VERSION ""

NS_ :

BS_:

BU_: PowertrainControlModule AtmosphericSensor SafetyRestraintSystem2 Aftertreatment_2_GasOutlet Aftertreatment_2_GasIntake DieselParticulateFilterControl Turbocharger SafetyRestraintSystem1 CabDisplay2 Aftertreatment_1_GasOutlet Aftertreatment_1_GasIntake OnBoardDataLogger OffBoardDiagnosticTool2 OffBoardDiagnosticTool1 FileServer ParkingBrakeController SeatController2 FanDriveController SteeringColumnUnit CommunicationUnitRadio CommunicationUnitSatellite CommunicationUnitCellular PropulsionBatteryCharger ChassisController2 ChassisController1 EngineValveControl AuxiliaryHeater2 AuxiliaryHeater1 ClutchUnit RampControl InformationSystem1 SuspensionSystemController2 OilSensor VehicleDynamicStability ExhaustEmissionController TransmissionDisplay2 TransmissionDisplay1 ClimateControl2 WaterPumpController RearAxleSteeringController LightingOperatorControl SeatController1 IgnitionController2 IgnitionController1 TirePressureController CabController2 CabController1 PneumaticSystemController SuspensionSystemController1 HydraulicPumpController EnduranceBrakingSystem RetarderExhaustEngine2 OnBoardDiagnosticUnit HeadwayController RetarderExhaustEngine1 CabDisplay1 ManagementComputer VirtualTerminal OffVehicleGateway PowerTakeOffFront HitchControl AuxiliaryValveControl BodyController TractorTrailerBridge1 StarterSystem ElectricalSystem VehicleSecurity VehicleNavigation AerodynamicControl ElectricalChargingSystem ClimateControl1 TripRecorder InstrumentCluster SuspensionDriveAxle2 SuspensionDriveAxle1 SuspensionSteerAxle SteeringController FuelSystem CruiseControl RetarderDriveline RetarderEngine BrakesDriveAxle2 BrakesDriveAxle1 BrakesSystemController BrakesSteerAxle AxleDrive2 AxleDrive1 AxleSteering PowerTakeOff ShiftConsoleSecondary ShiftConsolePrimary Transmission2 Transmission1 Engine2 Engine1
VAL_TABLE_ FMI 22 "Data Drifted Low" 21 "Data Drifted High" 20 "Received Network Data In Error" 0 "Above normal (most severe)" 1 "Below normal (most severe)" 2 "Data erratic" 3 "Voltage above normal" 4 "Voltage below normal" 5 "Current below normal" 6 "Current above normal" 7 "Mechanical system not responding" 8 "Abnormal frequency" 9 "Abnormal update rate" 10 "Abnormal rate of change" 11 "Root cause not known" 12 "Bad intelligent device" 13 "Out of calibration" 14 "Special intstructions" 15 "Above normal (least severe)" 16 "Above normal (moderately severe)" 17 "Below normal (least severe)" 18 "Below normal (moderately severe)" 19 "Received network data in error" 31 "Condition Exists" ;
VAL_TABLE_ Ports 21 "Global (All ports)" 0 "Local" ;

BO_ 3221225472 VECTOR__INDEPENDENT_SIG_MSG: 0 Vector__XXX
 SG_ NumberOfMembersInWorkingSet : 0|8@1+ (1,0) [0|0] "" Vector__XXX
 SG_ SourceAddress : 0|8@1+ (1,0) [0|0] "" Vector__XXX
 SG_ NncntnuslyMonitoredSystemsStatus : 0|16@1+ (1,0) [0|0] "" Vector__XXX
 SG_ NncntnslyMonitoredSystemsSupport : 0|16@1+ (1,0) [0|0] "" Vector__XXX
 SG_ CntnslyMntrdSystmsSupport_Status : 0|8@1+ (1,0) [0|0] "" Vector__XXX
 SG_ AETCTorqueValue : 0|16@1+ (1,0) [0|64255] "Nm" Vector__XXX
 SG_ TrailerWeight : 0|16@1+ (2,0) [0|128510] "kg" Vector__XXX
 SG_ ReferenceTirePressSetting : 0|8@1+ (8,0) [0|2000] "kPa" Vector__XXX
 SG_ ReferenceTirePress : 0|8@1+ (8,0) [0|2000] "kPa" Vector__XXX
 SG_ TirePressThresholdDetection : 0|3@1+ (1,0) [0|7] "" Vector__XXX
 SG_ TireAirLeakageRate : 0|16@1+ (0.1,0) [0|6425.5] "Pa/s" Vector__XXX
 SG_ CTIWheelEndElectricalFault : 0|2@1+ (1,0) [0|3] "" Vector__XXX
 SG_ CTITireStatus : 0|2@1+ (1,0) [0|3] "" Vector__XXX
 SG_ CTIWheelSensorStatus : 0|2@1+ (1,0) [0|3] "" Vector__XXX
 SG_ TireTemp : 0|16@1+ (0.03125,-273) [-273|1734.96875] "deg C" Vector__XXX
 SG_ TirePress : 0|8@1+ (4,0) [0|1000] "kPa" Vector__XXX
 SG_ EngTurningGearEngaged : 0|2@1+ (1,0) [0|3] "" Vector__XXX
 SG_ AETCSpeedValue : 0|16@1+ (0.125,0) [0|8031.875] "rpm" Vector__XXX

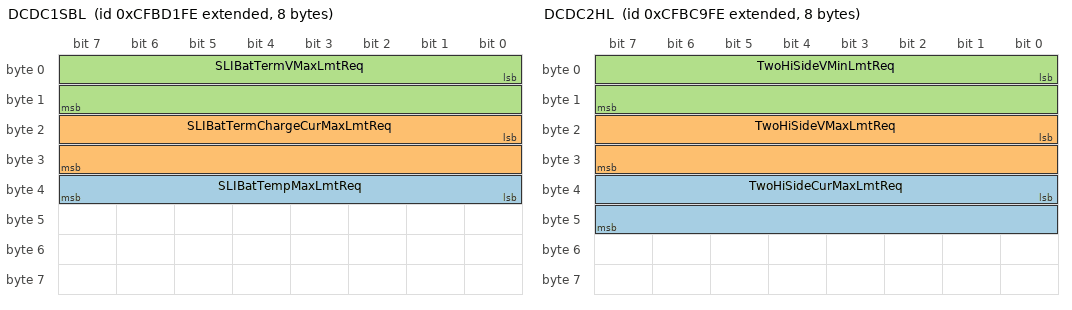
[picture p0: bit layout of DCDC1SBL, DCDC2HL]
BO_ 2365313534 DCDC1SBL: 8 Vector__XXX
 SG_ SLIBatTempMaxLmtReq : 32|8@1+ (1,-40) [-40|210] "캜" Vector__XXX
 SG_ SLIBatTermChargeCurMaxLmtReq : 16|16@1+ (0.05,0) [0|3212.75] "A" Vector__XXX
 SG_ SLIBatTermVMaxLmtReq : 0|16@1+ (0.01,0) [0|642.55] "V" Vector__XXX

BO_ 2566639870 DCDC1CFG1: 19 Vector__XXX
 SG_ OneLowSideVBuckDefaultSetting : 136|16@1+ (0.01,0) [0|642.55] "V" Vector__XXX
 SG_ SLIBatTempMaxLmtSetting : 128|8@1+ (1,-40) [-40|210] "캜" Vector__XXX
 SG_ SLIBatTermChargeCurMaxLmtSetting : 112|16@1+ (0.05,0) [0|3212.75] "A" Vector__XXX
 SG_ SLIBatTermVMaxLmtSetting : 96|16@1+ (0.01,0) [0|642.55] "V" Vector__XXX
 SG_ OneLowSideCurMaxLmtSetting : 80|16@1+ (0.05,0) [0|3212.75] "A" Vector__XXX
 SG_ OneLowSideVMaxLmtSetting : 64|16@1+ (0.01,0) [0|642.55] "V" Vector__XXX
 SG_ OneLowSideVMinLmtSetting : 48|16@1+ (0.01,0) [0|642.55] "V" Vector__XXX
 SG_ OneHiSideCurMaxLmtSetting : 32|16@1+ (0.05,0) [0|3212.75] "A" Vector__XXX
 SG_ OneHiSideVMaxLmtSetting : 16|16@1+ (0.05,0) [0|3212.75] "V" Vector__XXX
 SG_ OneHiSideVMinLmtSetting : 0|16@1+ (0.05,0) [0|3212.75] "V" Vector__XXX

BO_ 2566639614 DCDC1LD: 16 Vector__XXX
 SG_ OneTotalLowSideCharge : 96|32@1+ (100,0) [0|421108121500] "Ah" Vector__XXX
 SG_ OneTotalHiSideCharge : 64|32@1+ (100,0) [0|421108121500] "Ah" Vector__XXX
 SG_ OneTotalLowSideEnergy : 32|32@1+ (100,0) [0|421108121500] "Watt-hour" Vector__XXX
 SG_ OneTotalHiSideEnergy : 0|32@1+ (100,0) [0|421108121500] "Watt-hour" Vector__XXX

BO_ 2633748222 CRSS: 8 Vector__XXX
 SG_ SPNModifiedStatus : 48|2@1+ (1,0) [0|3] "" Vector__XXX
 SG_ SPNSA : 40|8@1+ (1,0) [0|255] "" Vector__XXX
 SG_ SPNDetailedStatus : 32|5@1+ (1,0) [0|31] "" Vector__XXX
 SG_ SPN : 16|19@1+ (1,0) [0|524287] "" Vector__XXX
 SG_ PortCmdStatus : 5|3@1+ (1,0) [0|7] "" Vector__XXX
 SG_ PortPendingChangesStatus : 4|1@1+ (1,0) [0|1] "" Vector__XXX
 SG_ Port : 0|4@1+ (1,0) [0|15] "" Vector__XXX

BO_ 2566639102 WSPT2: 19 Vector__XXX
 SG_ PlungerFiringOrderSetting : 144|4@1+ (1,0) [0|15] "" Vector__XXX
 SG_ RodLoadHiThreshold : 128|16@1+ (5,0) [0|321275] "kN" Vector__XXX
 SG_ CrankshaftSpdHiThreshold : 112|16@1+ (0.125,0) [0|8031.875] "rpm" Vector__XXX
 SG_ CrankshaftSpdLowThreshold : 96|16@1+ (0.125,0) [0|8031.875] "rpm" Vector__XXX
 SG_ DisPressHiThreshold : 80|16@1+ (5,0) [0|321275] "kPa" Vector__XXX
 SG_ SuctionPressHiThreshold : 64|16@1+ (0.1,-3212.7) [-3212.7|3212.8] "kPa" Vector__XXX
 SG_ SuctionPressLowThreshold : 48|16@1+ (0.1,-3212.7) [-3212.7|3212.8] "kPa" Vector__XXX
 SG_ GearBoxOilTempHiThreshold : 40|8@1+ (1,-40) [-40|210] "캜" Vector__XXX
 SG_ GearBoxOilTempLowThreshold : 32|8@1+ (1,-40) [-40|210] "캜" Vector__XXX
 SG_ GearBoxOilPressHiThreshold : 16|16@1+ (0.1,0) [0|6425.5] "kPa" Vector__XXX
 SG_ GearBoxOilPressLowThreshold : 0|16@1+ (0.1,0) [0|6425.5] "kPa" Vector__XXX

BO_ 2566638846 WSPH: 16 Vector__XXX
 SG_ VlvSeatOpHours : 96|32@1+ (1,0) [0|4211081215] "s" Vector__XXX
 SG_ PackingOpHours : 64|32@1+ (1,0) [0|4211081215] "s" Vector__XXX
 SG_ VlvOpHours : 32|32@1+ (1,0) [0|4211081215] "s" Vector__XXX
 SG_ MaintenanceIntervalHours : 0|32@1+ (1,0) [0|4211081215] "s" Vector__XXX

BO_ 2566638590 EEPCSI: 8 Vector__XXX
 SG_ DiagCount : 32|32@1+ (1,0) [0|4211081215] "" Vector__XXX
 SG_ DiagTime : 0|32@1+ (1,0) [0|4211081215] "s" Vector__XXX

BO_ 2365311486 DCDC2HL: 8 Vector__XXX
 SG_ TwoHiSideCurMaxLmtReq : 32|16@1+ (0.05,0) [0|3212.75] "A" Vector__XXX
 SG_ TwoHiSideVMaxLmtReq : 16|16@1+ (0.05,0) [0|3212.75] "V" Vector__XXX
 SG_ TwoHiSideVMinLmtReq : 0|16@1+ (0.05,0) [0|3212.75] "V" Vector__XXX

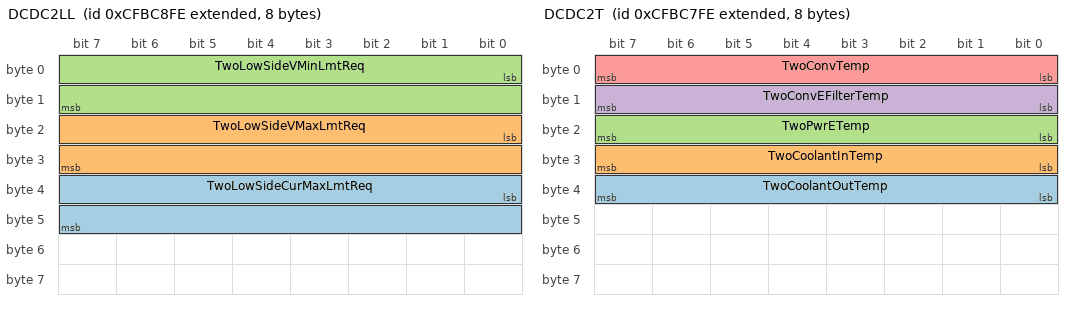
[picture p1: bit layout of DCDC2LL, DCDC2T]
BO_ 2365311230 DCDC2LL: 8 Vector__XXX
 SG_ TwoLowSideCurMaxLmtReq : 32|16@1+ (0.05,0) [0|3212.75] "A" Vector__XXX
 SG_ TwoLowSideVMaxLmtReq : 16|16@1+ (0.01,0) [0|642.55] "V" Vector__XXX
 SG_ TwoLowSideVMinLmtReq : 0|16@1+ (0.01,0) [0|642.55] "V" Vector__XXX

BO_ 2365310974 DCDC2T: 8 Vector__XXX
 SG_ TwoCoolantOutTemp : 32|8@1+ (1,-40) [-40|210] "캜" Vector__XXX
 SG_ TwoCoolantInTemp : 24|8@1+ (1,-40) [-40|210] "캜" Vector__XXX
 SG_ TwoPwrETemp : 16|8@1+ (1,-40) [-40|210] "캜" Vector__XXX
 SG_ TwoConvEFilterTemp : 8|8@1+ (1,-40) [-40|210] "캜" Vector__XXX
 SG_ TwoConvTemp : 0|8@1+ (1,-40) [-40|210] "캜" Vector__XXX

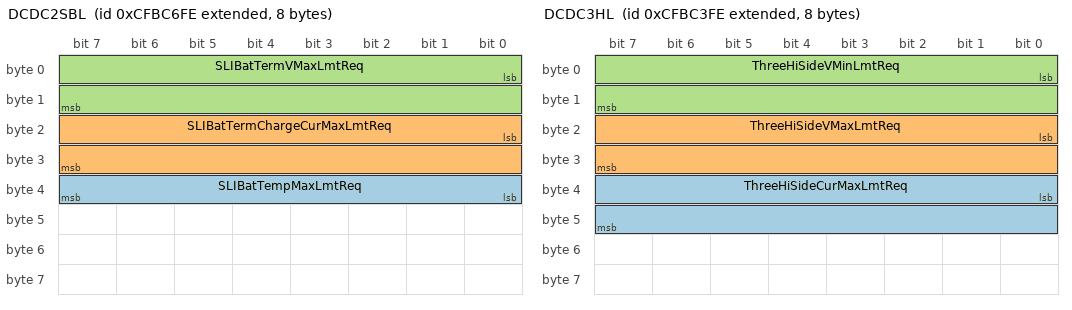
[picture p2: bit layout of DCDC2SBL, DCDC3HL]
BO_ 2365310718 DCDC2SBL: 8 Vector__XXX
 SG_ SLIBatTempMaxLmtReq : 32|8@1+ (1,-40) [-40|210] "캜" Vector__XXX
 SG_ SLIBatTermChargeCurMaxLmtReq : 16|16@1+ (0.05,0) [0|3212.75] "A" Vector__XXX
 SG_ SLIBatTermVMaxLmtReq : 0|16@1+ (0.01,0) [0|642.55] "V" Vector__XXX

BO_ 2566637054 DCDC2CFG1: 19 Vector__XXX
 SG_ TwoLowSideVBuckDefaultSetting : 136|16@1+ (0.01,0) [0|642.55] "V" Vector__XXX
 SG_ SLIBatTempMaxLmtSetting : 128|8@1+ (1,-40) [-40|210] "캜" Vector__XXX
 SG_ SLIBatTermChargeCurMaxLmtSetting : 112|16@1+ (0.05,0) [0|3212.75] "A" Vector__XXX
 SG_ SLIBatTermVMaxLmtSetting : 96|16@1+ (0.01,0) [0|642.55] "V" Vector__XXX
 SG_ TwoLowSideCurMaxLmtSetting : 80|16@1+ (0.05,0) [0|3212.75] "A" Vector__XXX
 SG_ TwoLowSideVMaxLmtSetting : 64|16@1+ (0.01,0) [0|642.55] "V" Vector__XXX
 SG_ TwoLowSideVMinLmtSetting : 48|16@1+ (0.01,0) [0|642.55] "V" Vector__XXX
 SG_ TwoHiSideCurMaxLmtSetting : 32|16@1+ (0.05,0) [0|3212.75] "A" Vector__XXX
 SG_ TwoHiSideVMaxLmtSetting : 16|16@1+ (0.05,0) [0|3212.75] "V" Vector__XXX
 SG_ TwoHiSideVMinLmtSetting : 0|16@1+ (0.05,0) [0|3212.75] "V" Vector__XXX

BO_ 2566636798 DCDC2LD: 16 Vector__XXX
 SG_ TwoTotalLowSideCharge : 96|32@1+ (100,0) [0|421108121500] "Ah" Vector__XXX
 SG_ TwoTotalHiSideCharge : 64|32@1+ (100,0) [0|421108121500] "Ah" Vector__XXX
 SG_ TwoTotalLowSideEnergy : 32|32@1+ (100,0) [0|421108121500] "Watt-hour" Vector__XXX
 SG_ TwoTotalHiSideEnergy : 0|32@1+ (100,0) [0|421108121500] "Watt-hour" Vector__XXX

BO_ 2365309950 DCDC3HL: 8 Vector__XXX
 SG_ ThreeHiSideCurMaxLmtReq : 32|16@1+ (0.05,0) [0|3212.75] "A" Vector__XXX
 SG_ ThreeHiSideVMaxLmtReq : 16|16@1+ (0.05,0) [0|3212.75] "V" Vector__XXX
 SG_ ThreeHiSideVMinLmtReq : 0|16@1+ (0.05,0) [0|3212.75] "V" Vector__XXX

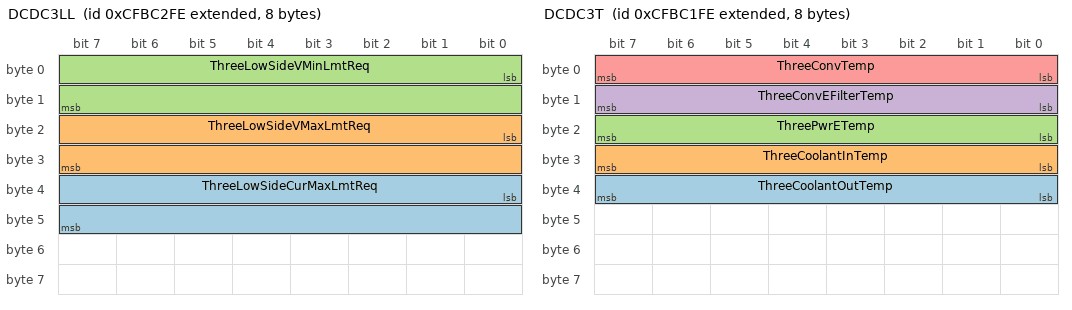
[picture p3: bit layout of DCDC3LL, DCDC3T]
BO_ 2365309694 DCDC3LL: 8 Vector__XXX
 SG_ ThreeLowSideCurMaxLmtReq : 32|16@1+ (0.05,0) [0|3212.75] "A" Vector__XXX
 SG_ ThreeLowSideVMaxLmtReq : 16|16@1+ (0.01,0) [0|642.55] "V" Vector__XXX
 SG_ ThreeLowSideVMinLmtReq : 0|16@1+ (0.01,0) [0|642.55] "V" Vector__XXX

BO_ 2365309438 DCDC3T: 8 Vector__XXX
 SG_ ThreeCoolantOutTemp : 32|8@1+ (1,-40) [-40|210] "캜" Vector__XXX
 SG_ ThreeCoolantInTemp : 24|8@1+ (1,-40) [-40|210] "캜" Vector__XXX
 SG_ ThreePwrETemp : 16|8@1+ (1,-40) [-40|210] "캜" Vector__XXX
 SG_ ThreeConvEFilterTemp : 8|8@1+ (1,-40) [-40|210] "캜" Vector__XXX
 SG_ ThreeConvTemp : 0|8@1+ (1,-40) [-40|210] "캜" Vector__XXX

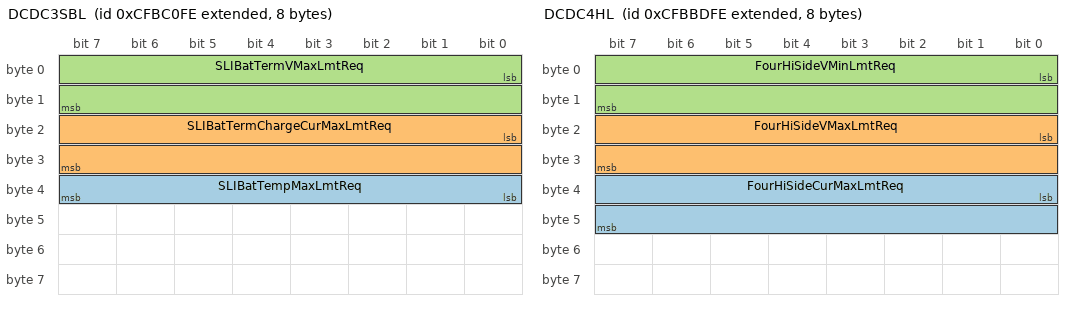
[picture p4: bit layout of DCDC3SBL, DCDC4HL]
BO_ 2365309182 DCDC3SBL: 8 Vector__XXX
 SG_ SLIBatTempMaxLmtReq : 32|8@1+ (1,-40) [-40|210] "캜" Vector__XXX
 SG_ SLIBatTermChargeCurMaxLmtReq : 16|16@1+ (0.05,0) [0|3212.75] "A" Vector__XXX
 SG_ SLIBatTermVMaxLmtReq : 0|16@1+ (0.01,0) [0|642.55] "V" Vector__XXX

BO_ 2566635518 DCDC3CFG1: 19 Vector__XXX
 SG_ ThreeLowSideVBuckDefaultSetting : 136|16@1+ (0.01,0) [0|642.55] "V" Vector__XXX
 SG_ SLIBatTempMaxLmtSetting : 128|8@1+ (1,-40) [-40|210] "캜" Vector__XXX
 SG_ SLIBatTermChargeCurMaxLmtSetting : 112|16@1+ (0.05,0) [0|3212.75] "A" Vector__XXX
 SG_ SLIBatTermVMaxLmtSetting : 96|16@1+ (0.01,0) [0|642.55] "V" Vector__XXX
 SG_ ThreeLowSideCurMaxLmtSetting : 80|16@1+ (0.05,0) [0|3212.75] "A" Vector__XXX
 SG_ ThreeLowSideVMaxLmtSetting : 64|16@1+ (0.01,0) [0|642.55] "V" Vector__XXX
 SG_ ThreeLowSideVMinLmtSetting : 48|16@1+ (0.01,0) [0|642.55] "V" Vector__XXX
 SG_ ThreeHiSideCurMaxLmtSetting : 32|16@1+ (0.05,0) [0|3212.75] "A" Vector__XXX
 SG_ ThreeHiSideVMaxLmtSetting : 16|16@1+ (0.05,0) [0|3212.75] "V" Vector__XXX
 SG_ ThreeHiSideVMinLmtSetting : 0|16@1+ (0.05,0) [0|3212.75] "V" Vector__XXX

BO_ 2566635262 DCDC3LD: 16 Vector__XXX
 SG_ ThreeTotalLowSideCharge : 96|32@1+ (100,0) [0|421108121500] "Ah" Vector__XXX
 SG_ ThreeTotalHiSideCharge : 64|32@1+ (100,0) [0|421108121500] "Ah" Vector__XXX
 SG_ ThreeTotalLowSideEnergy : 32|32@1+ (100,0) [0|421108121500] "Watt-hour" Vector__XXX
 SG_ ThreeTotalHiSideEnergy : 0|32@1+ (100,0) [0|421108121500] "Watt-hour" Vector__XXX

BO_ 2365308414 DCDC4HL: 8 Vector__XXX
 SG_ FourHiSideCurMaxLmtReq : 32|16@1+ (0.05,0) [0|3212.75] "A" Vector__XXX
 SG_ FourHiSideVMaxLmtReq : 16|16@1+ (0.05,0) [0|3212.75] "V" Vector__XXX
 SG_ FourHiSideVMinLmtReq : 0|16@1+ (0.05,0) [0|3212.75] "V" Vector__XXX

BO_ 2365308158 DCDC4LL: 8 Vector__XXX
 SG_ FourLowSideCurMaxLmtReq : 32|16@1+ (0.05,0) [0|3212.75] "A" Vector__XXX
 SG_ FourLowSideVMaxLmtReq : 16|16@1+ (0.01,0) [0|642.55] "V" Vector__XXX
 SG_ FourLowSideVMinLmtReq : 0|16@1+ (0.01,0) [0|642.55] "V" Vector__XXX

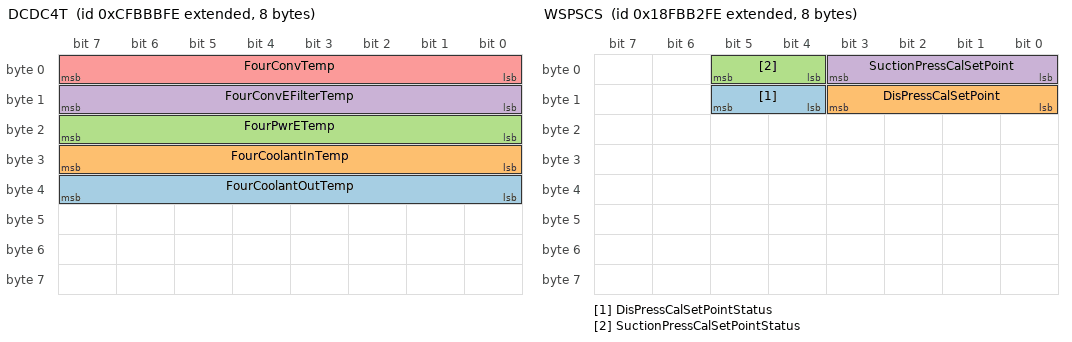
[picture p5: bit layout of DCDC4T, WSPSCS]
BO_ 2365307902 DCDC4T: 8 Vector__XXX
 SG_ FourCoolantOutTemp : 32|8@1+ (1,-40) [-40|210] "캜" Vector__XXX
 SG_ FourCoolantInTemp : 24|8@1+ (1,-40) [-40|210] "캜" Vector__XXX
 SG_ FourPwrETemp : 16|8@1+ (1,-40) [-40|210] "캜" Vector__XXX
 SG_ FourConvEFilterTemp : 8|8@1+ (1,-40) [-40|210] "캜" Vector__XXX
 SG_ FourConvTemp : 0|8@1+ (1,-40) [-40|210] "캜" Vector__XXX

BO_ 2365307646 DCDC4SBL: 8 Vector__XXX
 SG_ SLIBatTempMaxLmtReq : 32|8@1+ (1,-40) [-40|210] "캜" Vector__XXX
 SG_ SLIBatTermChargeCurMaxLmtReq : 16|16@1+ (0.05,0) [0|3212.75] "A" Vector__XXX
 SG_ SLIBatTermVMaxLmtReq : 0|16@1+ (0.01,0) [0|642.55] "V" Vector__XXX

BO_ 2566633982 DCDC4CFG1: 19 Vector__XXX
 SG_ FourLowSideVBuckDefaultSetting : 136|16@1+ (0.01,0) [0|642.55] "V" Vector__XXX
 SG_ SLIBatTempMaxLmtSetting : 128|8@1+ (1,-40) [-40|210] "캜" Vector__XXX
 SG_ SLIBatTermChargeCurMaxLmtSetting : 112|16@1+ (0.05,0) [0|3212.75] "A" Vector__XXX
 SG_ SLIBatTermVMaxLmtSetting : 96|16@1+ (0.01,0) [0|642.55] "V" Vector__XXX
 SG_ FourLowSideCurMaxLmtSetting : 80|16@1+ (0.05,0) [0|3212.75] "A" Vector__XXX
 SG_ FourLowSideVMaxLmtSetting : 64|16@1+ (0.01,0) [0|642.55] "V" Vector__XXX
 SG_ FourLowSideVMinLmtSetting : 48|16@1+ (0.01,0) [0|642.55] "V" Vector__XXX
 SG_ FourHiSideCurMaxLmtSetting : 32|16@1+ (0.05,0) [0|3212.75] "A" Vector__XXX
 SG_ FourHiSideVMaxLmtSetting : 16|16@1+ (0.05,0) [0|3212.75] "V" Vector__XXX
 SG_ FourHiSideVMinLmtSetting : 0|16@1+ (0.05,0) [0|3212.75] "V" Vector__XXX

BO_ 2566633726 DCDC4LD: 16 Vector__XXX
 SG_ FourTotalLowSideCharge : 96|32@1+ (100,0) [0|421108121500] "Ah" Vector__XXX
 SG_ FourTotalHiSideCharge : 64|32@1+ (100,0) [0|421108121500] "Ah" Vector__XXX
 SG_ FourTotalLowSideEnergy : 32|32@1+ (100,0) [0|421108121500] "Watt-hour" Vector__XXX
 SG_ FourTotalHiSideEnergy : 0|32@1+ (100,0) [0|421108121500] "Watt-hour" Vector__XXX

BO_ 2566633470 AT1IG4: 8 Vector__XXX
 SG_ O2PumpingCur : 0|16@1+ (0.001,-32.127) [-32.127|32.128] "mA" Vector__XXX

BO_ 2566633214 AT1OG4: 8 Vector__XXX
 SG_ O2PumpingCur : 0|16@1+ (0.001,-32.127) [-32.127|32.128] "mA" Vector__XXX

BO_ 2566632958 WSPH2: 8 Vector__XXX
 SG_ PwrEndTripHours : 32|32@1+ (1,0) [0|4211081215] "s" Vector__XXX
 SG_ FluidEndTripHours : 0|32@1+ (1,0) [0|4211081215] "s" Vector__XXX

BO_ 2566632702 WSPSN: 8 Vector__XXX
 SG_ FluidEndSerialNum : 8|8@1+ (1,0) [0|255] "" Vector__XXX
 SG_ PwrEndSerialNum : 0|8@1+ (1,0) [0|255] "" Vector__XXX

BO_ 2566632446 WSPFV: 8 Vector__XXX
 SG_ TripFluidPumped : 32|32@1+ (0.5,0) [0|2105540607.5] "l" Vector__XXX
 SG_ TotalFluidPumped : 0|32@1+ (0.5,0) [0|2105540607.5] "l" Vector__XXX

BO_ 2566632190 WSPSCS: 8 Vector__XXX
 SG_ DisPressCalSetPointStatus : 12|2@1+ (1,0) [0|3] "" Vector__XXX
 SG_ DisPressCalSetPoint : 8|4@1+ (1,0) [0|15] "" Vector__XXX
 SG_ SuctionPressCalSetPointStatus : 4|2@1+ (1,0) [0|3] "" Vector__XXX
 SG_ SuctionPressCalSetPoint : 0|4@1+ (1,0) [0|15] "" Vector__XXX

BO_ 2566631934 DCAC_AI5_LD: 8 Vector__XXX
 SG_ TotalDCInputEnergy : 32|32@1+ (100,0) [0|421108121500] "Watt-hour" Vector__XXX
 SG_ TotalDCInputCharge : 0|32@1+ (100,0) [0|421108121500] "Ah" Vector__XXX

BO_ 2566631678 DCAC_AI5_CFG1: 13 Vector__XXX
 SG_ ACSideDefaultFreqCmdSetting : 96|8@1+ (1,0) [0|250] "Hz" Vector__XXX
 SG_ DCSideCurMinLmtSetting : 80|16@1+ (0.05,-3212.75) [-3212.75|0] "A" Vector__XXX
 SG_ DCSideVMaxLmtSetting : 64|16@1+ (0.05,0) [0|3212.75] "V" Vector__XXX
 SG_ ACSideRMSCurMaxLmtSetting : 48|16@1+ (0.03125,0) [0|2007.96875] "Arms" Vector__XXX
 SG_ ACSideRMSVMaxLmtSetting : 32|16@1+ (0.03125,0) [0|2007.96875] "Vrms" Vector__XXX
 SG_ DCSideCurMaxLmtSetting : 16|16@1+ (0.05,0) [0|3212.75] "A" Vector__XXX
 SG_ DCSideVMinLmtSetting : 0|16@1+ (0.05,0) [0|3212.75] "V" Vector__XXX

BO_ 2365304830 DCAC_AI5_ACL: 8 Vector__XXX
 SG_ DefaultFreqReq : 32|8@1+ (1,0) [0|250] "Hz" Vector__XXX
 SG_ RMSCurMaxLmtReq : 16|16@1+ (0.03125,0) [0|2007.96875] "Arms" Vector__XXX
 SG_ RMSVMaxLmtReq : 0|16@1+ (0.03125,0) [0|2007.96875] "Vrms" Vector__XXX

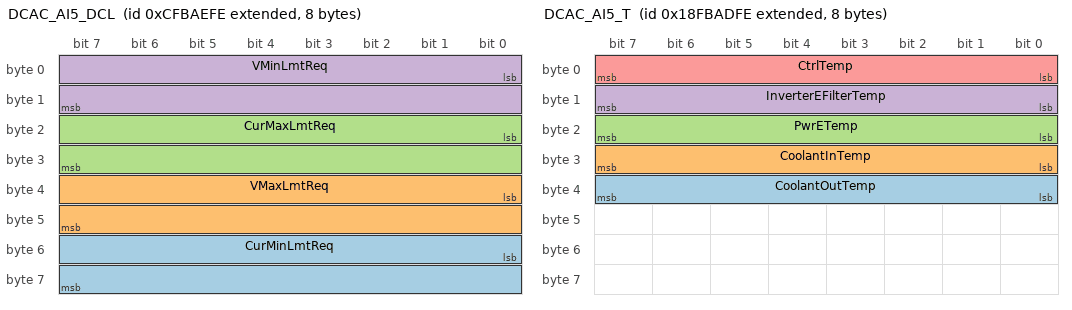
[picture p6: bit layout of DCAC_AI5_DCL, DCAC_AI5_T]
BO_ 2365304574 DCAC_AI5_DCL: 8 Vector__XXX
 SG_ CurMinLmtReq : 48|16@1+ (0.05,-3212.75) [-3212.75|0] "A" Vector__XXX
 SG_ VMaxLmtReq : 32|16@1+ (0.05,0) [0|3212.75] "V" Vector__XXX
 SG_ CurMaxLmtReq : 16|16@1+ (0.05,0) [0|3212.75] "A" Vector__XXX
 SG_ VMinLmtReq : 0|16@1+ (0.05,0) [0|3212.75] "V" Vector__XXX

BO_ 2566630910 DCAC_AI5_T: 8 Vector__XXX
 SG_ CoolantOutTemp : 32|8@1+ (1,-40) [-40|210] "캜" Vector__XXX
 SG_ CoolantInTemp : 24|8@1+ (1,-40) [-40|210] "캜" Vector__XXX
 SG_ PwrETemp : 16|8@1+ (1,-40) [-40|210] "캜" Vector__XXX
 SG_ InverterEFilterTemp : 8|8@1+ (1,-40) [-40|210] "캜" Vector__XXX
 SG_ CtrlTemp : 0|8@1+ (1,-40) [-40|210] "캜" Vector__XXX

BO_ 2566630654 DCAC_AI4_LD: 8 Vector__XXX
 SG_ TotalDCInputEnergy : 32|32@1+ (100,0) [0|421108121500] "Watt-hour" Vector__XXX
 SG_ TotalDCInputCharge : 0|32@1+ (100,0) [0|421108121500] "Ah" Vector__XXX

BO_ 2566630398 DCAC_AI4_CFG1: 13 Vector__XXX
 SG_ ACSideDefaultFreqCmdSetting : 96|8@1+ (1,0) [0|250] "Hz" Vector__XXX
 SG_ DCSideCurMinLmtSetting : 80|16@1+ (0.05,-3212.75) [-3212.75|0] "A" Vector__XXX
 SG_ DCSideVMaxLmtSetting : 64|16@1+ (0.05,0) [0|3212.75] "V" Vector__XXX
 SG_ ACSideRMSCurMaxLmtSetting : 48|16@1+ (0.03125,0) [0|2007.96875] "Arms" Vector__XXX
 SG_ ACSideRMSVMaxLmtSetting : 32|16@1+ (0.03125,0) [0|2007.96875] "Vrms" Vector__XXX
 SG_ DCSideCurMaxLmtSetting : 16|16@1+ (0.05,0) [0|3212.75] "A" Vector__XXX
 SG_ DCSideVMinLmtSetting : 0|16@1+ (0.05,0) [0|3212.75] "V" Vector__XXX

BO_ 2365303550 DCAC_AI4_ACL: 8 Vector__XXX
 SG_ DefaultFreqReq : 32|8@1+ (1,0) [0|250] "Hz" Vector__XXX
 SG_ RMSCurMaxLmtReq : 16|16@1+ (0.03125,0) [0|2007.96875] "Arms" Vector__XXX
 SG_ RMSVMaxLmtReq : 0|16@1+ (0.03125,0) [0|2007.96875] "Vrms" Vector__XXX

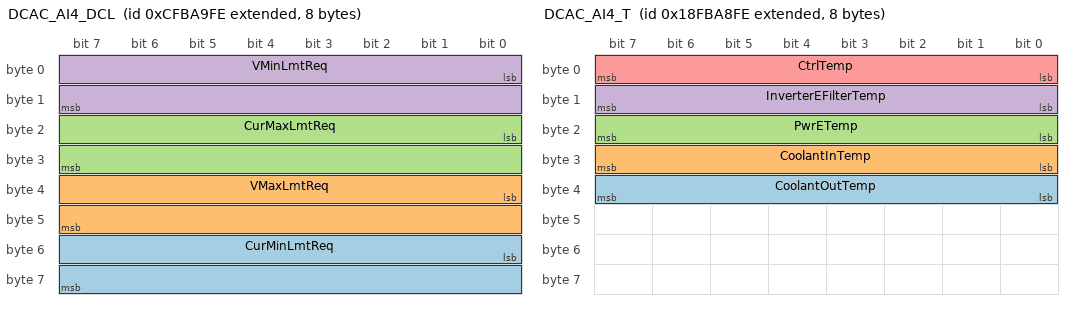
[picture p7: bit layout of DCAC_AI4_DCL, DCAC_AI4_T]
BO_ 2365303294 DCAC_AI4_DCL: 8 Vector__XXX
 SG_ CurMinLmtReq : 48|16@1+ (0.05,-3212.75) [-3212.75|0] "A" Vector__XXX
 SG_ VMaxLmtReq : 32|16@1+ (0.05,0) [0|3212.75] "V" Vector__XXX
 SG_ CurMaxLmtReq : 16|16@1+ (0.05,0) [0|3212.75] "A" Vector__XXX
 SG_ VMinLmtReq : 0|16@1+ (0.05,0) [0|3212.75] "V" Vector__XXX

BO_ 2566629630 DCAC_AI4_T: 8 Vector__XXX
 SG_ CoolantOutTemp : 32|8@1+ (1,-40) [-40|210] "캜" Vector__XXX
 SG_ CoolantInTemp : 24|8@1+ (1,-40) [-40|210] "캜" Vector__XXX
 SG_ PwrETemp : 16|8@1+ (1,-40) [-40|210] "캜" Vector__XXX
 SG_ InverterEFilterTemp : 8|8@1+ (1,-40) [-40|210] "캜" Vector__XXX
 SG_ CtrlTemp : 0|8@1+ (1,-40) [-40|210] "캜" Vector__XXX

BO_ 2566629374 DCAC_AI3_LD: 8 Vector__XXX
 SG_ TotalDCInputEnergy : 32|32@1+ (100,0) [0|421108121500] "Watt-hour" Vector__XXX
 SG_ TotalDCInputCharge : 0|32@1+ (100,0) [0|421108121500] "Ah" Vector__XXX

BO_ 2566629118 DCAC_AI3_CFG1: 13 Vector__XXX
 SG_ ACSideDefaultFreqCmdSetting : 96|8@1+ (1,0) [0|250] "Hz" Vector__XXX
 SG_ DCSideCurMinLmtSetting : 80|16@1+ (0.05,-3212.75) [-3212.75|0] "A" Vector__XXX
 SG_ DCSideVMaxLmtSetting : 64|16@1+ (0.05,0) [0|3212.75] "V" Vector__XXX
 SG_ ACSideRMSCurMaxLmtSetting : 48|16@1+ (0.03125,0) [0|2007.96875] "Arms" Vector__XXX
 SG_ ACSideRMSVMaxLmtSetting : 32|16@1+ (0.03125,0) [0|2007.96875] "Vrms" Vector__XXX
 SG_ DCSideCurMaxLmtSetting : 16|16@1+ (0.05,0) [0|3212.75] "A" Vector__XXX
 SG_ DCSideVMinLmtSetting : 0|16@1+ (0.05,0) [0|3212.75] "V" Vector__XXX

BO_ 2365302270 DCAC_AI3_ACL: 8 Vector__XXX
 SG_ DefaultFreqReq : 32|8@1+ (1,0) [0|250] "Hz" Vector__XXX
 SG_ RMSCurMaxLmtReq : 16|16@1+ (0.03125,0) [0|2007.96875] "Arms" Vector__XXX
 SG_ RMSVMaxLmtReq : 0|16@1+ (0.03125,0) [0|2007.96875] "Vrms" Vector__XXX

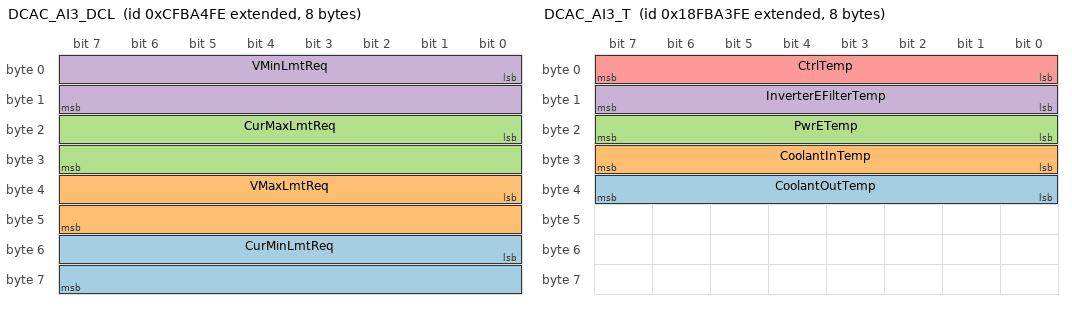
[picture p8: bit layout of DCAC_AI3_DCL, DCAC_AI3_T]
BO_ 2365302014 DCAC_AI3_DCL: 8 Vector__XXX
 SG_ CurMinLmtReq : 48|16@1+ (0.05,-3212.75) [-3212.75|0] "A" Vector__XXX
 SG_ VMaxLmtReq : 32|16@1+ (0.05,0) [0|3212.75] "V" Vector__XXX
 SG_ CurMaxLmtReq : 16|16@1+ (0.05,0) [0|3212.75] "A" Vector__XXX
 SG_ VMinLmtReq : 0|16@1+ (0.05,0) [0|3212.75] "V" Vector__XXX

BO_ 2566628350 DCAC_AI3_T: 8 Vector__XXX
 SG_ CoolantOutTemp : 32|8@1+ (1,-40) [-40|210] "캜" Vector__XXX
 SG_ CoolantInTemp : 24|8@1+ (1,-40) [-40|210] "캜" Vector__XXX
 SG_ PwrETemp : 16|8@1+ (1,-40) [-40|210] "캜" Vector__XXX
 SG_ InverterEFilterTemp : 8|8@1+ (1,-40) [-40|210] "캜" Vector__XXX
 SG_ CtrlTemp : 0|8@1+ (1,-40) [-40|210] "캜" Vector__XXX

BO_ 2566628094 DCAC_AI2_LD: 8 Vector__XXX
 SG_ TotalDCInputEnergy : 32|32@1+ (100,0) [0|421108121500] "Watt-hour" Vector__XXX
 SG_ TotalDCInputCharge : 0|32@1+ (100,0) [0|421108121500] "Ah" Vector__XXX

BO_ 2566627838 DCAC_AI2_CFG1: 13 Vector__XXX
 SG_ ACSideDefaultFreqCmdSetting : 96|8@1+ (1,0) [0|250] "Hz" Vector__XXX
 SG_ DCSideCurMinLmtSetting : 80|16@1+ (0.05,-3212.75) [-3212.75|0] "A" Vector__XXX
 SG_ DCSideVMaxLmtSetting : 64|16@1+ (0.05,0) [0|3212.75] "V" Vector__XXX
 SG_ ACSideRMSCurMaxLmtSetting : 48|16@1+ (0.03125,0) [0|2007.96875] "Arms" Vector__XXX
 SG_ ACSideRMSVMaxLmtSetting : 32|16@1+ (0.03125,0) [0|2007.96875] "Vrms" Vector__XXX
 SG_ DCSideCurMaxLmtSetting : 16|16@1+ (0.05,0) [0|3212.75] "A" Vector__XXX
 SG_ DCSideVMinLmtSetting : 0|16@1+ (0.05,0) [0|3212.75] "V" Vector__XXX

BO_ 2365300990 DCAC_AI2_ACL: 8 Vector__XXX
 SG_ DefaultFreqReq : 32|8@1+ (1,0) [0|250] "Hz" Vector__XXX
 SG_ RMSCurMaxLmtReq : 16|16@1+ (0.03125,0) [0|2007.96875] "Arms" Vector__XXX
 SG_ RMSVMaxLmtReq : 0|16@1+ (0.03125,0) [0|2007.96875] "Vrms" Vector__XXX

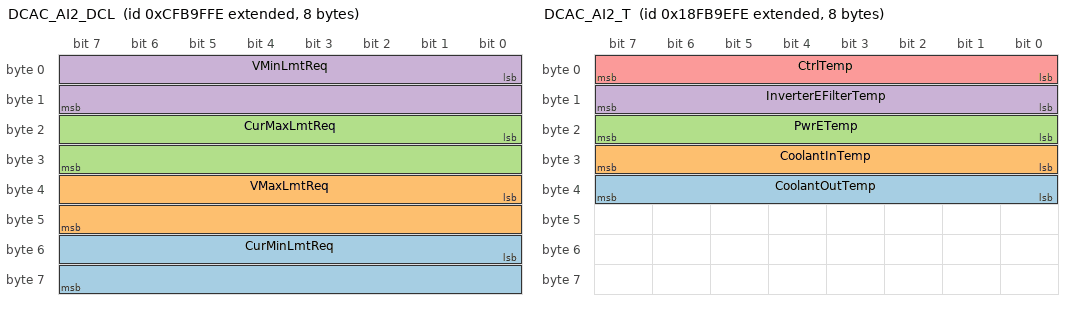
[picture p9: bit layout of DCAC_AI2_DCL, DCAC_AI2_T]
BO_ 2365300734 DCAC_AI2_DCL: 8 Vector__XXX
 SG_ CurMinLmtReq : 48|16@1+ (0.05,-3212.75) [-3212.75|0] "A" Vector__XXX
 SG_ VMaxLmtReq : 32|16@1+ (0.05,0) [0|3212.75] "V" Vector__XXX
 SG_ CurMaxLmtReq : 16|16@1+ (0.05,0) [0|3212.75] "A" Vector__XXX
 SG_ VMinLmtReq : 0|16@1+ (0.05,0) [0|3212.75] "V" Vector__XXX

BO_ 2566627070 DCAC_AI2_T: 8 Vector__XXX
 SG_ CoolantOutTemp : 32|8@1+ (1,-40) [-40|210] "캜" Vector__XXX
 SG_ CoolantInTemp : 24|8@1+ (1,-40) [-40|210] "캜" Vector__XXX
 SG_ PwrETemp : 16|8@1+ (1,-40) [-40|210] "캜" Vector__XXX
 SG_ InverterEFilterTemp : 8|8@1+ (1,-40) [-40|210] "캜" Vector__XXX
 SG_ CtrlTemp : 0|8@1+ (1,-40) [-40|210] "캜" Vector__XXX

BO_ 2566626814 DCAC_AI1_LD: 8 Vector__XXX
 SG_ TotalDCInputEnergy : 32|32@1+ (100,0) [0|421108121500] "Watt-hour" Vector__XXX
 SG_ TotalDCInputCharge : 0|32@1+ (100,0) [0|421108121500] "Ah" Vector__XXX

BO_ 2566626558 DCAC_AI1_CFG1: 13 Vector__XXX
 SG_ ACSideDefaultFreqCmdSetting : 96|8@1+ (1,0) [0|250] "Hz" Vector__XXX
 SG_ DCSideCurMinLmtSetting : 80|16@1+ (0.05,-3212.75) [-3212.75|0] "A" Vector__XXX
 SG_ DCSideVMaxLmtSetting : 64|16@1+ (0.05,0) [0|3212.75] "V" Vector__XXX
 SG_ ACSideRMSCurMaxLmtSetting : 48|16@1+ (0.03125,0) [0|2007.96875] "Arms" Vector__XXX
 SG_ ACSideRMSVMaxLmtSetting : 32|16@1+ (0.03125,0) [0|2007.96875] "Vrms" Vector__XXX
 SG_ DCSideCurMaxLmtSetting : 16|16@1+ (0.05,0) [0|3212.75] "A" Vector__XXX
 SG_ DCSideVMinLmtSetting : 0|16@1+ (0.05,0) [0|3212.75] "V" Vector__XXX

BO_ 2365299710 DCAC_AI1_ACL: 8 Vector__XXX
 SG_ DefaultFreqReq : 32|8@1+ (1,0) [0|250] "Hz" Vector__XXX
 SG_ RMSCurMaxLmtReq : 16|16@1+ (0.03125,0) [0|2007.96875] "Arms" Vector__XXX
 SG_ RMSVMaxLmtReq : 0|16@1+ (0.03125,0) [0|2007.96875] "Vrms" Vector__XXX

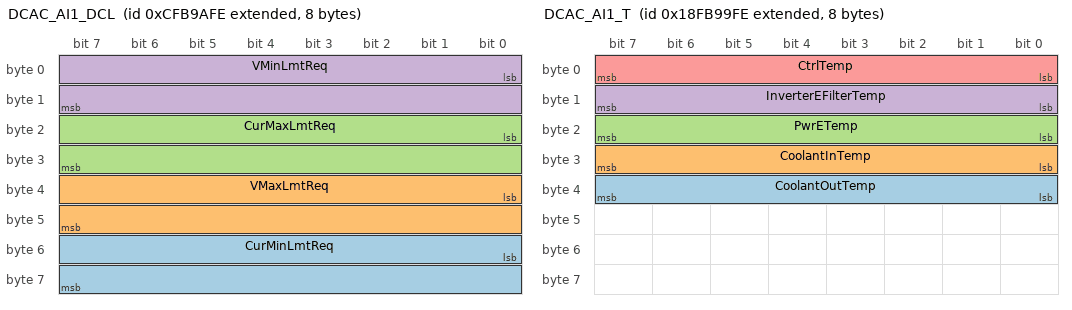
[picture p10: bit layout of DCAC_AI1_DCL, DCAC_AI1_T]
BO_ 2365299454 DCAC_AI1_DCL: 8 Vector__XXX
 SG_ CurMinLmtReq : 48|16@1+ (0.05,-3212.75) [-3212.75|0] "A" Vector__XXX
 SG_ VMaxLmtReq : 32|16@1+ (0.05,0) [0|3212.75] "V" Vector__XXX
 SG_ CurMaxLmtReq : 16|16@1+ (0.05,0) [0|3212.75] "A" Vector__XXX
 SG_ VMinLmtReq : 0|16@1+ (0.05,0) [0|3212.75] "V" Vector__XXX

BO_ 2566625790 DCAC_AI1_T: 8 Vector__XXX
 SG_ CoolantOutTemp : 32|8@1+ (1,-40) [-40|210] "캜" Vector__XXX
 SG_ CoolantInTemp : 24|8@1+ (1,-40) [-40|210] "캜" Vector__XXX
 SG_ PwrETemp : 16|8@1+ (1,-40) [-40|210] "캜" Vector__XXX
 SG_ InverterEFilterTemp : 8|8@1+ (1,-40) [-40|210] "캜" Vector__XXX
 SG_ CtrlTemp : 0|8@1+ (1,-40) [-40|210] "캜" Vector__XXX

BO_ 2633734398 EO2: 8 Vector__XXX
 SG_ EngActualExh2O2 : 0|16@1+ (0.0025,0) [0|160.6375] "%" Vector__XXX

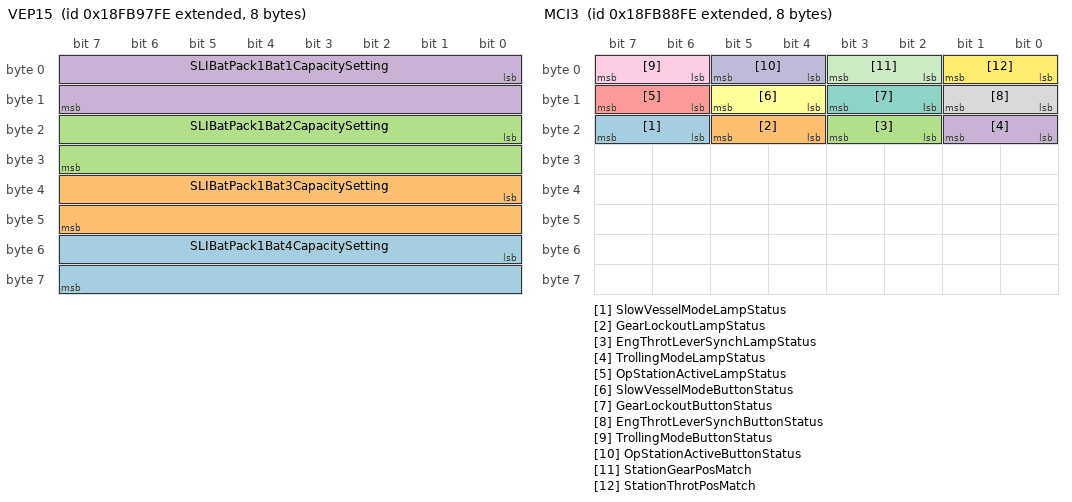
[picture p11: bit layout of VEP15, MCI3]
BO_ 2566625278 VEP15: 8 Vector__XXX
 SG_ SLIBatPack1Bat4CapacitySetting : 48|16@1+ (1,0) [0|64255] "Ah" Vector__XXX
 SG_ SLIBatPack1Bat3CapacitySetting : 32|16@1+ (1,0) [0|64255] "Ah" Vector__XXX
 SG_ SLIBatPack1Bat2CapacitySetting : 16|16@1+ (1,0) [0|64255] "Ah" Vector__XXX
 SG_ SLIBatPack1Bat1CapacitySetting : 0|16@1+ (1,0) [0|64255] "Ah" Vector__XXX

BO_ 2566625022 EI3: 8 Vector__XXX
 SG_ InstantaneousEstEngPwrRateLmt : 0|16@1+ (0.125,0) [0|8031.875] "kW/s" Vector__XXX

BO_ 2566624766 HOURS2: 8 Vector__XXX
 SG_ IdleMnmgtActiveTotalTime : 0|32@1+ (0.05,0) [0|210554060.75] "h" Vector__XXX

BO_ 2566624510 EEC22: 8 Vector__XXX
 SG_ EGR1CoolerInPress : 0|16@1+ (5,0) [0|321275] "kPa" Vector__XXX

BO_ 2365297662 DCDC1V: 8 Vector__XXX
 SG_ OneCtrlInputSLIV : 16|16@1+ (0.05,0) [0|3212.75] "V" Vector__XXX
 SG_ OneCtrlInputIgntV : 0|16@1+ (0.05,0) [0|3212.75] "V" Vector__XXX

BO_ 2365297406 DCDC2V: 8 Vector__XXX
 SG_ TwoCtrlInputSLIV : 16|16@1+ (0.05,0) [0|3212.75] "V" Vector__XXX
 SG_ TwoCtrlInputIgntV : 0|16@1+ (0.05,0) [0|3212.75] "V" Vector__XXX

BO_ 2365297150 DCDC3V: 8 Vector__XXX
 SG_ ThreeCtrlInputSLIV : 16|16@1+ (0.05,0) [0|3212.75] "V" Vector__XXX
 SG_ ThreeCtrlInputIgntV : 0|16@1+ (0.05,0) [0|3212.75] "V" Vector__XXX

BO_ 2365296894 DCDC4V: 8 Vector__XXX
 SG_ FourCtrlInputSLIV : 16|16@1+ (0.05,0) [0|3212.75] "V" Vector__XXX
 SG_ FourCtrlInputIgntV : 0|16@1+ (0.05,0) [0|3212.75] "V" Vector__XXX

BO_ 2566623230 EMEFS: 8 Vector__XXX
 SG_ TripEstFuelSaved : 32|32@1+ (0.5,0) [0|2105540607.5] "l" Vector__XXX
 SG_ TotalEstFuelSaved : 0|32@1+ (0.5,0) [0|2105540607.5] "l" Vector__XXX

BO_ 2566622974 EMFU: 8 Vector__XXX
 SG_ TripFuelUsed : 32|32@1+ (0.5,0) [0|2105540607.5] "l" Vector__XXX
 SG_ TotalFuelUsed : 0|32@1+ (0.5,0) [0|2105540607.5] "l" Vector__XXX

BO_ 2566622718 EMAH: 8 Vector__XXX
 SG_ TripHoursActive : 32|32@1+ (0.05,0) [0|210554060.75] "h" Vector__XXX
 SG_ TotalHoursActive : 0|32@1+ (0.05,0) [0|210554060.75] "h" Vector__XXX

BO_ 2566622462 EMEIFSR: 8 Vector__XXX
 SG_ Percent : 16|16@1+ (0.0025,0) [0|160.6375] "%" Vector__XXX
 SG_ RateAbsolute : 0|16@1+ (0.05,0) [0|3212.75] "l/h" Vector__XXX

BO_ 2566622206 EMIH: 8 Vector__XXX
 SG_ TripHoursInactive : 32|32@1+ (0.05,0) [0|210554060.75] "h" Vector__XXX
 SG_ TotalHoursInactive : 0|32@1+ (0.05,0) [0|210554060.75] "h" Vector__XXX

BO_ 2365295358 HVES1D11: 8 Vector__XXX
 SG_ LvlNegToChassisGroundV : 16|16@1+ (0.05,0) [0|3212.75] "V" Vector__XXX
 SG_ BusVNegToChassisGroundV : 0|16@1+ (0.05,0) [0|3212.75] "V" Vector__XXX

BO_ 2566621694 EFL_P13: 8 Vector__XXX
 SG_ OilPress2 : 0|8@1+ (4,0) [0|1000] "kPa" Vector__XXX

BO_ 2566621438 MCI3: 8 Vector__XXX
 SG_ SlowVesselModeLampStatus : 22|2@1+ (1,0) [0|3] "" Vector__XXX
 SG_ GearLockoutLampStatus : 20|2@1+ (1,0) [0|3] "" Vector__XXX
 SG_ EngThrotLeverSynchLampStatus : 18|2@1+ (1,0) [0|3] "" Vector__XXX
 SG_ TrollingModeLampStatus : 16|2@1+ (1,0) [0|3] "" Vector__XXX
 SG_ OpStationActiveLampStatus : 14|2@1+ (1,0) [0|3] "" Vector__XXX
 SG_ SlowVesselModeButtonStatus : 12|2@1+ (1,0) [0|3] "" Vector__XXX
 SG_ GearLockoutButtonStatus : 10|2@1+ (1,0) [0|3] "" Vector__XXX
 SG_ EngThrotLeverSynchButtonStatus : 8|2@1+ (1,0) [0|3] "" Vector__XXX
 SG_ TrollingModeButtonStatus : 6|2@1+ (1,0) [0|3] "" Vector__XXX
 SG_ OpStationActiveButtonStatus : 4|2@1+ (1,0) [0|3] "" Vector__XXX
 SG_ StationGearPosMatch : 2|2@1+ (1,0) [0|3] "" Vector__XXX
 SG_ StationThrotPosMatch : 0|2@1+ (1,0) [0|3] "" Vector__XXX

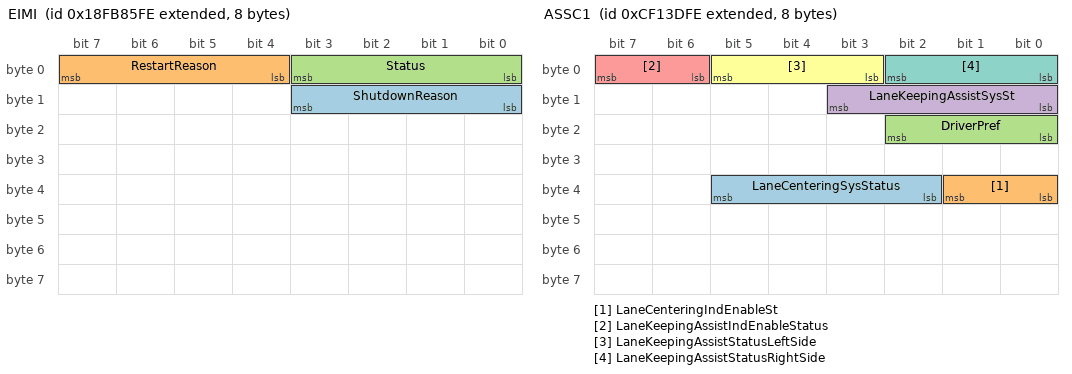
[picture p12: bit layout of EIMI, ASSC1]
BO_ 2566620670 EIMI: 8 Vector__XXX
 SG_ ShutdownReason : 8|4@1+ (1,0) [0|15] "" Vector__XXX
 SG_ RestartReason : 4|4@1+ (1,0) [0|15] "" Vector__XXX
 SG_ Status : 0|4@1+ (1,0) [0|15] "" Vector__XXX

BO_ 2364620286 ASSC1: 8 Vector__XXX
 SG_ LaneCenteringSysStatus : 34|4@1+ (1,0) [0|15] "" Vector__XXX
 SG_ LaneCenteringIndEnableSt : 32|2@1+ (1,0) [0|3] "" Vector__XXX
 SG_ DriverPref : 16|3@1+ (1,0) [0|7] "" Vector__XXX
 SG_ LaneKeepingAssistSysSt : 8|4@1+ (1,0) [0|15] "" Vector__XXX
 SG_ LaneKeepingAssistIndEnableStatus : 6|2@1+ (1,0) [0|3] "" Vector__XXX
 SG_ LaneKeepingAssistStatusLeftSide : 3|3@1+ (1,0) [0|7] "" Vector__XXX
 SG_ LaneKeepingAssistStatusRightSide : 0|3@1+ (1,0) [0|7] "" Vector__XXX

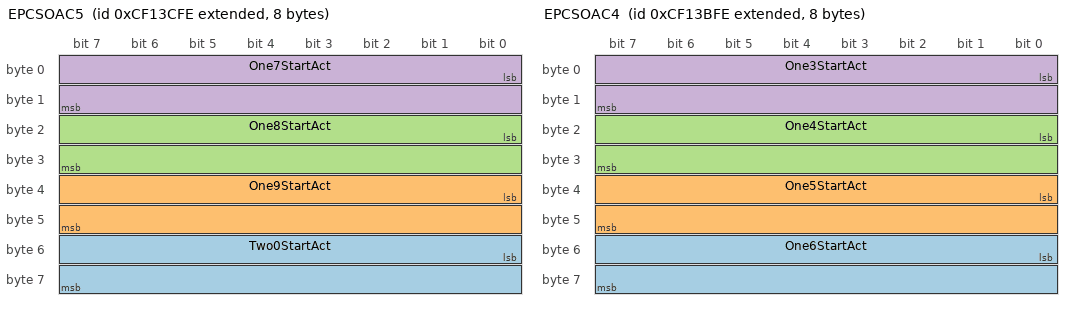
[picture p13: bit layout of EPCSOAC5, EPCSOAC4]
BO_ 2364620030 EPCSOAC5: 8 Vector__XXX
 SG_ Two0StartAct : 48|16@1+ (0.0078125,-400) [-400|101.99] "deg" Vector__XXX
 SG_ One9StartAct : 32|16@1+ (0.0078125,-400) [-400|101.99] "deg" Vector__XXX
 SG_ One8StartAct : 16|16@1+ (0.0078125,-400) [-400|101.99] "deg" Vector__XXX
 SG_ One7StartAct : 0|16@1+ (0.0078125,-400) [-400|101.99] "deg" Vector__XXX

BO_ 2364619774 EPCSOAC4: 8 Vector__XXX
 SG_ One6StartAct : 48|16@1+ (0.0078125,-400) [-400|101.99] "deg" Vector__XXX
 SG_ One5StartAct : 32|16@1+ (0.0078125,-400) [-400|101.99] "deg" Vector__XXX
 SG_ One4StartAct : 16|16@1+ (0.0078125,-400) [-400|101.99] "deg" Vector__XXX
 SG_ One3StartAct : 0|16@1+ (0.0078125,-400) [-400|101.99] "deg" Vector__XXX

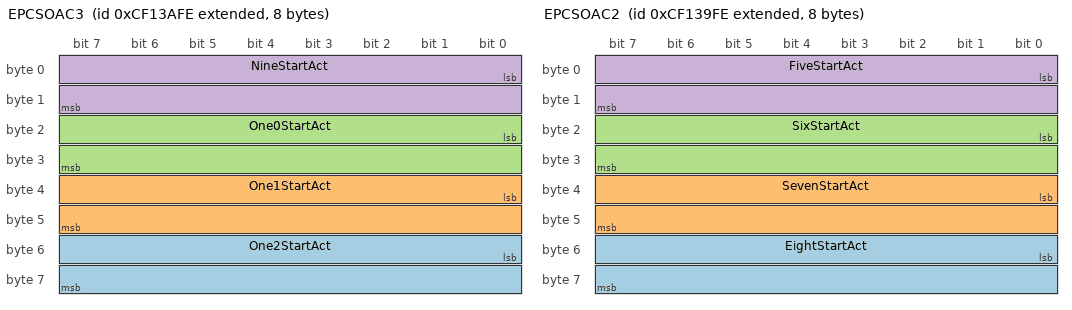
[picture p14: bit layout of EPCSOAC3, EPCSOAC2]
BO_ 2364619518 EPCSOAC3: 8 Vector__XXX
 SG_ One2StartAct : 48|16@1+ (0.0078125,-400) [-400|101.99] "deg" Vector__XXX
 SG_ One1StartAct : 32|16@1+ (0.0078125,-400) [-400|101.99] "deg" Vector__XXX
 SG_ One0StartAct : 16|16@1+ (0.0078125,-400) [-400|101.99] "deg" Vector__XXX
 SG_ NineStartAct : 0|16@1+ (0.0078125,-400) [-400|101.99] "deg" Vector__XXX

BO_ 2364619262 EPCSOAC2: 8 Vector__XXX
 SG_ EightStartAct : 48|16@1+ (0.0078125,-400) [-400|101.99] "deg" Vector__XXX
 SG_ SevenStartAct : 32|16@1+ (0.0078125,-400) [-400|101.99] "deg" Vector__XXX
 SG_ SixStartAct : 16|16@1+ (0.0078125,-400) [-400|101.99] "deg" Vector__XXX
 SG_ FiveStartAct : 0|16@1+ (0.0078125,-400) [-400|101.99] "deg" Vector__XXX

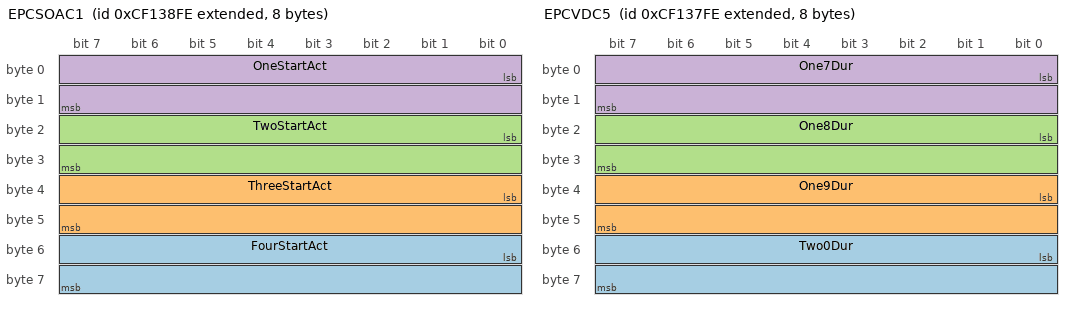
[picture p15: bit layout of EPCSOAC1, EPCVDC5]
BO_ 2364619006 EPCSOAC1: 8 Vector__XXX
 SG_ FourStartAct : 48|16@1+ (0.0078125,-400) [-400|101.99] "deg" Vector__XXX
 SG_ ThreeStartAct : 32|16@1+ (0.0078125,-400) [-400|101.99] "deg" Vector__XXX
 SG_ TwoStartAct : 16|16@1+ (0.0078125,-400) [-400|101.99] "deg" Vector__XXX
 SG_ OneStartAct : 0|16@1+ (0.0078125,-400) [-400|101.99] "deg" Vector__XXX

BO_ 2364618750 EPCVDC5: 8 Vector__XXX
 SG_ Two0Dur : 48|16@1+ (2,0) [0|128510] "탎" Vector__XXX
 SG_ One9Dur : 32|16@1+ (2,0) [0|128510] "탎" Vector__XXX
 SG_ One8Dur : 16|16@1+ (2,0) [0|128510] "탎" Vector__XXX
 SG_ One7Dur : 0|16@1+ (2,0) [0|128510] "탎" Vector__XXX

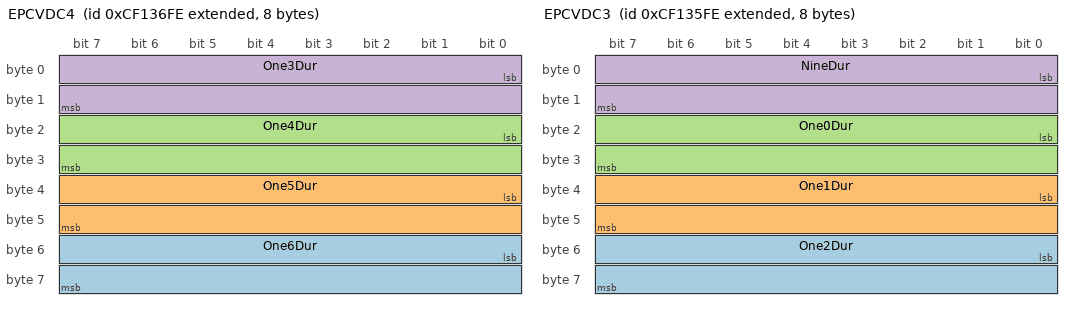
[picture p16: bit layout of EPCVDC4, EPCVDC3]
BO_ 2364618494 EPCVDC4: 8 Vector__XXX
 SG_ One6Dur : 48|16@1+ (2,0) [0|128510] "탎" Vector__XXX
 SG_ One5Dur : 32|16@1+ (2,0) [0|128510] "탎" Vector__XXX
 SG_ One4Dur : 16|16@1+ (2,0) [0|128510] "탎" Vector__XXX
 SG_ One3Dur : 0|16@1+ (2,0) [0|128510] "탎" Vector__XXX

BO_ 2364618238 EPCVDC3: 8 Vector__XXX
 SG_ One2Dur : 48|16@1+ (2,0) [0|128510] "탎" Vector__XXX
 SG_ One1Dur : 32|16@1+ (2,0) [0|128510] "탎" Vector__XXX
 SG_ One0Dur : 16|16@1+ (2,0) [0|128510] "탎" Vector__XXX
 SG_ NineDur : 0|16@1+ (2,0) [0|128510] "탎" Vector__XXX

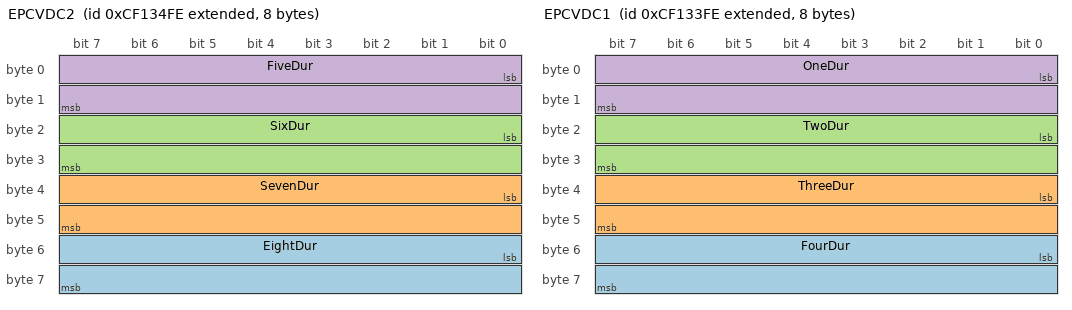
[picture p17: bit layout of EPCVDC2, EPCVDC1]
BO_ 2364617982 EPCVDC2: 8 Vector__XXX
 SG_ EightDur : 48|16@1+ (2,0) [0|128510] "탎" Vector__XXX
 SG_ SevenDur : 32|16@1+ (2,0) [0|128510] "탎" Vector__XXX
 SG_ SixDur : 16|16@1+ (2,0) [0|128510] "탎" Vector__XXX
 SG_ FiveDur : 0|16@1+ (2,0) [0|128510] "탎" Vector__XXX

BO_ 2364617726 EPCVDC1: 8 Vector__XXX
 SG_ FourDur : 48|16@1+ (2,0) [0|128510] "탎" Vector__XXX
 SG_ ThreeDur : 32|16@1+ (2,0) [0|128510] "탎" Vector__XXX
 SG_ TwoDur : 16|16@1+ (2,0) [0|128510] "탎" Vector__XXX
 SG_ OneDur : 0|16@1+ (2,0) [0|128510] "탎" Vector__XXX

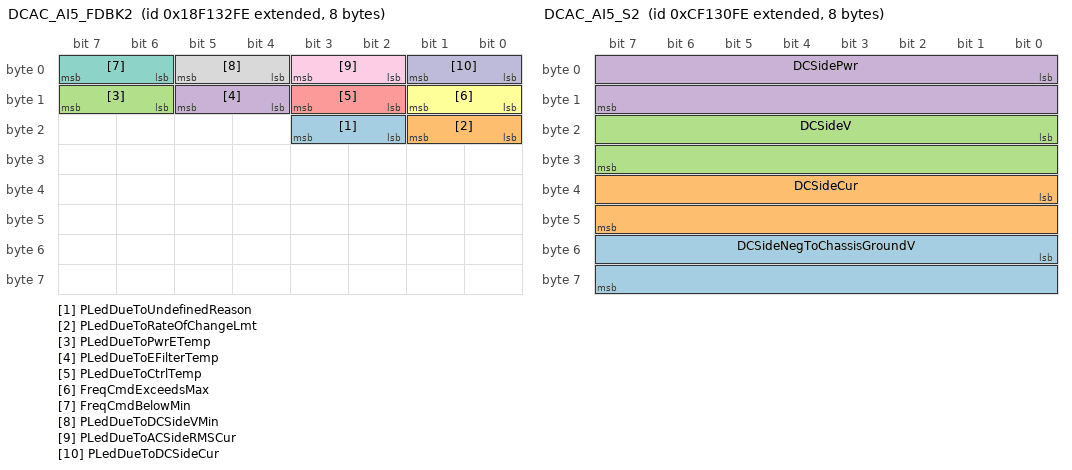
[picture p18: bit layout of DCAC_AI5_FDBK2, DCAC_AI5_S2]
BO_ 2565944062 DCAC_AI5_FDBK2: 8 Vector__XXX
 SG_ PLedDueToUndefinedReason : 18|2@1+ (1,0) [0|3] "" Vector__XXX
 SG_ PLedDueToRateOfChangeLmt : 16|2@1+ (1,0) [0|3] "" Vector__XXX
 SG_ PLedDueToPwrETemp : 14|2@1+ (1,0) [0|3] "" Vector__XXX
 SG_ PLedDueToEFilterTemp : 12|2@1+ (1,0) [0|3] "" Vector__XXX
 SG_ PLedDueToCtrlTemp : 10|2@1+ (1,0) [0|3] "" Vector__XXX
 SG_ FreqCmdExceedsMax : 8|2@1+ (1,0) [0|3] "" Vector__XXX
 SG_ FreqCmdBelowMin : 6|2@1+ (1,0) [0|3] "" Vector__XXX
 SG_ PLedDueToDCSideVMin : 4|2@1+ (1,0) [0|3] "" Vector__XXX
 SG_ PLedDueToACSideRMSCur : 2|2@1+ (1,0) [0|3] "" Vector__XXX
 SG_ PLedDueToDCSideCur : 0|2@1+ (1,0) [0|3] "" Vector__XXX

BO_ 2364617214 DCAC_AI5_V: 8 Vector__XXX
 SG_ SLIV : 16|16@1+ (0.05,0) [0|3212.75] "V" Vector__XXX
 SG_ IgntV : 0|16@1+ (0.05,0) [0|3212.75] "V" Vector__XXX

BO_ 2364616958 DCAC_AI5_S2: 8 Vector__XXX
 SG_ DCSideNegToChassisGroundV : 48|16@1+ (0.05,0) [0|3212.75] "V" Vector__XXX
 SG_ DCSideCur : 32|16@1+ (0.0625,0) [0|4015.9375] "A" Vector__XXX
 SG_ DCSideV : 16|16@1+ (0.05,0) [0|3212.75] "V" Vector__XXX
 SG_ DCSidePwr : 0|16@1+ (0.0625,0) [0|4015.9375] "kW" Vector__XXX

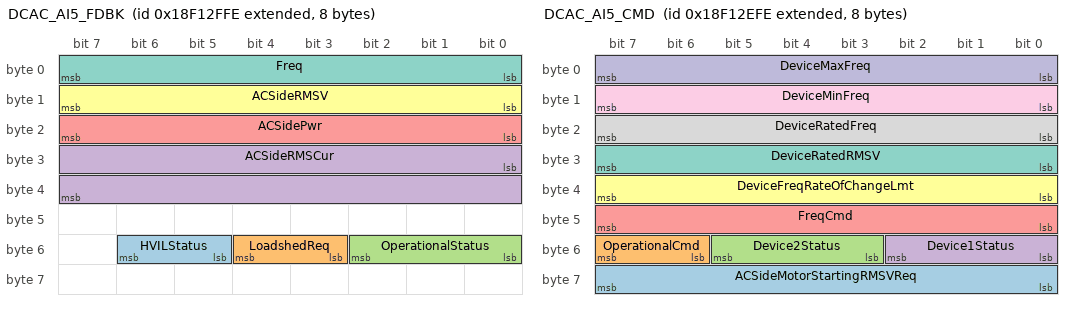
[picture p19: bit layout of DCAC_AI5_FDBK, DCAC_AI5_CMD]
BO_ 2565943294 DCAC_AI5_FDBK: 8 Vector__XXX
 SG_ HVILStatus : 53|2@1+ (1,0) [0|3] "" Vector__XXX
 SG_ LoadshedReq : 51|2@1+ (1,0) [0|3] "" Vector__XXX
 SG_ OperationalStatus : 48|3@1+ (1,0) [0|7] "" Vector__XXX
 SG_ ACSideRMSCur : 24|16@1+ (0.03125,0) [0|2007.96875] "Arms" Vector__XXX
 SG_ ACSidePwr : 16|8@1+ (0.1,0) [0|25] "kW" Vector__XXX
 SG_ ACSideRMSV : 8|8@1+ (2,0) [0|500] "Vrms" Vector__XXX
 SG_ Freq : 0|8@1+ (1,0) [0|250] "Hz" Vector__XXX

BO_ 2565943038 DCAC_AI5_CMD: 8 Vector__XXX
 SG_ ACSideMotorStartingRMSVReq : 56|8@1+ (2,0) [0|500] "Vrms" Vector__XXX
 SG_ OperationalCmd : 54|2@1+ (1,0) [0|3] "" Vector__XXX
 SG_ Device2Status : 51|3@1+ (1,0) [0|7] "" Vector__XXX
 SG_ Device1Status : 48|3@1+ (1,0) [0|7] "" Vector__XXX
 SG_ FreqCmd : 40|8@1+ (1,0) [0|250] "Hz" Vector__XXX
 SG_ DeviceFreqRateOfChangeLmt : 32|8@1+ (2,0) [0|500] "Hz/s" Vector__XXX
 SG_ DeviceRatedRMSV : 24|8@1+ (2,0) [0|500] "Vrms" Vector__XXX
 SG_ DeviceRatedFreq : 16|8@1+ (1,0) [0|250] "Hz" Vector__XXX
 SG_ DeviceMinFreq : 8|8@1+ (1,0) [0|250] "Hz" Vector__XXX
 SG_ DeviceMaxFreq : 0|8@1+ (1,0) [0|250] "Hz" Vector__XXX

CM_ BU_ PowertrainControlModule "Electronic control module in charge of controlling and coordinating the operation of a hybrid propulsion system.";
CM_ BU_ HitchControl "Straight truck hitch (NOT Agricultural hitch � it is in IG 2) ";
CM_ BO_ 3221225472 "This is a message for not used signals, created by Vector CANdb++ DBC OLE DB Provider.";
CM_ SG_ 3221225472 NumberOfMembersInWorkingSet "The number of members in a particular Working Set.";
CM_ SG_ 3221225472 SourceAddress "Instance of a Source Address listed a Network Message data field.";
CM_ SG_ 3221225472 NncntnuslyMonitoredSystemsStatus "Identifies the non-continuously monitored systems status. Each bit identifies whether a particular test is complete for a given controller.
";
CM_ SG_ 3221225472 NncntnslyMonitoredSystemsSupport "Identifies the non-continuously monitored systems support.
";
CM_ SG_ 3221225472 CntnslyMntrdSystmsSupport_Status "Identifies the continuously monitored system support and status.
";
CM_ SG_ 3221225472 AETCTorqueValue "Engine torque value of the data points in PGN 64912 � Advertised Engine Torque Curve (AETC).";
CM_ SG_ 3221225472 TrailerWeight "Total mass of freight-carrying vehicle designed to be pulled by truck, including the weight of the contents.";
CM_ SG_ 3221225472 ReferenceTirePressSetting "Reference value of the tire pressure setting as basis for the tire pressure monitoring ...";
CM_ SG_ 3221225472 ReferenceTirePress "Reference value of the tire pressure as basis for the tire pressure monitoring ...";
CM_ SG_ 3221225472 TirePressThresholdDetection "Signal indicating the pressure level of the tire.  The levels defined represent different pressure conditions of the tire: 000 Extreme over pressure - The tire pressure is at a level where the safety of the vehicle may be jeopardised.";
CM_ SG_ 3221225472 TireAirLeakageRate "The pressure loss rate of a tire.";
CM_ SG_ 3221225472 CTIWheelEndElectricalFault "Indicates the status of electrical fault on CTI wheel interface.";
CM_ SG_ 3221225472 CTITireStatus "Indicates the status of the tire.";
CM_ SG_ 3221225472 CTIWheelSensorStatus "Indicates whether the wheel is being monitored by the CTI controller.";
CM_ SG_ 3221225472 TireTemp "Temperature at the surface of the tire sidewall.";
CM_ SG_ 3221225472 TirePress "Pressure at which air is contained in cavity formed by tire and rim.";
CM_ SG_ 3221225472 EngTurningGearEngaged "Status signal which indicates that the turning gear is engaged.  The turning gear is used to turn the flywheel/crankshaft, ...";
CM_ SG_ 3221225472 AETCSpeedValue "Engine speed value of the data points in PGN 64912 � Advertised Engine Torque Curve (AETC).";
CM_ BO_ 2365313534 "DC/DC Converter 1 SLI Battery Limits
Sets the SLI Battery limits for the transfer of energy between the high voltage system (i.e. high side) and the SLI battery or low voltage system (i.e. low side) using a DC/DC Converter.
One intended use of ...";
CM_ SG_ 2365313534 SLIBatTempMaxLmtReq "The maximum allowed SLI Battery Temperature requested by a separate device.";
CM_ SG_ 2365313534 SLIBatTermChargeCurMaxLmtReq "The maximum allowed SLI Battery charging current (at the battery terminals) requested by a separate device.";
CM_ SG_ 2365313534 SLIBatTermVMaxLmtReq "The maximum allowed SLI Battery Voltage (at the battery terminals) requested by a separate system device.";
CM_ BO_ 2566639870 "DC/DC Converter 1 Configuration 1
Reports the active configuration setting for a DC/DC Converter.  Settings may be defined by the manufacturer, or set through use of limit PGNs (DCDC1HL, DCDC1LL, and DCDC1SBL).
One intended use of this message is ...";
CM_ SG_ 2566639870 OneLowSideVBuckDefaultSetting "Reports the converter active Low Side Voltage Buck Default Setting.  The default may be requested by a separate device (via SPN 9515).

Note: Report Not Available (FFFFh) when no default has been set.";
CM_ SG_ 2566639870 SLIBatTempMaxLmtSetting "Reports the active SLI Battery Temperature maximum limit.  The setting may be requested by a separate device (via SPN 8819) or determined by the DC/DC Controller based on operating conditions.";
CM_ SG_ 2566639870 SLIBatTermChargeCurMaxLmtSetting "Reports the active SLI Battery charging current maximum limit (at the battery terminals).  The setting may be requested by a separate device (via SPN 8818) or determined by the DC/DC Controller based on operating conditions.";
CM_ SG_ 2566639870 SLIBatTermVMaxLmtSetting "Reports the active SLI Battery Voltage maximum limit (at the battery terminals).  The setting may be requested by a separate device (via SPN 8817) or determined by the DC/DC Controller based on operating conditions.";
CM_ SG_ 2566639870 OneLowSideCurMaxLmtSetting "Reports the active maximum limit on the low side current of the DC/DC Converter.  The setting may be requested by a separate device (via SPN 8568) or determined by the DC/DC Controller based on operating conditions.";
CM_ SG_ 2566639870 OneLowSideVMaxLmtSetting "Reports the active maximum limit on the low side voltage of the DC/DC Converter.  The setting may be requested by a separate device (via SPN 8567) or determined by the DC/DC Controller based on operating conditions.";
CM_ SG_ 2566639870 OneLowSideVMinLmtSetting "Reports the active minimum limit on the low side voltage of the DC/DC Converter.  The setting may be requested by a separate device (via SPN 8566) or determined by the DC/DC Controller based on operating conditions.";
CM_ SG_ 2566639870 OneHiSideCurMaxLmtSetting "Reports the active maximum limit on the high side current of the DC/DC Converter.  The setting may be requested by a separate device (via SPN 8565) or determined by the DC/DC Controller based on operating conditions.";
CM_ SG_ 2566639870 OneHiSideVMaxLmtSetting "Reports the active maximum limit on the high side voltage of the DC/DC Converter.  The setting may be requested by a separate device (via SPN 8564) or determined by the DC/DC Controller based on operating conditions.";
CM_ SG_ 2566639870 OneHiSideVMinLmtSetting "Reports the active minimum limit on the high side voltage of the DC/DC Converter.  The setting may be requested by a separate device (via SPN 8563) or determined by the DC/DC Controller based on operating conditions.";
CM_ BO_ 2566639614 "DC/DC Converter 1 Lifetime Data
Contains data accumulated over the lifetime of a DC/DC Converter.";
CM_ SG_ 2566639614 OneTotalLowSideCharge "Indicates the total lifetime charge converted by the DC/DC  from the low side (e.g. SLI battery) during boost mode.";
CM_ SG_ 2566639614 OneTotalHiSideCharge "Indicates the total lifetime charge converted by the DC/DC from the high side (e.g. HVES) during buck mode.";
CM_ SG_ 2566639614 OneTotalLowSideEnergy "Indicates the total lifetime energy converted by the DC/DC  from the low side (e.g. SLI battery) during boost mode.";
CM_ SG_ 2566639614 OneTotalHiSideEnergy "Indicates the total lifetime energy converted by the DC/DC from the high side (e.g. HVES) during buck mode.";
CM_ BO_ 2633748222 "Configurable Receive SPNs Status
PGN 28160 and PGN 64462 are used to manage and report configurable parameters that are received by a Configurable ECU. PGN 64462 is the response to PGN 28160. PGN 64462 includes the SPNs and the receive status of ...";
CM_ SG_ 2633748222 SPNModifiedStatus "Indicates if the Configurable ECU is able to honor the request issued in PGN 28160 for the associated SPN identified on SPN 8845 on the port identified in SPN 8842.
00 - SPN뭩 receive status could not be modified. Note: This state shall only be ...";
CM_ SG_ 2633748222 SPNSA "The source address of a device from which the Configurable ECU is to receive the SPN identified in SPN 8845.
0 to 253 - Source Address in which this ECU is configured to receive the Configurable Receive SPN. Note: If the Configurable Receive SPN ...";
CM_ SG_ 2633748222 SPNDetailedStatus "Bit 5: Source Address Pending Status
1 - The use of the source address in SPN 8846 is pending and will take effect after the next significant trigger (e.g., power cycle).
0 - The source address in SPN 8846 is a source address in which the ...";
CM_ SG_ 2633748222 SPN "Identifies the SPN for which the associated SPNs 8846, 8847, & 8848 apply.";
CM_ SG_ 2633748222 PortCmdStatus "Indicates the overall success in performing the commanded transaction in PGN 28160.
000 - Positive Acknowledgment - PGN 28160 command was processed without issue.
001 - Negative Acknowledgment - PGN 28160 command was received but one or more ...";
CM_ SG_ 2633748222 PortPendingChangesStatus "Indicates if there are any pending receive changes for the port identified in SPN 8842.
0 - No pending changes to the receive status for any supported SPNs for the port identified in SPN 8842.
1 - Receive changes are pending for one or more ...";
CM_ SG_ 2633748222 Port "Identifies the ECU communications port of the responding Configurable ECU that is in context for this instance of PGN 64462. If changes are accepted by the Configurable ECU, then this is the port affected. The identification of each ECU ...";
CM_ BO_ 2566639102 "Well Stimulation Pump System Configuration Status
Communicates the threshold setting of operating parameters of a well stimulation pump used in oil and gas drilling applications.
See PGN 27904 for the command PGN to set the values of the operating ...";
CM_ SG_ 2566639102 PlungerFiringOrderSetting "Well stimulation pump plunger firing order
0000 - Firing order 1-2-3
0001 - Firing order 1-5-2-3-4
0010 - Reserved
0011 - Reserved
0100 - Reserved
0101 - Reserved
0110 - Reserved
0111 - Reserved
1000 - Reserved
1001 - Reserved
1010 - ...";
CM_ SG_ 2566639102 RodLoadHiThreshold "Rod load force at which the rod load is considered at the highest acceptable force.";
CM_ SG_ 2566639102 CrankshaftSpdHiThreshold "Configurable well stimulation pump crankshaft speed that has been considered to be the highest acceptable speed.";
CM_ SG_ 2566639102 CrankshaftSpdLowThreshold "Configurable well stimulation pump crankshaft speed that has been considered to be the lowest acceptable speed.";
CM_ SG_ 2566639102 DisPressHiThreshold "Configurable pressure at which the discharge pressure is considered at the highest acceptable pressure.";
CM_ SG_ 2566639102 SuctionPressHiThreshold "Configurable pressure at which the suction pressure is considered at the highest acceptable pressure.";
CM_ SG_ 2566639102 SuctionPressLowThreshold "Configurable pressure at which the suction pressure is considered at the lowest acceptable pressure.";
CM_ SG_ 2566639102 GearBoxOilTempHiThreshold "Configurable temperature at which the gearbox oil temperature is considered at the highest acceptable temperature.";
CM_ SG_ 2566639102 GearBoxOilTempLowThreshold "Configurable temperature at which the gearbox oil temperature is considered at the lowest acceptable temperature.";
CM_ SG_ 2566639102 GearBoxOilPressHiThreshold "Configurable pressure at which the gearbox oil pressure is considered at the highest acceptable pressure.";
CM_ SG_ 2566639102 GearBoxOilPressLowThreshold "Configurable pressure at which the gearbox oil pressure is considered at the lowest acceptable pressure.";
CM_ BO_ 2566638846 "Well Stimulation Pump Hours
Commuicates operating parameters of a well stimulation pump used in oil and gas drilling applications.";
CM_ SG_ 2566638846 VlvSeatOpHours "The hours accumulated since the last time a valve seat replacement was performed on the well stimulation pump.";
CM_ SG_ 2566638846 PackingOpHours "The hours accumulated since the last time a packing replacement was performed on the well stimulation pump.";
CM_ SG_ 2566638846 VlvOpHours "The hours accumulated since the last time a valve replacement was performed on the well stimulation pump.";
CM_ SG_ 2566638846 MaintenanceIntervalHours "The hours accumulated since the last maintenance interval on the well stimulation pump.";
CM_ BO_ 2566638590 "Engine Exhaust Particulate Control System Info
Contains information which relates to the exhaust particulate control system on the engine.";
CM_ SG_ 2566638590 DiagCount "The total occurrences of diagnostic codes for the exhaust particulate control system that have been active above a predetermined time threshold. A code that has been active less than the predetermined time threshold (for example, 20 hours) will not ...";
CM_ SG_ 2566638590 DiagTime "The total time the exhaust particulate control diagnostic codes have been active. Total time only includes the active time for codes which have been active above a predetermined time threshold. The time for a code that has been active less than the ...";
CM_ BO_ 2365311486 "DC/DC Converter 2 High Side Limits
Sets the HVES or High Voltage system limits for the transfer of energy between the high voltage system (i.e. high side) and the SLI battery or low voltage system (i.e. low side) using a DC/DC converter.
One ...";
CM_ SG_ 2365311486 TwoHiSideCurMaxLmtReq "The maximum allowed high side current requested by a separate device. Under normal conditions this requested limit would be reflected in SPN 8926.";
CM_ SG_ 2365311486 TwoHiSideVMaxLmtReq "The maximum allowed high side voltage requested by a separate device.  Under normal conditions this requested limit would be reflected in SPN 8925.";
CM_ SG_ 2365311486 TwoHiSideVMinLmtReq "The minimum allowed high side voltage requested by a separate device. Under normal conditions this requested limit would be reflected in SPN 8924.";
CM_ BO_ 2365311230 "DC/DC Converter 2 Low Side Limits
Sets the SLI or Low Voltage system limits for the transfer of energy between the HVES or high voltage system (i.e. high side) and the SLI battery or low voltage system (i.e. low side) in a DC/DC Converter.";
CM_ SG_ 2365311230 TwoLowSideCurMaxLmtReq "The maximum allowed low side current requested by a separate device.  Under normal conditions this requested limit would be reflected in SPN 8929.";
CM_ SG_ 2365311230 TwoLowSideVMaxLmtReq "The maximum allowed low side voltage requested by a separate device.  Under normal conditions this requested limit would be reflected in SPN 8928.";
CM_ SG_ 2365311230 TwoLowSideVMinLmtReq "The minimum allowed low side voltage requested by a separate device.  Under normal conditions this requested limit would be reflected in SPN 8927.";
CM_ BO_ 2365310974 "DC/DC Converter 2 Temperatures
DC/DC Converter measured temperature data.

One intended use of this message is for a conventional engine mounted alternator replacement.";
CM_ SG_ 2365310974 TwoCoolantOutTemp "Parameter indicating the temperature of the DC/DC Converter Coolant measured at the output of the converter";
CM_ SG_ 2365310974 TwoCoolantInTemp "Parameter indicating the temperature of the DC/DC Converter Coolant measured at the input of the converter";
CM_ SG_ 2365310974 TwoPwrETemp "Parameter indicating the temperature of the DC/DC Converter power electronics components (e.g, switch or heatsink).";
CM_ SG_ 2365310974 TwoConvEFilterTemp "Parameter indicating the temperature of the electronic components that make up the DC/DC Converter filter.";
CM_ SG_ 2365310974 TwoConvTemp "Parameter indicating the temperature of the DC/DC Converter (e.g, controller, circuit board, enclosure).";
CM_ BO_ 2365310718 "DC/DC Converter 2 SLI Battery Limits
Sets the SLI Battery limits for the transfer of energy between the high voltage system (i.e. high side) and the SLI battery or low voltage system (i.e. low side) using a DC/DC Converter.
One intended use of ...";
CM_ SG_ 2365310718 SLIBatTempMaxLmtReq "The maximum allowed SLI Battery Temperature requested by a separate device.";
CM_ SG_ 2365310718 SLIBatTermChargeCurMaxLmtReq "The maximum allowed SLI Battery charging current (at the battery terminals) requested by a separate device.";
CM_ SG_ 2365310718 SLIBatTermVMaxLmtReq "The maximum allowed SLI Battery Voltage (at the battery terminals) requested by a separate system device.";
CM_ BO_ 2566637054 "DC/DC Converter 2 Configuration 1
Reports the active configuration setting for a DC/DC Converter.  Settings may be defined by the manufacturer, or set through use of limit PGNs (DCDC2HL, DCDC2LL, and DCDC2SBL).
One intended use of this message is ...";
CM_ SG_ 2566637054 TwoLowSideVBuckDefaultSetting "Reports the converter active Low Side Voltage Buck Default Setting.  The default may be requested by a separate device (via SPN 9516).

Note: Report Not Available (FFFFh) when no default has been set.";
CM_ SG_ 2566637054 SLIBatTempMaxLmtSetting "Reports the active SLI Battery Temperature maximum limit.  The setting may be requested by a separate device (see SPN 8935) or determined by the DC/DC Controller based on operating conditions.";
CM_ SG_ 2566637054 SLIBatTermChargeCurMaxLmtSetting "Reports the active SLI Battery charging current maximum limit (at the battery terminals).  The setting may be requested by a separate device (see SPN 8934) or determined by the DC/DC Controller based on operating conditions.";
CM_ SG_ 2566637054 SLIBatTermVMaxLmtSetting "Reports the active SLI Battery Voltage maximum limit (at the battery terminals).  The setting may be requested by a separate device (see SPN 8933) or determined by the DC/DC Controller based on operating conditions.";
CM_ SG_ 2566637054 TwoLowSideCurMaxLmtSetting "Reports the active maximum limit on the low side current of the DC/DC Converter.  The setting may be requested by a separate device (see SPN 8943) or determined by the DC/DC Controller based on operating conditions.";
CM_ SG_ 2566637054 TwoLowSideVMaxLmtSetting "Reports the active maximum limit on the low side voltage of the DC/DC Converter.  The setting may be requested by a separate device (see SPN 8942) or determined by the DC/DC Controller based on operating conditions.";
CM_ SG_ 2566637054 TwoLowSideVMinLmtSetting "Reports the active minimum limit on the low side voltage of the DC/DC Converter.  The setting may be requested by a separate device(see SPN 8941) or determined by the DC/DC Controller based on operating conditions.";
CM_ SG_ 2566637054 TwoHiSideCurMaxLmtSetting "Reports the active maximum limit on the high side current of the DC/DC Converter.  The setting may be requested by a separate device (see SPN 8946) or determined by the DC/DC Controller based on operating conditions.";
CM_ SG_ 2566637054 TwoHiSideVMaxLmtSetting "Reports the active maximum limit on the high side voltage of the DC/DC Converter.  The setting may be requested by a separate device (see SPN 8945) or determined by the DC/DC Controller based on operating conditions.";
CM_ SG_ 2566637054 TwoHiSideVMinLmtSetting "Reports the active minimum limit on the high side voltage of the DC/DC Converter.  The setting may be requested by a separate device (see SPN 8944) or determined by the DC/DC Controller based on operating conditions.";
CM_ BO_ 2566636798 "DC/DC Converter 2 Lifetime Data
Contains data accumulated over the lifetime of a DC/DC Converter.";
CM_ SG_ 2566636798 TwoTotalLowSideCharge "Indicates the total lifetime charge converted by the DC/DC  from the low side (e.g. SLI battery) during boost mode.";
CM_ SG_ 2566636798 TwoTotalHiSideCharge "Indicates the total lifetime charge converted by the DC/DC from the high side (e.g. HVES) during buck mode.";
CM_ SG_ 2566636798 TwoTotalLowSideEnergy "Indicates the total lifetime energy converted by the DC/DC  from the low side (e.g. SLI battery) during boost mode.";
CM_ SG_ 2566636798 TwoTotalHiSideEnergy "Indicates the total lifetime energy converted by the DC/DC from the high side (e.g. HVES) during buck mode.";
CM_ BO_ 2365309950 "DC/DC Converter 3 High Side Limits
Sets the HVES or High Voltage system limits for the transfer of energy between the high voltage system (i.e. high side) and the SLI battery or low voltage system (i.e. low side) using a DC/DC converter.
One ...";
CM_ SG_ 2365309950 ThreeHiSideCurMaxLmtReq "The maximum allowed high side current requested by a separate device.   Under normal conditions this requested limit would be reflected in  SPN 8981.";
CM_ SG_ 2365309950 ThreeHiSideVMaxLmtReq "The maximum allowed high side voltage requested by a separate device.   Under normal conditions this requested limit would be reflected in  SPN 8980.";
CM_ SG_ 2365309950 ThreeHiSideVMinLmtReq "The minimum allowed high side voltage requested by a separate device.   Under normal conditions this requested limit would be reflected in  SPN 8979.";
CM_ BO_ 2365309694 "DC/DC Converter 3 Low Side Limits
Sets the SLI or Low Voltage system limits for the transfer of energy between the HVES or high voltage system (i.e. high side) and the SLI battery or low voltage system (i.e. low side) in a DC/DC Converter.";
CM_ SG_ 2365309694 ThreeLowSideCurMaxLmtReq "The maximum allowed low side current requested by a separate device.   Under normal conditions this requested limit would be reflected in SPN 8984.";
CM_ SG_ 2365309694 ThreeLowSideVMaxLmtReq "The maximum allowed low side voltage requested by a separate device.   Under normal conditions this requested limit would be reflected in SPN 8983.";
CM_ SG_ 2365309694 ThreeLowSideVMinLmtReq "The minimum allowed low side voltage requested by a separate device.   Under normal conditions this requested limit would be reflected in SPN 8982.";
CM_ BO_ 2365309438 "DC/DC Converter 3 Temperatures
DC/DC Converter measured temperature data.

One intended use of this message is for a conventional engine mounted alternator replacement.";
CM_ SG_ 2365309438 ThreeCoolantOutTemp "Parameter indicating the temperature of the DC/DC Converter Coolant measured at the output of the converter";
CM_ SG_ 2365309438 ThreeCoolantInTemp "Parameter indicating the temperature of the DC/DC Converter Coolant measured at the input of the converter";
CM_ SG_ 2365309438 ThreePwrETemp "Parameter indicating the temperature of the DC/DC Converter power electronics components (e.g, switch or heatsink).";
CM_ SG_ 2365309438 ThreeConvEFilterTemp "Parameter indicating the temperature of the electronic components that make up the DC/DC Converter filter.";
CM_ SG_ 2365309438 ThreeConvTemp "Parameter indicating the temperature of the DC/DC Converter (e.g, controller, circuit board, enclosure).";
CM_ BO_ 2365309182 "DC/DC Converter 3 SLI Battery Limits
Sets the SLI Battery limits for the transfer of energy between the high voltage system (i.e. high side) and the SLI battery or low voltage system (i.e. low side) using a DC/DC Converter.
One intended use of ...";
CM_ SG_ 2365309182 SLIBatTempMaxLmtReq "The maximum allowed SLI Battery Temperature requested by a separate device.";
CM_ SG_ 2365309182 SLIBatTermChargeCurMaxLmtReq "The maximum allowed SLI Battery charging current (at the battery terminals) requested by a separate device.";
CM_ SG_ 2365309182 SLIBatTermVMaxLmtReq "The maximum allowed SLI Battery Voltage (at the battery terminals) requested by a separate system device.";
CM_ BO_ 2566635518 "DC/DC Converter 3 Configuration 1
Reports the active configuration setting for a DC/DC Converter.  Settings may be defined by the manufacturer, or set through use of limit PGNs (DCDC3HL, DCDC3LL, and DCDC3SBL).
One intended use of this message is ...";
CM_ SG_ 2566635518 ThreeLowSideVBuckDefaultSetting "Reports the converter active Low Side Voltage Buck Default Setting.  The default may be requested by a separate device (via SPN 9517).

Note: Report Not Available (FFFFh) when no default has been set.";
CM_ SG_ 2566635518 SLIBatTempMaxLmtSetting "Reports the active SLI Battery Temperature maximum limit.  The setting may be requested by a separate device (see SPN 8990) or determined by the DC/DC Controller based on operating conditions.";
CM_ SG_ 2566635518 SLIBatTermChargeCurMaxLmtSetting "Reports the active SLI Battery charging current maximum limit (at the battery terminals).  The setting may be requested by a separate device (see SPN 8989) or determined by the DC/DC Controller based on operating conditions.";
CM_ SG_ 2566635518 SLIBatTermVMaxLmtSetting "Reports the active SLI Battery Voltage maximum limit (at the battery terminals).  The setting may be requested by a separate device (see SPN 8988) or determined by the DC/DC Controller based on operating conditions.";
CM_ SG_ 2566635518 ThreeLowSideCurMaxLmtSetting "Reports the active maximum limit on the low side current of the DC/DC Converter.  The setting may be requested by a separate device (see SPN 8998) or determined by the DC/DC Controller based on operating conditions.";
CM_ SG_ 2566635518 ThreeLowSideVMaxLmtSetting "Reports the active maximum limit on the low side voltage of the DC/DC Converter.  The setting may be requested by a separate device (see SPN 8997) or determined by the DC/DC Controller based on operating conditions.";
CM_ SG_ 2566635518 ThreeLowSideVMinLmtSetting "Reports the active minimum limit on the low side voltage of the DC/DC Converter.  The setting may be requested by a separate device(see SPN 8996) or determined by the DC/DC Controller based on operating conditions.";
CM_ SG_ 2566635518 ThreeHiSideCurMaxLmtSetting "Reports the active maximum limit on the high side current of the DC/DC Converter.  The setting may be requested by a separate device (see SPN 9001) or determined by the DC/DC Controller based on operating conditions.";
CM_ SG_ 2566635518 ThreeHiSideVMaxLmtSetting "Reports the active maximum limit on the high side voltage of the DC/DC Converter.  The setting may be requested by a separate device (see SPN 9000) or determined by the DC/DC Controller based on operating conditions.";
CM_ SG_ 2566635518 ThreeHiSideVMinLmtSetting "Reports the active minimum limit on the high side voltage of the DC/DC Converter.  The setting may be requested by a separate device (see SPN 8999) or determined by the DC/DC Controller based on operating conditions.";
CM_ BO_ 2566635262 "DC/DC Converter 3 Lifetime Data
Contains data accumulated over the lifetime of a DC/DC Converter.";
CM_ SG_ 2566635262 ThreeTotalLowSideCharge "Indicates the total lifetime charge converted by the DC/DC  from the low side (e.g. SLI battery) during boost mode.";
CM_ SG_ 2566635262 ThreeTotalHiSideCharge "Indicates the total lifetime charge converted by the DC/DC from the high side (e.g. HVES) during buck mode.";
CM_ SG_ 2566635262 ThreeTotalLowSideEnergy "Indicates the total lifetime energy converted by the DC/DC  from the low side (e.g. SLI battery) during boost mode.";
CM_ SG_ 2566635262 ThreeTotalHiSideEnergy "Indicates the total lifetime energy converted by the DC/DC from the high side (e.g. HVES) during buck mode.";
CM_ BO_ 2365308414 "DC/DC Converter 4 High Side Limits
Sets the HVES or High Voltage system limits for the transfer of energy between the high voltage system (i.e. high side) and the SLI battery or low voltage system (i.e. low side) using a DC/DC converter.
One ...";
CM_ SG_ 2365308414 FourHiSideCurMaxLmtReq "The maximum allowed high side current requested by a separate device.   Under normal conditions this requested limit would be reflected in SPN 9036.";
CM_ SG_ 2365308414 FourHiSideVMaxLmtReq "The maximum allowed high side voltage requested by a separate device.  Under normal conditions this requested limit would be reflected in SPN 9035.";
CM_ SG_ 2365308414 FourHiSideVMinLmtReq "The minimum allowed high side voltage requested by a separate device.   Under normal conditions this requested limit would be reflected in SPN 9034.";
CM_ BO_ 2365308158 "DC/DC Converter 4 Low Side Limits
Sets the SLI or Low Voltage system limits for the transfer of energy between the HVES or high voltage system (i.e. high side) and the SLI battery or low voltage system (i.e. low side) in a DC/DC Converter.";
CM_ SG_ 2365308158 FourLowSideCurMaxLmtReq "The maximum allowed low side current requested by a separate device.   Under normal conditions this requested limit would be reflected in SPN 9039.";
CM_ SG_ 2365308158 FourLowSideVMaxLmtReq "The maximum allowed low side voltage requested by a separate device.   Under normal conditions this requested limit would be reflected in SPN 9038.";
CM_ SG_ 2365308158 FourLowSideVMinLmtReq "The minimum allowed low side voltage requested by a separate device.  Under normal conditions this requested limit would be reflected in SPN 9037.";
CM_ BO_ 2365307902 "DC/DC Converter 4 Temperatures
DC/DC Converter measured temperature data.

One intended use of this message is for a conventional engine mounted alternator replacement.";
CM_ SG_ 2365307902 FourCoolantOutTemp "Parameter indicating the temperature of the DC/DC Converter Coolant measured at the output of the converter";
CM_ SG_ 2365307902 FourCoolantInTemp "Parameter indicating the temperature of the DC/DC Converter Coolant measured at the input of the converter";
CM_ SG_ 2365307902 FourPwrETemp "Parameter indicating the temperature of the DC/DC Converter power electronics components (e.g, switch or heatsink).";
CM_ SG_ 2365307902 FourConvEFilterTemp "Parameter indicating the temperature of the electronic components that make up the DC/DC Converter filter.";
CM_ SG_ 2365307902 FourConvTemp "Parameter indicating the temperature of the DC/DC Converter (e.g, controller, circuit board, enclosure).";
CM_ BO_ 2365307646 "DC/DC Converter 4 SLI Battery Limits
Sets the SLI Battery limits for the transfer of energy between the high voltage system (i.e. high side) and the SLI battery or low voltage system (i.e. low side) using a DC/DC Converter.
One intended use of ...";
CM_ SG_ 2365307646 SLIBatTempMaxLmtReq "The maximum allowed SLI Battery Temperature requested by a separate device.";
CM_ SG_ 2365307646 SLIBatTermChargeCurMaxLmtReq "The maximum allowed SLI Battery charging current (at the battery terminals) requested by a separate device.";
CM_ SG_ 2365307646 SLIBatTermVMaxLmtReq "The maximum allowed SLI Battery Voltage (at the battery terminals) requested by a separate system device.";
CM_ BO_ 2566633982 "DC/DC Converter 4 Configuration 1
Reports the active configuration setting for a DC/DC Converter.  Settings may be defined by the manufacturer, or set through use of limit PGNs (DCDC4HL, DCDC4LL, and DCDC4SBL).
One intended use of this message is ...";
CM_ SG_ 2566633982 FourLowSideVBuckDefaultSetting "Reports the converter active Low Side Voltage Buck Default Setting.  The default may be requested by a separate device (via SPN 9518).

Note: Report Not Available (FFFFh) when no default has been set.";
CM_ SG_ 2566633982 SLIBatTempMaxLmtSetting "Reports the active SLI Battery Temperature maximum limit.  The setting may be requested by a separate device (see SPN 9045) or determined by the DC/DC Controller based on operating conditions.";
CM_ SG_ 2566633982 SLIBatTermChargeCurMaxLmtSetting "Reports the active SLI Battery charging current maximum limit (at the battery terminals).  The setting may be requested by a separate device (see SPN 9044) or determined by the DC/DC Controller based on operating conditions.";
CM_ SG_ 2566633982 SLIBatTermVMaxLmtSetting "Reports the active SLI Battery Voltage maximum limit (at the battery terminals).  The setting may be requested by a separate device (see SPN 9043) or determined by the DC/DC Controller based on operating conditions.";
CM_ SG_ 2566633982 FourLowSideCurMaxLmtSetting "Reports the active maximum limit on the low side current of the DC/DC Converter.  The setting may be requested by a separate device (see SPN 9053) or determined by the DC/DC Controller based on operating conditions.";
CM_ SG_ 2566633982 FourLowSideVMaxLmtSetting "Reports the active maximum limit on the low side voltage of the DC/DC Converter.  The setting may be requested by a separate device (see SPN 9052) or determined by the DC/DC Controller based on operating conditions.";
CM_ SG_ 2566633982 FourLowSideVMinLmtSetting "Reports the active minimum limit on the low side voltage of the DC/DC Converter.  The setting may be requested by a separate device(see SPN 9051) or determined by the DC/DC Controller based on operating conditions.";
CM_ SG_ 2566633982 FourHiSideCurMaxLmtSetting "Reports the active maximum limit on the high side current of the DC/DC Converter.  The setting may be requested by a separate device (see SPN 9056) or determined by the DC/DC Controller based on operating conditions.";
CM_ SG_ 2566633982 FourHiSideVMaxLmtSetting "Reports the active maximum limit on the high side voltage of the DC/DC Converter.  The setting may be requested by a separate device (see SPN 9055) or determined by the DC/DC Controller based on operating conditions.";
CM_ SG_ 2566633982 FourHiSideVMinLmtSetting "Reports the active minimum limit on the high side voltage of the DC/DC Converter.  The setting may be requested by a separate device (see SPN 9054) or determined by the DC/DC Controller based on operating conditions.";
CM_ BO_ 2566633726 "DC/DC Converter 4 Lifetime Data
Contains data accumulated over the lifetime of a DC/DC Converter.";
CM_ SG_ 2566633726 FourTotalLowSideCharge "Indicates the total lifetime charge converted by the DC/DC  from the low side (e.g. SLI battery) during boost mode.";
CM_ SG_ 2566633726 FourTotalHiSideCharge "Indicates the total lifetime charge converted by the DC/DC from the high side (e.g. HVES) during buck mode.";
CM_ SG_ 2566633726 FourTotalLowSideEnergy "Indicates the total lifetime energy converted by the DC/DC  from the low side (e.g. SLI battery) during boost mode.";
CM_ SG_ 2566633726 FourTotalHiSideEnergy "Indicates the total lifetime energy converted by the DC/DC from the high side (e.g. HVES) during buck mode.";
CM_ BO_ 2566633470 "Aftertreatment 1 Intake Gas 4
The purpose of this PGN is to group the aftertreatment intake sensor data for bank 1.  These values include the NOx, %O2 , status of the sensors with respect to the power being supplied and the heating element, errors ...";
CM_ SG_ 2566633470 O2PumpingCur "Electrical pumping current directly measured from a Lambda sensor for the purpose of calculating an air/fuel ratio.  This sensor is located furthest upstream of the intake of aftertreatment 1 system.
Negative electrical current values are possible ...";
CM_ BO_ 2566633214 "Aftertreatment 1 Outlet Gas 4
The purpose of this PGN is to group the aftertreatment outlet sensor data for bank 1.  These values include the NOx, %O2 , status of the sensors with respect to the power being supplied and the heating element, errors ...";
CM_ SG_ 2566633214 O2PumpingCur "Electrical pumping current directly measured from a Lambda sensor for the purpose of calculating an air/fuel ratio.  This sensor is located closest to the outlet of aftertreatment 1 system.
Negative electrical current values are possible with ...";
CM_ BO_ 2566632958 "Well Stimulation Pump Trip Hours
Communicates operating parameters of a well stimulation pump used in oil and gas drilling applications.";
CM_ SG_ 2566632958 PwrEndTripHours "The hours accumulated since the last power end replacement on the well stimulation pump (since the last reset of the trip meter).

This value will be reset by the user.";
CM_ SG_ 2566632958 FluidEndTripHours "The hours accumulated since the last fluid end replacement on the well stimulation pump (since the last reset of the trip meter).

This value will be reset by the user.";
CM_ BO_ 2566632702 "Well Stimulation Pump Serial Number
Communicates serial number information of a well stimulation pump fluid end and power end used in oil and gas drilling applications.";
CM_ SG_ 2566632702 FluidEndSerialNum "The serial number of the fluid end of a well stimulation pump.";
CM_ SG_ 2566632702 PwrEndSerialNum "The serial number of the power end of a well stimulation pump.";
CM_ BO_ 2566632446 "Well Stimulation Pump Fluid Volume
Communicates fluid information of a well stimulation pump used in oil and gas drilling applications.";
CM_ SG_ 2566632446 TripFluidPumped "Fluid pumped during all or part of a well stimulation operation.";
CM_ SG_ 2566632446 TotalFluidPumped "Accumulated amount of fluid pumped during well stimulation operation.";
CM_ BO_ 2566632190 "Well Stimulation Pump Sensor Calibration Status
Calibration setting status for the Well Stimulation Pump System.
NOTE - In response to a Request (PGN 59904), multiple instances of this message will be required to transmit data for all of the Well ...";
CM_ SG_ 2566632190 DisPressCalSetPointStatus "Indicates the state of the Calibrated Sensor.

00 = Not OK
01 = OK
10 = Error
11 = Not available";
CM_ SG_ 2566632190 DisPressCalSetPoint "Specifies the current discharge pressure whose calibration status is being reported. Multipoint calibration of the discharge pressure system is perfomed by increasing the pressure with up to 10 known calibration pressures. For each calibration ...";
CM_ SG_ 2566632190 SuctionPressCalSetPointStatus "Indicates the state of the Calibrated Sensor.

00 = Not OK
01 = OK
10 = Error
11 = Not available";
CM_ SG_ 2566632190 SuctionPressCalSetPoint "Specifies the current suction pressure whose calibration status is being reported. Multipoint calibration of the suction pressure system is perfomed by increasing the pressure with up to 10 known calibration pressures. For each calibration pressure, ...";
CM_ BO_ 2566631934 "DC/AC Accessory Inverter 5 Lifetime Data
Contains data accumulated over the lifetime of this DC/AC Accessory Inverter.";
CM_ SG_ 2566631934 TotalDCInputEnergy "Total lifetime energy converted by the DC/AC from the DC Side.";
CM_ SG_ 2566631934 TotalDCInputCharge "Total lifetime charge converted by the DC/AC from the DC Side.";
CM_ BO_ 2566631678 "DC/AC Accessory Inverter 5 Configuration 1
Reports the active configuration settings for this DC/AC Accessory Inverter.  Settings may be defined by the manufacturer, or set through use of limit PGNs (DCAC_AI5_DCL and DCAC_AI5_ACL).";
CM_ SG_ 2566631678 ACSideDefaultFreqCmdSetting "Reports the active AC Side Default Frequency Command Setting of the DC/AC Accessory Inverter.  The setting may be requested by a separate device (via SPN 9527).

Note: Report Not Available (FFh) when no default has been set.";
CM_ SG_ 2566631678 DCSideCurMinLmtSetting "Reports the active minimum limit on the DC Side input current of the DC/AC Accessory Inverter.  The setting may be requested by a separate device (via SPN 9554) or determined by the DC/AC Controller based on operating conditions.";
CM_ SG_ 2566631678 DCSideVMaxLmtSetting "Reports the active maximum limit on the DC Side input voltage of the DC/AC Accessory Inverter.  The setting may be requested by a separate device (via SPN 9553) or determined by the DC/AC Controller based on operating conditions.";
CM_ SG_ 2566631678 ACSideRMSCurMaxLmtSetting "Reports the active maximum limit on the AC side output RMS line current of the DC/AC Accessory Inverter.  The setting may be requested by a separate device (via SPN 9360) or determined by the DC/AC Controller based on operating conditions.";
CM_ SG_ 2566631678 ACSideRMSVMaxLmtSetting "Reports the active maximum limit on the AC Side output line to line RMS voltage of the DC/AC Accessory Inverter.  The setting may be requested by a separate device (via SPN 9359) or determined by the DC/AC Controller based on operating conditions.";
CM_ SG_ 2566631678 DCSideCurMaxLmtSetting "Reports the active maximum limit on the DC Side input current of the DC/AC Accessory Inverter.  The setting may be requested by a separate device (via SPN 9358) or determined by the DC/AC Controller based on operating conditions.";
CM_ SG_ 2566631678 DCSideVMinLmtSetting "Reports the active minimum limit on the DC Side input voltage of the DC/AC Accessory Inverter.  The setting may be requested by a separate device (via SPN 9357) or determined by the DC/AC Controller based on operating conditions.";
CM_ BO_ 2365304830 "DC/AC Accessory Inverter 5 AC Side Limits 
Sets the AC Side system limits for the transfer of energy between the HVES or high voltage system (i.e. DC Side) and the accessory loads (i.e. AC Side) in a hybrid or electric vehicle.";
CM_ SG_ 2365304830 DefaultFreqReq "This setting may be used to set a default frequency command for when communication has been lost with the controlling device.  When set to Not Available (FFh), no default setting is provided and the system should disable its output.";
CM_ SG_ 2365304830 RMSCurMaxLmtReq "The maximum allowed AC Side output RMS line current requested by a separate device.   Under normal conditions this requested limit would be reflected in SPN 9364.";
CM_ SG_ 2365304830 RMSVMaxLmtReq "The maximum allowed AC Side line to line RMS voltage requested by a separate device.   Under normal conditions this requested limit would be reflected in SPN 9363.";
CM_ BO_ 2365304574 "DC/AC Accessory Inverter 5 DC Side Limits 
Sets the HVES or High Voltage system limits for the transfer of energy between the high voltage system (i.e. DC side) and the accessory loads (i.e. AC side) in a hybrid or electric vehicle.";
CM_ SG_ 2365304574 CurMinLmtReq "The minimum allowed DC Side input current requested by a separate device.   Under normal conditions this requested limit would be reflected in SPN 9556.";
CM_ SG_ 2365304574 VMaxLmtReq "The maximum allowed DC Side input voltage requested by a separate device.   Under normal conditions this requested limit would be reflected in SPN 9555.";
CM_ SG_ 2365304574 CurMaxLmtReq "The maximum allowed DC Side input current requested by a separate device.   Under normal conditions this requested limit would be reflected in SPN 9362.";
CM_ SG_ 2365304574 VMinLmtReq "The minimum allowed DC Side input voltage requested by a separate device.   Under normal conditions this requested limit would be reflected in SPN 9361.";
CM_ BO_ 2566630910 "DC/AC Accessory Inverter 5 Temperatures
DC/AC Accessory Inverter measured temperature data.";
CM_ SG_ 2566630910 CoolantOutTemp "Temperature of the DC/AC Accessory Inverter Coolant measured at the output of the accessory inverter.";
CM_ SG_ 2566630910 CoolantInTemp "Temperature of the DC/AC Accessory Inverter Coolant measured at the input of the accessory inverter.";
CM_ SG_ 2566630910 PwrETemp "Temperature of the DC/AC Accessory Inverter power electronics components (e.g, switch or heatsink).";
CM_ SG_ 2566630910 InverterEFilterTemp "Temperature of the electronic components that make up the DC/AC Accessory Inverter filter.";
CM_ SG_ 2566630910 CtrlTemp "Temperature of the DC/AC Accessory Inverter (e.g, controller, circuit board, enclosure).";
CM_ BO_ 2566630654 "DC/AC Accessory Inverter 4 Lifetime Data
Contains data accumulated over the lifetime of this DC/AC Accessory Inverter.";
CM_ SG_ 2566630654 TotalDCInputEnergy "Total lifetime energy converted by the DC/AC from the DC Side.";
CM_ SG_ 2566630654 TotalDCInputCharge "Total lifetime charge converted by the DC/AC from the DC Side.";
CM_ BO_ 2566630398 "DC/AC Accessory Inverter 4 Configuration 1
Reports the active configuration settings for this DC/AC Accessory Inverter.  Settings may be defined by the manufacturer, or set through use of limit PGNs (DCAC_AI4_DCL and DCAC_AI4_ACL).";
CM_ SG_ 2566630398 ACSideDefaultFreqCmdSetting "Reports the active AC Side Default Frequency Command Setting of the DC/AC Accessory Inverter.  The setting may be requested by a separate device (via SPN 9526).

Note: Report Not Available (FFh) when no default has been set.";
CM_ SG_ 2566630398 DCSideCurMinLmtSetting "Reports the active minimum limit on the DC Side input current of the DC/AC Accessory Inverter.  The setting may be requested by a separate device (via SPN 9548) or determined by the DC/AC Controller based on operating conditions.";
CM_ SG_ 2566630398 DCSideVMaxLmtSetting "Reports the active maximum limit on the DC Side input voltage of the DC/AC Accessory Inverter.  The setting may be requested by a separate device (via SPN 9547) or determined by the DC/AC Controller based on operating conditions.";
CM_ SG_ 2566630398 ACSideRMSCurMaxLmtSetting "Reports the active maximum limit on the AC side output RMS line current of the DC/AC Accessory Inverter.  The setting may be requested by a separate device (via SPN 9314) or determined by the DC/AC Controller based on operating conditions.";
CM_ SG_ 2566630398 ACSideRMSVMaxLmtSetting "Reports the active maximum limit on the AC Side output line to line RMS voltage of the DC/AC Accessory Inverter.  The setting may be requested by a separate device (via SPN 9313) or determined by the DC/AC Controller based on operating conditions.";
CM_ SG_ 2566630398 DCSideCurMaxLmtSetting "Reports the active maximum limit on the DC Side input current of the DC/AC Accessory Inverter.  The setting may be requested by a separate device (via SPN 9312) or determined by the DC/AC Controller based on operating conditions.";
CM_ SG_ 2566630398 DCSideVMinLmtSetting "Reports the active minimum limit on the DC Side input voltage of the DC/AC Accessory Inverter.  The setting may be requested by a separate device (via SPN 9311) or determined by the DC/AC Controller based on operating conditions.";
CM_ BO_ 2365303550 "DC/AC Accessory Inverter 4 AC Side Limits 
Sets the AC Side system limits for the transfer of energy between the HVES or high voltage system (i.e. DC Side) and the accessory loads (i.e. AC Side) in a hybrid or electric vehicle.";
CM_ SG_ 2365303550 DefaultFreqReq "This setting may be used to set a default frequency command for when communication has been lost with the controlling device.  When set to Not Available (FFh), no default setting is provided and the system should disable its output.";
CM_ SG_ 2365303550 RMSCurMaxLmtReq "The maximum allowed AC Side output RMS line current requested by a separate device.   Under normal conditions this requested limit would be reflected in SPN 9318.";
CM_ SG_ 2365303550 RMSVMaxLmtReq "The maximum allowed AC Side line to line RMS voltage requested by a separate device.   Under normal conditions this requested limit would be reflected in SPN 9317.";
CM_ BO_ 2365303294 "DC/AC Accessory Inverter 4 DC Side Limits 
Sets the HVES or High Voltage system limits for the transfer of energy between the high voltage system (i.e. DC side) and the accessory loads (i.e. AC side) in a hybrid or electric vehicle.";
CM_ SG_ 2365303294 CurMinLmtReq "The minimum allowed DC Side input current requested by a separate device.   Under normal conditions this requested limit would be reflected in SPN 9550.";
CM_ SG_ 2365303294 VMaxLmtReq "The maximum allowed DC Side input voltage requested by a separate device.   Under normal conditions this requested limit would be reflected in SPN 9549.";
CM_ SG_ 2365303294 CurMaxLmtReq "The maximum allowed DC Side input current requested by a separate device.   Under normal conditions this requested limit would be reflected in SPN 9316.";
CM_ SG_ 2365303294 VMinLmtReq "The minimum allowed DC Side input voltage requested by a separate device.   Under normal conditions this requested limit would be reflected in SPN 9315.";
CM_ BO_ 2566629630 "DC/AC Accessory Inverter 4 Temperatures
DC/AC Accessory Inverter measured temperature data.";
CM_ SG_ 2566629630 CoolantOutTemp "Temperature of the DC/AC Accessory Inverter Coolant measured at the output of the accessory inverter.";
CM_ SG_ 2566629630 CoolantInTemp "Temperature of the DC/AC Accessory Inverter Coolant measured at the input of the accessory inverter.";
CM_ SG_ 2566629630 PwrETemp "Temperature of the DC/AC Accessory Inverter power electronics components (e.g, switch or heatsink).";
CM_ SG_ 2566629630 InverterEFilterTemp "Temperature of the electronic components that make up the DC/AC Accessory Inverter filter.";
CM_ SG_ 2566629630 CtrlTemp "Temperature of the DC/AC Accessory Inverter (e.g, controller, circuit board, enclosure).";
CM_ BO_ 2566629374 "DC/AC Accessory Inverter 3 Lifetime Data
Contains data accumulated over the lifetime of this DC/AC Accessory Inverter.";
CM_ SG_ 2566629374 TotalDCInputEnergy "Total lifetime energy converted by the DC/AC from the DC Side.";
CM_ SG_ 2566629374 TotalDCInputCharge "Total lifetime charge converted by the DC/AC from the DC Side.";
CM_ BO_ 2566629118 "DC/AC Accessory Inverter 3 Configuration 1
Reports the active configuration settings for this DC/AC Accessory Inverter.  Settings may be defined by the manufacturer, or set through use of limit PGNs (DCAC_AI3_DCL and DCAC_AI3_ACL).";
CM_ SG_ 2566629118 ACSideDefaultFreqCmdSetting "Reports the active AC Side Default Frequency Command Setting of the DC/AC Accessory Inverter.  The setting may be requested by a separate device (via SPN 9525).

Note: Report Not Available (FFh) when no default has been set.";
CM_ SG_ 2566629118 DCSideCurMinLmtSetting "Reports the active minimum limit on the DC Side input current of the DC/AC Accessory Inverter.  The setting may be requested by a separate device (via SPN 9542) or determined by the DC/AC Controller based on operating conditions.";
CM_ SG_ 2566629118 DCSideVMaxLmtSetting "Reports the active maximum limit on the DC Side input voltage of the DC/AC Accessory Inverter.  The setting may be requested by a separate device (via SPN 9541 or determined by the DC/AC Controller based on operating conditions.";
CM_ SG_ 2566629118 ACSideRMSCurMaxLmtSetting "Reports the active maximum limit on the AC side output RMS line current of the DC/AC Accessory Inverter.  The setting may be requested by a separate device (via SPN 9284) or determined by the DC/AC Controller based on operating conditions.";
CM_ SG_ 2566629118 ACSideRMSVMaxLmtSetting "Reports the active maximum limit on the AC Side output line to line RMS voltage of the DC/AC Accessory Inverter.  The setting may be requested by a separate device (via SPN 9283) or determined by the DC/AC Controller based on operating conditions.";
CM_ SG_ 2566629118 DCSideCurMaxLmtSetting "Reports the active maximum limit on the DC Side input current of the DC/AC Accessory Inverter.  The setting may be requested by a separate device (via SPN 9282) or determined by the DC/AC Controller based on operating conditions.";
CM_ SG_ 2566629118 DCSideVMinLmtSetting "Reports the active minimum limit on the DC Side input voltage of the DC/AC Accessory Inverter.  The setting may be requested by a separate device (via SPN 9281) or determined by the DC/AC Controller based on operating conditions.";
CM_ BO_ 2365302270 "DC/AC Accessory Inverter 3 AC Side Limits 
Sets the AC Side system limits for the transfer of energy between the HVES or high voltage system (i.e. DC Side) and the accessory loads (i.e. AC Side) in a hybrid or electric vehicle.";
CM_ SG_ 2365302270 DefaultFreqReq "This setting may be used to set a default frequency command for when communication has been lost with the controlling device.  When set to Not Available (FFh), no default setting is provided and the system should disable its output.";
CM_ SG_ 2365302270 RMSCurMaxLmtReq "The maximum allowed AC Side output RMS line current requested by a separate device.   Under normal conditions this requested limit would be reflected in SPN 9288.";
CM_ SG_ 2365302270 RMSVMaxLmtReq "The maximum allowed AC Side line to line RMS voltage requested by a separate device.   Under normal conditions this requested limit would be reflected in SPN 9287.";
CM_ BO_ 2365302014 "DC/AC Accessory Inverter 3 DC Side Limits 
Sets the HVES or High Voltage system limits for the transfer of energy between the high voltage system (i.e. DC side) and the accessory loads (i.e. AC side) in a hybrid or electric vehicle.";
CM_ SG_ 2365302014 CurMinLmtReq "The minimum allowed DC Side input current requested by a separate device.   Under normal conditions this requested limit would be reflected in SPN 9544.";
CM_ SG_ 2365302014 VMaxLmtReq "The maximum allowed DC Side input voltage requested by a separate device.   Under normal conditions this requested limit would be reflected in SPN 9543.";
CM_ SG_ 2365302014 CurMaxLmtReq "The maximum allowed DC Side input current requested by a separate device.   Under normal conditions this requested limit would be reflected in SPN 9286.";
CM_ SG_ 2365302014 VMinLmtReq "The minimum allowed DC Side input voltage requested by a separate device.   Under normal conditions this requested limit would be reflected in SPN 9285.";
CM_ BO_ 2566628350 "DC/AC Accessory Inverter 3 Temperatures
DC/AC Accessory Inverter measured temperature data.";
CM_ SG_ 2566628350 CoolantOutTemp "Temperature of the DC/AC Accessory Inverter Coolant measured at the output of the accessory inverter.";
CM_ SG_ 2566628350 CoolantInTemp "Temperature of the DC/AC Accessory Inverter Coolant measured at the input of the accessory inverter.";
CM_ SG_ 2566628350 PwrETemp "Temperature of the DC/AC Accessory Inverter power electronics components (e.g, switch or heatsink).";
CM_ SG_ 2566628350 InverterEFilterTemp "Temperature of the electronic components that make up the DC/AC Accessory Inverter filter.";
CM_ SG_ 2566628350 CtrlTemp "Temperature of the DC/AC Accessory Inverter (e.g, controller, circuit board, enclosure).";
CM_ BO_ 2566628094 "DC/AC Accessory Inverter 2 Lifetime Data
Contains data accumulated over the lifetime of this DC/AC Accessory Inverter.";
CM_ SG_ 2566628094 TotalDCInputEnergy "Total lifetime energy converted by the DC/AC from the DC Side.";
CM_ SG_ 2566628094 TotalDCInputCharge "Total lifetime charge converted by the DC/AC from the DC Side.";
CM_ BO_ 2566627838 "DC/AC Accessory Inverter 2 Configuration 1
Reports the active configuration settings for this DC/AC Accessory Inverter.  Settings may be defined by the manufacturer, or set through use of limit PGNs (DCAC_AI2_DCL and DCAC_AI2_ACL).";
CM_ SG_ 2566627838 ACSideDefaultFreqCmdSetting "Reports the active AC Side Default Frequency Command Setting of the DC/AC Accessory Inverter.  The setting may be requested by a separate device (via SPN 9524).

Note: Report Not Available (FFh) when no default has been set.";
CM_ SG_ 2566627838 DCSideCurMinLmtSetting "Reports the active minimum limit on the DC Side input current of the DC/AC Accessory Inverter.  The setting may be requested by a separate device (via SPN 9536) or determined by the DC/AC Controller based on operating conditions.";
CM_ SG_ 2566627838 DCSideVMaxLmtSetting "Reports the active maximum limit on the DC Side input voltage of the DC/AC Accessory Inverter.  The setting may be requested by a separate device (via SPN 9535) or determined by the DC/AC Controller based on operating conditions.";
CM_ SG_ 2566627838 ACSideRMSCurMaxLmtSetting "Reports the active maximum limit on the AC side output RMS line current of the DC/AC Accessory Inverter.  The setting may be requested by a separate device (via SPN 9254) or determined by the DC/AC Controller based on operating conditions.";
CM_ SG_ 2566627838 ACSideRMSVMaxLmtSetting "Reports the active maximum limit on the AC Side output line to line RMS voltage of the DC/AC Accessory Inverter.  The setting may be requested by a separate device (via SPN 9253) or determined by the DC/AC Controller based on operating conditions.";
CM_ SG_ 2566627838 DCSideCurMaxLmtSetting "Reports the active maximum limit on the DC Side input current of the DC/AC Accessory Inverter.  The setting may be requested by a separate device (via SPN 9252) or determined by the DC/AC Controller based on operating conditions.";
CM_ SG_ 2566627838 DCSideVMinLmtSetting "Reports the active minimum limit on the DC Side input voltage of the DC/AC Accessory Inverter.  The setting may be requested by a separate device (via SPN 9251) or determined by the DC/AC Controller based on operating conditions.";
CM_ BO_ 2365300990 "DC/AC Accessory Inverter 2 AC Side Limits 
Sets the AC Side system limits for the transfer of energy between the HVES or high voltage system (i.e. DC Side) and the accessory loads (i.e. AC Side) in a hybrid or electric vehicle.";
CM_ SG_ 2365300990 DefaultFreqReq "This setting may be used to set a default frequency command for when communication has been lost with the controlling device.  When set to Not Available (FFh), no default setting is provided and the system should disable its output.";
CM_ SG_ 2365300990 RMSCurMaxLmtReq "The maximum allowed AC Side output RMS line current requested by a separate device.   Under normal conditions this requested limit would be reflected in SPN 9258.";
CM_ SG_ 2365300990 RMSVMaxLmtReq "The maximum allowed AC Side line to line RMS voltage requested by a separate device.   Under normal conditions this requested limit would be reflected in SPN 9257.";
CM_ BO_ 2365300734 "DC/AC Accessory Inverter 2 DC Side Limits 
Sets the HVES or High Voltage system limits for the transfer of energy between the high voltage system (i.e. DC side) and the accessory loads (i.e. AC side) in a hybrid or electric vehicle.";
CM_ SG_ 2365300734 CurMinLmtReq "The minimum allowed DC Side input current requested by a separate device.   Under normal conditions this requested limit would be reflected in SPN 9538.";
CM_ SG_ 2365300734 VMaxLmtReq "The maximum allowed DC Side input voltage requested by a separate device.   Under normal conditions this requested limit would be reflected in SPN 9537.";
CM_ SG_ 2365300734 CurMaxLmtReq "The maximum allowed DC Side input current requested by a separate device.   Under normal conditions this requested limit would be reflected in SPN 9256.";
CM_ SG_ 2365300734 VMinLmtReq "The minimum allowed DC Side input voltage requested by a separate device.   Under normal conditions this requested limit would be reflected in SPN 9255.";
CM_ BO_ 2566627070 "DC/AC Accessory Inverter 2 Temperatures
DC/AC Accessory Inverter measured temperature data.";
CM_ SG_ 2566627070 CoolantOutTemp "Temperature of the DC/AC Accessory Inverter Coolant measured at the output of the accessory inverter.";
CM_ SG_ 2566627070 CoolantInTemp "Temperature of the DC/AC Accessory Inverter Coolant measured at the input of the accessory inverter.";
CM_ SG_ 2566627070 PwrETemp "Temperature of the DC/AC Accessory Inverter power electronics components (e.g, switch or heatsink).";
CM_ SG_ 2566627070 InverterEFilterTemp "Temperature of the electronic components that make up the DC/AC Accessory Inverter filter.";
CM_ SG_ 2566627070 CtrlTemp "Temperature of the DC/AC Accessory Inverter (e.g, controller, circuit board, enclosure).";
CM_ BO_ 2566626814 "DC/AC Accessory Inverter 1 Lifetime Data
Contains data accumulated over the lifetime of this DC/AC Accessory Inverter.";
CM_ SG_ 2566626814 TotalDCInputEnergy "Total lifetime energy converted by the DC/AC from the DC Side.";
CM_ SG_ 2566626814 TotalDCInputCharge "Total lifetime charge converted by the DC/AC from the DC Side.";
CM_ BO_ 2566626558 "DC/AC Accessory Inverter 1 Configuration 1
Reports the active configuration settings for this DC/AC Accessory Inverter.  Settings may be defined by the manufacturer, or set through use of limit PGNs (DCAC_AI1_DCL and DCAC_AI1_ACL).";
CM_ SG_ 2566626558 ACSideDefaultFreqCmdSetting "Reports the active AC Side Default Frequency Command Setting of the DC/AC Accessory Inverter.  The setting may be requested by a separate device (via SPN 9523).

Note: Report Not Available (FFh) when no default has been set.";
CM_ SG_ 2566626558 DCSideCurMinLmtSetting "Reports the active minimum limit on the DC Side input current of the DC/AC Accessory Inverter.  The setting may be requested by a separate device (via SPN 9530) or determined by the DC/AC Controller based on operating conditions.";
CM_ SG_ 2566626558 DCSideVMaxLmtSetting "Reports the active maximum limit on the DC Side input voltage of the DC/AC Accessory Inverter.  The setting may be requested by a separate device (via SPN 9529) or determined by the DC/AC Controller based on operating conditions.";
CM_ SG_ 2566626558 ACSideRMSCurMaxLmtSetting "Reports the active maximum limit on the AC side output RMS line current of the DC/AC Accessory Inverter.  The setting may be requested by a separate device (via SPN 9224) or determined by the DC/AC Controller based on operating conditions.";
CM_ SG_ 2566626558 ACSideRMSVMaxLmtSetting "Reports the active maximum limit on the AC Side output line to line RMS voltage of the DC/AC Accessory Inverter.  The setting may be requested by a separate device (via SPN 9223) or determined by the DC/AC Controller based on operating conditions.";
CM_ SG_ 2566626558 DCSideCurMaxLmtSetting "Reports the active maximum limit on the DC Side input current of the DC/AC Accessory Inverter.  The setting may be requested by a separate device (via SPN 9222) or determined by the DC/AC Controller based on operating conditions.";
CM_ SG_ 2566626558 DCSideVMinLmtSetting "Reports the active minimum limit on the DC Side input voltage of the DC/AC Accessory Inverter.  The setting may be requested by a separate device (via SPN 9221) or determined by the DC/AC Controller based on operating conditions.";
CM_ BO_ 2365299710 "DC/AC Accessory Inverter 1 AC Side Limits 
Sets the AC Side system limits for the transfer of energy between the HVES or high voltage system (i.e. DC Side) and the accessory loads (i.e. AC Side) in a hybrid or electric vehicle.";
CM_ SG_ 2365299710 DefaultFreqReq "This setting may be used to set a default frequency command for when communication has been lost with the controlling device.  When set to Not Available (FFh), no default setting is provided and the system should disable its output.";
CM_ SG_ 2365299710 RMSCurMaxLmtReq "The maximum allowed AC Side output RMS line current requested by a separate device.   Under normal conditions this requested limit would be reflected in SPN 9228.";
CM_ SG_ 2365299710 RMSVMaxLmtReq "The maximum allowed AC Side line to line RMS voltage requested by a separate device.   Under normal conditions this requested limit would be reflected in SPN 9227.";
CM_ BO_ 2365299454 "DC/AC Accessory Inverter 1 DC Side Limits 
Sets the HVES or High Voltage system limits for the transfer of energy between the high voltage system (i.e. DC side) and the accessory loads (i.e. AC side) in a hybrid or electric vehicle.";
CM_ SG_ 2365299454 CurMinLmtReq "The minimum allowed DC Side input current requested by a separate device.   Under normal conditions this requested limit would be reflected in SPN 9532.";
CM_ SG_ 2365299454 VMaxLmtReq "The maximum allowed DC Side input voltage requested by a separate device.   Under normal conditions this requested limit would be reflected in SPN 9531.";
CM_ SG_ 2365299454 CurMaxLmtReq "The maximum allowed DC Side input current requested by a separate device.   Under normal conditions this requested limit would be reflected in SPN 9226.";
CM_ SG_ 2365299454 VMinLmtReq "The minimum allowed DC Side input voltage requested by a separate device.   Under normal conditions this requested limit would be reflected in SPN 9225.";
CM_ BO_ 2566625790 "DC/AC Accessory Inverter 1 Temperatures
DC/AC Accessory Inverter measured temperature data.";
CM_ SG_ 2566625790 CoolantOutTemp "Temperature of the DC/AC Accessory Inverter Coolant measured at the output of the accessory inverter.";
CM_ SG_ 2566625790 CoolantInTemp "Temperature of the DC/AC Accessory Inverter Coolant measured at the input of the accessory inverter.";
CM_ SG_ 2566625790 PwrETemp "Temperature of the DC/AC Accessory Inverter power electronics components (e.g, switch or heatsink).";
CM_ SG_ 2566625790 InverterEFilterTemp "Temperature of the electronic components that make up the DC/AC Accessory Inverter filter.";
CM_ SG_ 2566625790 CtrlTemp "Temperature of the DC/AC Accessory Inverter (e.g, controller, circuit board, enclosure).";
CM_ BO_ 2633734398 "Exhaust Oxygen 2
Contains information which relates to the exhaust particulate control system on the engine.";
CM_ SG_ 2633734398 EngActualExh2O2 "The actual amount of oxygen in the second exhaust represented as a percentage by volume with respect to the total volume of exhaust gases leaving the engine.";
CM_ BO_ 2566625278 "Vehicle Electrical Power 15
Battery capacity setting parameters for SLI Battery Pack 1.";
CM_ SG_ 2566625278 SLIBatPack1Bat4CapacitySetting "Informs the battery controller of the capacity of its associated battery.  This parameter applies to the fourth battery in the first set of batteries (battery pack) used for starting the engine, for lighting, and for ignition (SLI).";
CM_ SG_ 2566625278 SLIBatPack1Bat3CapacitySetting "Informs the battery controller of the capacity of its associated battery.  This parameter applies to the third battery in the first set of batteries (battery pack) used for starting the engine, for lighting, and for ignition (SLI) .";
CM_ SG_ 2566625278 SLIBatPack1Bat2CapacitySetting "Informs the battery controller of the capacity of its associated battery.  This parameter applies to the second battery in the first set of batteries (battery pack) used for starting the engine, for lighting, and for ignition (SLI) .";
CM_ SG_ 2566625278 SLIBatPack1Bat1CapacitySetting "Informs the battery controller of the capacity of its associated battery.  This parameter applies to the first battery in the first set of batteries (battery pack) used for starting the engine, for lighting, and for ignition (SLI) .";
CM_ BO_ 2566625022 "Engine Information 3
Third PGN conveying engine information";
CM_ SG_ 2566625022 InstantaneousEstEngPwrRateLmt "Estimate of the maximum power load rate the engine can sustain at that moment in time.";
CM_ BO_ 2566624766 "Engine Hours 2
Second PGN for engine hours information";
CM_ SG_ 2566624766 IdleMnmgtActiveTotalTime "Total accumulated time the engine is off due to the engine idle management system.";
CM_ BO_ 2566624510 "Electronic Engine Controller 22
Engine related parameters";
CM_ SG_ 2566624510 EGR1CoolerInPress "Exhaust gas recirculation gage pressure is measured at the EGR cooler intake.";
CM_ BO_ 2365297662 "DC/DC Converter 1 Voltage
Low Voltage data from DC/DC Converter.";
CM_ SG_ 2365297662 OneCtrlInputSLIV "Voltage (i.e not switched) supplied to the DC/DC Converter controller.";
CM_ SG_ 2365297662 OneCtrlInputIgntV "Ignition voltage (i.e. switched) supplied to the  DC/DC Converter controller.";
CM_ BO_ 2365297406 "DC/DC Converter 2 Voltage
Low Voltage data from DC/DC Converter.";
CM_ SG_ 2365297406 TwoCtrlInputSLIV "Voltage (i.e not switched) supplied to the DC/DC Converter controller.";
CM_ SG_ 2365297406 TwoCtrlInputIgntV "Ignition voltage (i.e. switched) supplied to the  DC/DC Converter controller.";
CM_ BO_ 2365297150 "DC/DC Converter 3 Voltage
Low Voltage data from DC/DC Converter.";
CM_ SG_ 2365297150 ThreeCtrlInputSLIV "Voltage (i.e not switched) supplied to the DC/DC Converter controller.";
CM_ SG_ 2365297150 ThreeCtrlInputIgntV "Ignition voltage (i.e. switched) supplied to the  DC/DC Converter controller.";
CM_ BO_ 2365296894 "DC/DC Converter 4 Voltage
Low Voltage data from DC/DC Converter.";
CM_ SG_ 2365296894 FourCtrlInputSLIV "Voltage (i.e not switched) supplied to the DC/DC Converter controller.";
CM_ SG_ 2365296894 FourCtrlInputIgntV "Ignition voltage (i.e. switched) supplied to the  DC/DC Converter controller.";
CM_ BO_ 2566623230 "Economy Mode Estimated Fuel Savings
Economy mode estimated fuel related parameters";
CM_ SG_ 2566623230 TripEstFuelSaved "Total volume of estimated fuel saved during all or part of a journey while operating in economy mode, since the last trip reset. This is in comparison to operating in a non-economy mode.";
CM_ SG_ 2566623230 TotalEstFuelSaved "Total volume of estimated fuel saved during economy mode of operation over the lifetime of the application. This is in comparison to operating in a non-economy mode.";
CM_ BO_ 2566622974 "Economy Mode Fuel Used
Amount of fuel consumed while economy mode is active.";
CM_ SG_ 2566622974 TripFuelUsed "Total volume of fuel used during all or part of a journey while operating in economy mode, since the last trip reset.";
CM_ SG_ 2566622974 TotalFuelUsed "Total volume of fuel used during economy mode operation over the lifetime of the application.";
CM_ BO_ 2566622718 "Economy Mode Active Hours
Accumulated time of operation while economy mode is active.";
CM_ SG_ 2566622718 TripHoursActive "Total accumulated operating time in economy mode since the last trip reset.";
CM_ SG_ 2566622718 TotalHoursActive "Total accumulated operating time in economy mode over the lifetime of the application.";
CM_ BO_ 2566622462 "Economy Mode Estimated Instantaneous Fuel Savings Rate
Fuel savings rate estimations while economy mode is active.";
CM_ SG_ 2566622462 Percent "Estimated instantaneous fuel savings rate percentage while operating in economy mode. This value is calculated by dividing Economy Mode Estimated Instantaneous Fuel Savings Percent (SPN 9576) by the current non-economy mode estimated instantaneous ...";
CM_ SG_ 2566622462 RateAbsolute "Estimated instantaneous fuel savings rate while operating in economy mode.  This is in comparison to operating in a non-economy mode.";
CM_ BO_ 2566622206 "Economy Mode Inactive Hours
Accumulated time of operation while economy mode is installed but not in use.";
CM_ SG_ 2566622206 TripHoursInactive "Trip operating time accumulated while economy mode is installed but not in use, since last trip reset.";
CM_ SG_ 2566622206 TotalHoursInactive "Total accumulated operating time while economy mode is installed but not in use.";
CM_ BO_ 2365295358 "High Voltage Energy Storage 1 Data 11
Data set 11 (electrical data) for High Voltage Energy Storage pack (or system) 1.";
CM_ SG_ 2365295358 LvlNegToChassisGroundV "Voltage difference between the most negative terminal of the HVES battery and chassis measured at the battery side of any HVES contained output contactor.  This voltage may be used for system level monitoring of battery shorts to chassis within the ...";
CM_ SG_ 2365295358 BusVNegToChassisGroundV "Voltage difference between the most negative terminal of the HVES battery and chassis measured on the hybrid system bus side (not the battery side) of any HVES contained output contactor.  This voltage may be used for system level monitoring of ...";
CM_ BO_ 2566621694 "Engine Fluid Level/Pressure 13
13th PGN which identifies parameters that are either measuring various pressures within the engine or identifying engine fluid levels";
CM_ SG_ 2566621694 OilPress2 "Gage pressure of oil in engine lubrication system as provided by oil pump - second instance.";
CM_ BO_ 2566621438 "Marine Control Information 3
Marine vessel control information for the vessel control system.";
CM_ SG_ 2566621438 SlowVesselModeLampStatus "Reports when the slow vessel mode lamp is illuminated.

00b - Off
01b - On
10b - Error
11b - Not Available";
CM_ SG_ 2566621438 GearLockoutLampStatus "Reports when the gear lockout lamp is illuminated.

00b - Off
01b - On
10b - Error
11b - Not Available";
CM_ SG_ 2566621438 EngThrotLeverSynchLampStatus "Reports when the throttle lever synchronization lamp is illuminated. When synchronization mode is activated, an operator uses one throttle lever to control the speed of multiple engines.

00b - Off
01b - On
10b - Error
11b - Not Available";
CM_ SG_ 2566621438 TrollingModeLampStatus "Reports when the trolling mode lamp is illuminated.

00b - Off
01b - On
10b - Error
11b - Not Available";
CM_ SG_ 2566621438 OpStationActiveLampStatus "Reports when the operator station active lamp is illuminated.

00b - Off
01b - On
10b - Error
11b - Not Available";
CM_ SG_ 2566621438 SlowVesselModeButtonStatus "Reports when the slow vessel mode button has been pressed.

00b - Button not pressed
01b - Button pressed
10b - Error
11b - Not Available";
CM_ SG_ 2566621438 GearLockoutButtonStatus "This button is used to prevent the transmissions from being shifted into gear. When the button is pressed, the transmissions will be locked in neutral.

00b - Button not pressed
01b - Button pressed
10b - Error
11b - Not Available";
CM_ SG_ 2566621438 EngThrotLeverSynchButtonStatus "The button that is used to enable or disable syncronization of the engine throttles. When synchronization mode is activated, an operator uses one throttle lever to control the speed of multiple engines.
00b - Button not pressed
01b - Button ...";
CM_ SG_ 2566621438 TrollingModeButtonStatus "The button used to change the current type of trolling mode that is selected.

00b - Button not pressed
01b - Button pressed
10b - Error
11b - Not Available";
CM_ SG_ 2566621438 OpStationActiveButtonStatus "The button used to request a station to become the active station when another station is currently in control.

00b - Button not pressed
01b - Button pressed
10b - Error
11b - Not Available";
CM_ SG_ 2566621438 StationGearPosMatch "Indicates whether the gear position at the currently selected station is in neutral and the gear lever position at the station where the transfer is occuring is in neutral in order to allow the transfer to occur.
00b - Neutral
01b - Not in neutral
 ...";
CM_ SG_ 2566621438 StationThrotPosMatch "Indicates whether the throttle position at the currently selected station and the throttle lever position at the station where the transfer is occuring is within the correct range to allow the transfer to occur.
00b - Throttle positions do not ...";
CM_ BO_ 2566620670 "Engine Idle Management Information
Engine Idle Management Information";
CM_ SG_ 2566620670 ShutdownReason "Used to indicate the condition requesting the engine to shutdown when the idle management system is active.
0000b - Operator input request
0001b - Engine coolant temperature
0010b - Battery voltage
0011b - Transmission oil temperature
0100b - ...";
CM_ SG_ 2566620670 RestartReason "Used to indicate the condition requesting the engine to restart when the idle management system is active.
0000b - Operator input request
0001b - Low engine coolant temperature
0010b - Low battery voltage
0011b - Low transmission oil temperature
 ...";
CM_ SG_ 2566620670 Status "Indicates the current state or mode of operation by the engine idle manangement system.
0000b - Off
0001b - Locked
0010b - Disabled
0011b - Activation conditions not met (Not able to begin or continue due to current engine operating conditions)
 ...";
CM_ BO_ 2364620286 "Active Steering System Controls 1
Active Steering System Controls 1";
CM_ SG_ 2364620286 LaneCenteringSysStatus "Indicates the current state of the Lane Centering feature.
0000b - System is not ready (initialization not finished)
0001b - System is temporarily not available (not all activation conditions fulfulled)
0010b - System is deactivated by driver
 ...";
CM_ SG_ 2364620286 LaneCenteringIndEnableSt "Indicates whether lane centering indication is enabled.

00b - Lane Centering Indication disabled
01b - Lane Centering Indication enabled
10b - Error
11b - Not available";
CM_ SG_ 2364620286 DriverPref "Indicates the current preference for active steering mode selected by the driver.
000b - Active Steering Mode #1
001b - Active Steering Mode #2
010b - Active Steering Mode #3
011b - Active Steering Mode #4
100b - Active Steering Mode #5
101b - ...";
CM_ SG_ 2364620286 LaneKeepingAssistSysSt "Indicates the current state of the Lane Keep Assist feature.
0000b - System is not ready (initialization not finished)
0001b - System is temporarily not available (not all activation conditions fulfulled)
0010b - System is deactivated by driver
 ...";
CM_ SG_ 2364620286 LaneKeepingAssistIndEnableStatus "Indicates whether lane keeping assist is enabled.

00b - Lane Keeping Assist disabled
01b - Lane Keeping Assist enabled
10b - Error
11b - Not available";
CM_ SG_ 2364620286 LaneKeepingAssistStatusLeftSide "Indicates the current status of lane keeping assist feature for left side lane marker.
000b - Lane Keeping Assist Not Available for Left Side
001b - Lane Keeping Assist Available for Left Side
010b - Lane Keeping Assist Suppressed for Left Side
 ...";
CM_ SG_ 2364620286 LaneKeepingAssistStatusRightSide "Indicates the current status of lane keeping assist feature for right side lane marker.
000b - Lane Keeping Assist Not Available for Right Side
001b - Lane Keeping Assist Available for Right Side
010b - Lane Keeping Assist Suppressed for Right ...";
CM_ BO_ 2364620030 "Engine Pre-Chamber Fuel Valve Start of Actuation Command 5
Used to transmit the pre-chamber fuel valve start of activation command information for valve 17 to valve 20 associated with cylinders 17 through 20.";
CM_ SG_ 2364620030 Two0StartAct "The angle, relative to the TDC of cylinder 20 with 0 being the TDC before the power stroke commences, at the which pre-chamber fuel valve 20 is activated to open.";
CM_ SG_ 2364620030 One9StartAct "The angle, relative to the TDC of cylinder 19 with 0 being the TDC before the power stroke commences, at the which pre-chamber fuel valve 19 is activated to open.";
CM_ SG_ 2364620030 One8StartAct "The angle, relative to the TDC of cylinder 18 with 0 being the TDC before the power stroke commences, at the which pre-chamber fuel valve 18 is activated to open.";
CM_ SG_ 2364620030 One7StartAct "The angle, relative to the TDC of cylinder 17 with 0 being the TDC before the power stroke commences, at the which pre-chamber fuel valve 17 is activated to open.";
CM_ BO_ 2364619774 "Engine Pre-Chamber Fuel Valve Start of Actuation Command 4
Used to transmit the pre-chamber fuel valve start of activation command information for valve 13 to valve 16 associated with cylinders 13 through 16.";
CM_ SG_ 2364619774 One6StartAct "The angle, relative to the TDC of cylinder 16 with 0 being the TDC before the power stroke commences, at the which pre-chamber fuel valve 16 is activated to open.";
CM_ SG_ 2364619774 One5StartAct "The angle, relative to the TDC of cylinder 15 with 0 being the TDC before the power stroke commences, at the which pre-chamber fuel valve 15 is activated to open.";
CM_ SG_ 2364619774 One4StartAct "The angle, relative to the TDC of cylinder 14 with 0 being the TDC before the power stroke commences, at the which pre-chamber fuel valve 14 is activated to open.";
CM_ SG_ 2364619774 One3StartAct "The angle, relative to the TDC of cylinder 13 with 0 being the TDC before the power stroke commences, at the which pre-chamber fuel valve 13 is activated to open.";
CM_ BO_ 2364619518 "Engine Pre-Chamber Fuel Valve Start of Actuation Command 3
Used to transmit the pre-chamber fuel valve start of activation command information for valve 9 to valve 12 associated with cylinders 9 through 12.";
CM_ SG_ 2364619518 One2StartAct "The angle, relative to the TDC of cylinder 12 with 0 being the TDC before the power stroke commences, at the which pre-chamber fuel valve 12 is activated to open.";
CM_ SG_ 2364619518 One1StartAct "The angle, relative to the TDC of cylinder 11 with 0 being the TDC before the power stroke commences, at the which pre-chamber fuel valve 11 is activated to open.";
CM_ SG_ 2364619518 One0StartAct "The angle, relative to the TDC of cylinder 10 with 0 being the TDC before the power stroke commences, at the which pre-chamber fuel valve 10 is activated to open.";
CM_ SG_ 2364619518 NineStartAct "The angle, relative to the TDC of cylinder 9 with 0 being the TDC before the power stroke commences, at the which pre-chamber fuel valve 9 is activated to open.";
CM_ BO_ 2364619262 "Engine Pre-Chamber Fuel Valve Start of Actuation Command 2
Used to transmit the pre-chamber fuel valve start of activation command information for valve 5 to valve 8 associated with cylinders 5 through 8.";
CM_ SG_ 2364619262 EightStartAct "The angle, relative to the TDC of cylinder 8 with 0 being the TDC before the power stroke commences, at the which pre-chamber fuel valve 8 is activated to open.";
CM_ SG_ 2364619262 SevenStartAct "The angle, relative to the TDC of cylinder 7 with 0 being the TDC before the power stroke commences, at the which pre-chamber fuel valve 7 is activated to open.";
CM_ SG_ 2364619262 SixStartAct "The angle, relative to the TDC of cylinder 6 with 0 being the TDC before the power stroke commences, at the which pre-chamber fuel valve 6 is activated to open.";
CM_ SG_ 2364619262 FiveStartAct "The angle, relative to the TDC of cylinder 5 with 0 being the TDC before the power stroke commences, at the which pre-chamber fuel valve 5 is activated to open.";
CM_ BO_ 2364619006 "Engine Pre-Chamber Fuel Valve Start of Actuation Command 1
Used to transmit the pre-chamber fuel valve start of activation command information for valve 1 to valve 4 associated with cylinders 1 through 4.";
CM_ SG_ 2364619006 FourStartAct "The angle, relative to the TDC of cylinder 4 with 0 being the TDC before the power stroke commences, at the which pre-chamber fuel valve 4 is activated to open.";
CM_ SG_ 2364619006 ThreeStartAct "The angle, relative to the TDC of cylinder 3 with 0 being the TDC before the power stroke commences, at the which pre-chamber fuel valve 3 is activated to open.";
CM_ SG_ 2364619006 TwoStartAct "The angle, relative to the TDC of cylinder 2 with 0 being the TDC before the power stroke commences, at the which pre-chamber fuel valve 2 is activated to open.";
CM_ SG_ 2364619006 OneStartAct "The angle, relative to the TDC of cylinder 1 with 0 being the TDC before the power stroke commences, at the which pre-chamber fuel valve 1 is activated to open.";
CM_ BO_ 2364618750 "Engine Pre-Chamber Fuel Valve Duration Command 5
Used to transmit the pre-chamber fuel valve duration command information for valve 17 to valve 20";
CM_ SG_ 2364618750 Two0Dur "Amount of time the pre-chamber fuel valve 20 is activated.";
CM_ SG_ 2364618750 One9Dur "Amount of time the pre-chamber fuel valve 19 is activated.";
CM_ SG_ 2364618750 One8Dur "Amount of time the pre-chamber fuel valve 18 is activated.";
CM_ SG_ 2364618750 One7Dur "Amount of time the pre-chamber fuel valve 17 is activated.";
CM_ BO_ 2364618494 "Engine Pre-Chamber Fuel Valve Duration Command 4
Used to transmit the pre-chamber fuel valve duration command information for valve 13 to valve 16";
CM_ SG_ 2364618494 One6Dur "Amount of time the pre-chamber fuel valve 16 is activated.";
CM_ SG_ 2364618494 One5Dur "Amount of time the pre-chamber fuel valve 15 is activated.";
CM_ SG_ 2364618494 One4Dur "Amount of time the pre-chamber fuel valve 14 is activated.";
CM_ SG_ 2364618494 One3Dur "Amount of time the pre-chamber fuel valve 13 is activated.";
CM_ BO_ 2364618238 "Engine Pre-Chamber Fuel Valve Duration Command 3
Used to transmit the pre-chamber fuel valve duration command information for valve 9 to valve 12";
CM_ SG_ 2364618238 One2Dur "Amount of time the pre-chamber fuel valve 12 is activated.";
CM_ SG_ 2364618238 One1Dur "Amount of time the pre-chamber fuel valve 11 is activated.";
CM_ SG_ 2364618238 One0Dur "Amount of time the pre-chamber fuel valve 10 is activated.";
CM_ SG_ 2364618238 NineDur "Amount of time the pre-chamber fuel valve 9 is activated.";
CM_ BO_ 2364617982 "Engine Pre-Chamber Fuel Valve Duration Command 2
Used to transmit the pre-chamber fuel valve duration command information for valve 5 to valve 8";
CM_ SG_ 2364617982 EightDur "Amount of time the pre-chamber fuel valve 8 is activated.";
CM_ SG_ 2364617982 SevenDur "Amount of time the pre-chamber fuel valve 7 is activated.";
CM_ SG_ 2364617982 SixDur "Amount of time the pre-chamber fuel valve 6 is activated.";
CM_ SG_ 2364617982 FiveDur "Amount of time the pre-chamber fuel valve 5 is activated.";
CM_ BO_ 2364617726 "Engine Pre-Chamber Fuel Valve Duration Command 1
Used to transmit the pre-chamber fuel valve duration command information for valve 1 to valve 4";
CM_ SG_ 2364617726 FourDur "Amount of time the pre-chamber fuel valve 4 is activated.";
CM_ SG_ 2364617726 ThreeDur "Amount of time the pre-chamber fuel valve 3 is activated.";
CM_ SG_ 2364617726 TwoDur "Amount of time the pre-chamber fuel valve 2 is activated.";
CM_ SG_ 2364617726 OneDur "Amount of time the pre-chamber fuel valve 1 is activated.";
CM_ BO_ 2565944062 "DC/AC Accessory Inverter 5 Feedback 2
Sent by this Accessory Inverter instance and contains the current operating conditions of this output of the inverter.  This message would be received by a controller application (e.g. Power System Manager) ...";
CM_ SG_ 2565944062 PLedDueToUndefinedReason "Output power is being limited due to an undefined reason.

00 - No power limit for this reason
01 - Power limited for this reason
10 - Error
11 - Not Available";
CM_ SG_ 2565944062 PLedDueToRateOfChangeLmt "Output power is being limited due to the frequency approaching or exceeding the rate of change limit (see SPN 9325).

00 - No frequency limit for this reason
01 - Frequency limited for this reason
10 - Error
11 - Not Available";
CM_ SG_ 2565944062 PLedDueToPwrETemp "Output power is being limited due to power electronics temperature (see SPN 9339) approaching or exceeding the maximum limit.

00 - No frequency limit for this reason
01 - Frequency limited for this reason
10 - Error
11 - Not Available";
CM_ SG_ 2565944062 PLedDueToEFilterTemp "Output power is being limited due to electronic filter temperature (see SPN 9338) approaching or exceeding the maximum limit.

00 - No frequency limit for this reason
01 - Frequency limited for this reason
10 - Error
11 - Not Available";
CM_ SG_ 2565944062 PLedDueToCtrlTemp "Output power is being limited due to the controller temperature (see SPN 9337) approaching or exceeding the maximum limit.

00 - No power limit for this reason
01 - Power limited for this reason
10 - Error
11 - Not Available";
CM_ SG_ 2565944062 FreqCmdExceedsMax "Output frequency is being limited due to frequency command (see SPN 9326) approaching or exceeding the maximum limit (SPN 9321).

00 - No frequency limit for this reason
01 - Frequency limited for this reason
10 - Error
11 - Not Available";
CM_ SG_ 2565944062 FreqCmdBelowMin "Output frequency is being limited due to frequency command (see SPN 9326) approaching or falling below the minimum limit (SPN 9322).

00 - No frequency limit for this reason
01 - Frequency limited for this reason
10 - Error
11 - Not Available";
CM_ SG_ 2565944062 PLedDueToDCSideVMin "Output power is being limited due to DC Side input voltage (see SPN 9343) approaching or falling below the minimum limit (SPN 9361).

00 - No power limit for this reason
01 - Power limited for this reason
10 - Error
11 - Not Available";
CM_ SG_ 2565944062 PLedDueToACSideRMSCur "AC Side Output power is being limited due to AC Side output RMS current (see SPN 9333) approaching or exceeding the maximum limit (See SPN 9364).
00 - No power limit for this reason
01 - Power limited for this reason
10 - Error
11 - Not ...";
CM_ SG_ 2565944062 PLedDueToDCSideCur "Output power is being limited due to DC Side input current (see SPN 9344) approaching or exceeding the maximum limit (See SPN 9362).

00 - No power limit for this reason
01 - Power limited for this reason
10 - Error
11 - Not Available";
CM_ BO_ 2364617214 "DC/AC Accessory Inverter 5 Voltage
Low Voltage data from DC/AC Accessory Inverter.";
CM_ SG_ 2364617214 SLIV "Low voltage (SLI) supplied to the DC/AC Accessory Inverter controller.";
CM_ SG_ 2364617214 IgntV "Ignition voltage supplied to the  DC/AC Accessory Inverter controller.";
CM_ BO_ 2364616958 "DC/AC Accessory Inverter 5 Status 2
Additional data reported from DC/AC Accessory Inverter";
CM_ SG_ 2364616958 DCSideNegToChassisGroundV "The voltage level of the high voltage DC side, as measured by the DC/AC between the negative side of the High Voltage DC Side input and the chassis of the DC/AC enclosure.  This voltage can be used for system level monitoring of DC Side High Voltage ...";
CM_ SG_ 2364616958 DCSideCur "DC Side input current measured at the point of control inside the DC/AC Accessory Inverter.";
CM_ SG_ 2364616958 DCSideV "DC Side input voltage measured at the point of control inside the DC/AC Accessory Inverter.";
CM_ SG_ 2364616958 DCSidePwr "Power measured at the DC Side input to the DC/AC Accessory Inverter.";
CM_ BO_ 2565943294 "DC/AC Accessory Inverter 5 Feedback
Sent by this DC/AC Accessory Inverter instance and contains the current operating conditions of this output of the inverter.  This message would be received by a controller application (e.g. Power System Manager) ...";
CM_ SG_ 2565943294 HVILStatus "High Voltage Interlock Loop (HVIL) state of the DC/AC Accessory Inverter 5.

00 - HVIL Closed
01 - HVIL Open
10 - Error
11 - Not Available";
CM_ SG_ 2565943294 LoadshedReq "Loadshed Request from this DC/AC Accessory Inverter output.  The Loadshed Requested state is an indication that the inverter output powering this device has a malfunction and is in a limit condition and if the load of the output is not reduced, the ...";
CM_ SG_ 2565943294 OperationalStatus "Operating Status of this DC/AC Accessory Inverter output. The Inverter Output Faulted state will be communicated when the inverter output has shutdown due to an overload condition or other fault.
000 - Output Disabled
001 - Output Enabled
010 - ...";
CM_ SG_ 2565943294 ACSideRMSCur "Present operating AC Side output RMS line Current of this DC/AC Accessory Inverter.  When connected to a balanced three phase motor, this would be the current in each individual phase of the motor.";
CM_ SG_ 2565943294 ACSidePwr "Present operating AC Side power of this DC/AC Accessory Inverter output.";
CM_ SG_ 2565943294 ACSideRMSV "Present operating AC Side line to line RMS voltage of this DC/AC Accessory Inverter output.  In a three phase balanced motor, this is the RMS voltage across one phase of the motor.";
CM_ SG_ 2565943294 Freq "Present operating frequency of this DC/AC Accessory Inverter output.";
CM_ BO_ 2565943038 "DC/AC Accessory Inverter 5 Command
Used to command this instance of an DC/AC Accessory Inverter that uses a V/Hz algorithm.  The Inverter may have multiple outputs to power accessories on a vehicle (e.g. HVAC compressor, air compressor, power ...";
CM_ SG_ 2565943038 ACSideMotorStartingRMSVReq "Signal to the DC/AC Accessory Inverter indicating the requested AC side RMS voltage for starting the attached accessory motor.   In a V/Hz variable speed motor control application, this voltage typically may be set to a non-zero value when an ...";
CM_ SG_ 2565943038 OperationalCmd "Command to the DC/AC Accessory Inverter to enable this output.  Each output may control multiple devices (e.g. electric motors) if they all operate at the same frequency.
00 - Disable DC/AC Accessory Inverter Output
01 - Enable DC/AC Accessory ...";
CM_ SG_ 2565943038 Device2Status "Signal to the DC/AC Accessory Inverter indicating the state of the device attached to the inverter output.  Each output may control multiple devices (e.g. electric motors) if they all operate at the same frequency.
The Faulted Off state will be ...";
CM_ SG_ 2565943038 Device1Status "Signal to the DC/AC Accessory Inverter indicating the state of the device attached to the inverter output.  Each output may control multiple devices (e.g. electric motors) if they all operate at the same frequency.
The Faulted Off state will be ...";
CM_ SG_ 2565943038 FreqCmd "Command to the DC/AC Accessory Inverter indicating the Inverter frequency desired for the device(s) attached to the inverter output.  Each output may control multiple devices (e.g. electric motors) if they all operate at the same frequency.";
CM_ SG_ 2565943038 DeviceFreqRateOfChangeLmt "Signal to the DC/AC Accessory Inverter indicating the frequency rate of change limit of the device(s) attached to the inverter output (Note: Increasing and decreasing rates can be controlled by the same signal).  Each output may control multiple ...";
CM_ SG_ 2565943038 DeviceRatedRMSV "Signal to the DC/AC Accessory Inverter indicating the rated RMS voltage of the device(s) attached to the inverter output.   Each output may control multiple devices (e.g. electric motors) if they all operate at the same frequency.";
CM_ SG_ 2565943038 DeviceRatedFreq "Signal to the DC/AC Accessory Inverter indicating the rated frequency of the device(s) attached to the inverter output.  Each output may control multiple devices (e.g. electric motors) if they all operate at the same frequency.";
CM_ SG_ 2565943038 DeviceMinFreq "Signal to the DC/AC Accessory Inverter indicating the minimum frequency of the device(s) attached to the inverter output.  Each output may control multiple devices (e.g. electric motors) if they all operate at the same frequency.";
CM_ SG_ 2565943038 DeviceMaxFreq "Signal to the DC/AC Accessory Inverter indicating the maximum frequency of the devices(s) attached to the inverter output.  Each output may control multiple devices (e.g. electric motors) if they all operate at the same frequency.";
BA_DEF_  "DBName" STRING ;
BA_DEF_ SG_  "SigType" ENUM  "Default","Range","RangeSigned","ASCII","Discrete","Control","ReferencePGN","DTC","StringDelimiter","StringLength","StringLengthControl","MessageCounter","MessageChecksum";
BA_DEF_ SG_  "GenSigStartValue" INT 0 2147483647;
BA_DEF_ SG_  "GenSigSendType" ENUM  "Cyclic","OnWrite","OnWriteWithRepetition","OnChange","OnChangeWithRepetition","IfActive","IfActiveWithRepetition","NoSigSendType";
BA_DEF_ SG_  "GenSigILSupport" ENUM  "No","Yes";
BA_DEF_ SG_  "GenSigEVName" STRING ;
BA_DEF_ SG_  "SPN" INT 0 524287;
BA_DEF_ BO_  "TpJ1939VarDlc" ENUM  "No","Yes";
BA_DEF_ BO_  "GenMsgStartDelayTime" INT 0 100000;
BA_DEF_ BO_  "GenMsgILSupport" ENUM  "No","Yes";
BA_DEF_ BO_  "GenMsgDelayTime" INT 0 1000;
BA_DEF_ BO_  "GenMsgRequestable" INT 0 1;
BA_DEF_ BO_  "GenMsgSendType" ENUM  "cyclic","NotUsed","NotUsed","NotUsed","NotUsed","NotUsed","NotUsed","IfActive","noMsgSendType";
BA_DEF_ BO_  "VFrameFormat" ENUM  "StandardCAN","ExtendedCAN","reserved","J1939PG";
BA_DEF_ BO_  "GenMsgCycleTime" INT 0 3600000;
BA_DEF_ BU_  "NmStationAddress" INT 0 255;
BA_DEF_ BU_  "NmJ1939IndustryGroup" INT 0 7;
BA_DEF_ BU_  "NmJ1939System" INT 0 127;
BA_DEF_ BU_  "NmJ1939Function" INT 0 255;
BA_DEF_ BU_  "NmJ1939FunctionInstance" INT 0 7;
BA_DEF_ BU_  "NmJ1939ECUInstance" INT 0 3;
BA_DEF_  "SAE_J1939_DA_SpecVersion" STRING ;
BA_DEF_  "SAE_J1939_81_SpecVersion" STRING ;
BA_DEF_  "DatabaseVersion" STRING ;
BA_DEF_  "BusType" STRING ;
BA_DEF_  "ProtocolType" STRING ;
BA_DEF_  "SAE_J1939_75_SpecVersion" STRING ;
BA_DEF_  "SAE_J1939_21_SpecVersion" STRING ;
BA_DEF_  "SAE_J1939_73_SpecVersion" STRING ;
BA_DEF_  "SAE_J1939_71_SpecVersion" STRING ;
BA_DEF_ SG_  "SystemSignalLongSymbol" STRING ;
BA_DEF_DEF_  "DBName" "";
BA_DEF_DEF_  "SigType" "Default";
BA_DEF_DEF_  "GenSigStartValue" 0;
BA_DEF_DEF_  "GenSigSendType" "NoSigSendType";
BA_DEF_DEF_  "GenSigILSupport" "Yes";
BA_DEF_DEF_  "GenSigEVName" "Env@Nodename_@Signame";
BA_DEF_DEF_  "SPN" 0;
BA_DEF_DEF_  "TpJ1939VarDlc" "No";
BA_DEF_DEF_  "GenMsgStartDelayTime" 0;
BA_DEF_DEF_  "GenMsgILSupport" "Yes";
BA_DEF_DEF_  "GenMsgDelayTime" 0;
BA_DEF_DEF_  "GenMsgRequestable" 1;
BA_DEF_DEF_  "GenMsgSendType" "noMsgSendType";
BA_DEF_DEF_  "VFrameFormat" "J1939PG";
BA_DEF_DEF_  "GenMsgCycleTime" 0;
BA_DEF_DEF_  "NmStationAddress" 254;
BA_DEF_DEF_  "NmJ1939IndustryGroup" 0;
BA_DEF_DEF_  "NmJ1939System" 0;
BA_DEF_DEF_  "NmJ1939Function" 0;
BA_DEF_DEF_  "NmJ1939FunctionInstance" 0;
BA_DEF_DEF_  "NmJ1939ECUInstance" 0;
BA_DEF_DEF_  "SAE_J1939_DA_SpecVersion" "";
BA_DEF_DEF_  "SAE_J1939_81_SpecVersion" "";
BA_DEF_DEF_  "DatabaseVersion" "";
BA_DEF_DEF_  "BusType" "";
BA_DEF_DEF_  "ProtocolType" "";
BA_DEF_DEF_  "SAE_J1939_75_SpecVersion" "";
BA_DEF_DEF_  "SAE_J1939_21_SpecVersion" "";
BA_DEF_DEF_  "SAE_J1939_73_SpecVersion" "";
BA_DEF_DEF_  "SAE_J1939_71_SpecVersion" "";
BA_DEF_DEF_  "SystemSignalLongSymbol" "";
BA_ "SAE_J1939_71_SpecVersion" "2016-10";
BA_ "SAE_J1939_73_SpecVersion" "2013-07";
BA_ "SAE_J1939_21_SpecVersion" "2016-03";
BA_ "SAE_J1939_75_SpecVersion" "2015-11";
BA_ "ProtocolType" "J1939";
BA_ "BusType" "CAN";
BA_ "DatabaseVersion" "10.0";
BA_ "SAE_J1939_81_SpecVersion" "2017-03";
BA_ "SAE_J1939_DA_SpecVersion" "2018-02";
BA_ "DBName" "J1939";
BA_ "NmStationAddress" BU_ PowertrainControlModule 90;
BA_ "NmJ1939Function" BU_ AtmosphericSensor 76;
BA_ "NmStationAddress" BU_ AtmosphericSensor 89;
BA_ "NmJ1939FunctionInstance" BU_ SafetyRestraintSystem2 1;
BA_ "NmJ1939Function" BU_ SafetyRestraintSystem2 132;
BA_ "NmStationAddress" BU_ SafetyRestraintSystem2 88;
BA_ "NmJ1939ECUInstance" BU_ Aftertreatment_2_GasOutlet 1;
BA_ "NmJ1939FunctionInstance" BU_ Aftertreatment_2_GasOutlet 1;
BA_ "NmJ1939Function" BU_ Aftertreatment_2_GasOutlet 68;
BA_ "NmStationAddress" BU_ Aftertreatment_2_GasOutlet 87;
BA_ "NmJ1939FunctionInstance" BU_ Aftertreatment_2_GasIntake 1;
BA_ "NmJ1939Function" BU_ Aftertreatment_2_GasIntake 68;
BA_ "NmStationAddress" BU_ Aftertreatment_2_GasIntake 86;
BA_ "NmJ1939Function" BU_ DieselParticulateFilterControl 69;
BA_ "NmStationAddress" BU_ DieselParticulateFilterControl 85;
BA_ "NmJ1939Function" BU_ Turbocharger 133;
BA_ "NmStationAddress" BU_ Turbocharger 2;
BA_ "NmJ1939Function" BU_ SafetyRestraintSystem1 132;
BA_ "NmStationAddress" BU_ SafetyRestraintSystem1 83;
BA_ "NmJ1939FunctionInstance" BU_ CabDisplay2 1;
BA_ "NmJ1939Function" BU_ CabDisplay2 60;
BA_ "NmStationAddress" BU_ CabDisplay2 84;
BA_ "NmJ1939ECUInstance" BU_ Aftertreatment_1_GasOutlet 1;
BA_ "NmJ1939Function" BU_ Aftertreatment_1_GasOutlet 68;
BA_ "NmStationAddress" BU_ Aftertreatment_1_GasOutlet 82;
BA_ "NmJ1939Function" BU_ Aftertreatment_1_GasIntake 68;
BA_ "NmStationAddress" BU_ Aftertreatment_1_GasIntake 81;
BA_ "NmJ1939Function" BU_ OnBoardDataLogger 130;
BA_ "NmStationAddress" BU_ OnBoardDataLogger 251;
BA_ "NmJ1939FunctionInstance" BU_ OffBoardDiagnosticTool2 1;
BA_ "NmJ1939Function" BU_ OffBoardDiagnosticTool2 129;
BA_ "NmStationAddress" BU_ OffBoardDiagnosticTool2 250;
BA_ "NmJ1939Function" BU_ OffBoardDiagnosticTool1 129;
BA_ "NmStationAddress" BU_ OffBoardDiagnosticTool1 249;
BA_ "NmJ1939Function" BU_ FileServer 61;
BA_ "NmStationAddress" BU_ FileServer 248;
BA_ "NmJ1939FunctionInstance" BU_ ParkingBrakeController 1;
BA_ "NmJ1939Function" BU_ ParkingBrakeController 9;
BA_ "NmStationAddress" BU_ ParkingBrakeController 80;
BA_ "NmJ1939FunctionInstance" BU_ SeatController2 1;
BA_ "NmJ1939Function" BU_ SeatController2 40;
BA_ "NmStationAddress" BU_ SeatController2 79;
BA_ "NmJ1939Function" BU_ FanDriveController 58;
BA_ "NmStationAddress" BU_ FanDriveController 78;
BA_ "NmJ1939Function" BU_ SteeringColumnUnit 57;
BA_ "NmStationAddress" BU_ SteeringColumnUnit 77;
BA_ "NmJ1939Function" BU_ CommunicationUnitRadio 56;
BA_ "NmStationAddress" BU_ CommunicationUnitRadio 76;
BA_ "NmJ1939Function" BU_ CommunicationUnitSatellite 55;
BA_ "NmStationAddress" BU_ CommunicationUnitSatellite 75;
BA_ "NmJ1939Function" BU_ CommunicationUnitCellular 54;
BA_ "NmStationAddress" BU_ CommunicationUnitCellular 74;
BA_ "NmJ1939Function" BU_ PropulsionBatteryCharger 31;
BA_ "NmStationAddress" BU_ PropulsionBatteryCharger 73;
BA_ "NmJ1939FunctionInstance" BU_ ChassisController2 1;
BA_ "NmJ1939Function" BU_ ChassisController2 52;
BA_ "NmStationAddress" BU_ ChassisController2 72;
BA_ "NmJ1939Function" BU_ ChassisController1 52;
BA_ "NmStationAddress" BU_ ChassisController1 71;
BA_ "NmJ1939Function" BU_ EngineValveControl 63;
BA_ "NmStationAddress" BU_ EngineValveControl 70;
BA_ "NmJ1939FunctionInstance" BU_ AuxiliaryHeater2 1;
BA_ "NmJ1939Function" BU_ AuxiliaryHeater2 50;
BA_ "NmStationAddress" BU_ AuxiliaryHeater2 69;
BA_ "NmJ1939Function" BU_ AuxiliaryHeater1 50;
BA_ "NmStationAddress" BU_ AuxiliaryHeater1 68;
BA_ "NmJ1939Function" BU_ ClutchUnit 49;
BA_ "NmStationAddress" BU_ ClutchUnit 67;
BA_ "NmJ1939Function" BU_ RampControl 48;
BA_ "NmStationAddress" BU_ RampControl 66;
BA_ "NmJ1939Function" BU_ InformationSystem1 47;
BA_ "NmStationAddress" BU_ InformationSystem1 65;
BA_ "NmJ1939FunctionInstance" BU_ SuspensionSystemController2 1;
BA_ "NmJ1939Function" BU_ SuspensionSystemController2 35;
BA_ "NmStationAddress" BU_ SuspensionSystemController2 64;
BA_ "NmJ1939Function" BU_ OilSensor 46;
BA_ "NmStationAddress" BU_ OilSensor 63;
BA_ "NmJ1939Function" BU_ VehicleDynamicStability 45;
BA_ "NmStationAddress" BU_ VehicleDynamicStability 62;
BA_ "NmJ1939Function" BU_ ExhaustEmissionController 44;
BA_ "NmStationAddress" BU_ ExhaustEmissionController 61;
BA_ "NmJ1939FunctionInstance" BU_ TransmissionDisplay2 1;
BA_ "NmJ1939Function" BU_ TransmissionDisplay2 43;
BA_ "NmStationAddress" BU_ TransmissionDisplay2 60;
BA_ "NmJ1939Function" BU_ TransmissionDisplay1 43;
BA_ "NmStationAddress" BU_ TransmissionDisplay1 59;
BA_ "NmJ1939FunctionInstance" BU_ ClimateControl2 1;
BA_ "NmJ1939Function" BU_ ClimateControl2 21;
BA_ "NmStationAddress" BU_ ClimateControl2 58;
BA_ "NmJ1939Function" BU_ WaterPumpController 42;
BA_ "NmStationAddress" BU_ WaterPumpController 57;
BA_ "NmJ1939FunctionInstance" BU_ RearAxleSteeringController 1;
BA_ "NmJ1939Function" BU_ RearAxleSteeringController 16;
BA_ "NmStationAddress" BU_ RearAxleSteeringController 56;
BA_ "NmJ1939Function" BU_ LightingOperatorControl 41;
BA_ "NmStationAddress" BU_ LightingOperatorControl 55;
BA_ "NmJ1939Function" BU_ SeatController1 40;
BA_ "NmStationAddress" BU_ SeatController1 54;
BA_ "NmJ1939FunctionInstance" BU_ IgnitionController2 1;
BA_ "NmJ1939Function" BU_ IgnitionController2 39;
BA_ "NmStationAddress" BU_ IgnitionController2 53;
BA_ "NmJ1939Function" BU_ IgnitionController1 39;
BA_ "NmStationAddress" BU_ IgnitionController1 52;
BA_ "NmJ1939Function" BU_ TirePressureController 38;
BA_ "NmStationAddress" BU_ TirePressureController 51;
BA_ "NmJ1939FunctionInstance" BU_ CabController2 1;
BA_ "NmJ1939Function" BU_ CabController2 37;
BA_ "NmStationAddress" BU_ CabController2 50;
BA_ "NmJ1939Function" BU_ CabController1 37;
BA_ "NmStationAddress" BU_ CabController1 49;
BA_ "NmJ1939Function" BU_ PneumaticSystemController 36;
BA_ "NmStationAddress" BU_ PneumaticSystemController 48;
BA_ "NmJ1939Function" BU_ SuspensionSystemController1 35;
BA_ "NmStationAddress" BU_ SuspensionSystemController1 47;
BA_ "NmJ1939Function" BU_ HydraulicPumpController 34;
BA_ "NmStationAddress" BU_ HydraulicPumpController 46;
BA_ "NmJ1939Function" BU_ EnduranceBrakingSystem 64;
BA_ "NmStationAddress" BU_ EnduranceBrakingSystem 45;
BA_ "NmJ1939FunctionInstance" BU_ RetarderExhaustEngine2 1;
BA_ "NmJ1939Function" BU_ RetarderExhaustEngine2 12;
BA_ "NmStationAddress" BU_ RetarderExhaustEngine2 44;
BA_ "NmJ1939Function" BU_ OnBoardDiagnosticUnit 62;
BA_ "NmStationAddress" BU_ OnBoardDiagnosticUnit 43;
BA_ "NmJ1939Function" BU_ HeadwayController 32;
BA_ "NmStationAddress" BU_ HeadwayController 42;
BA_ "NmJ1939Function" BU_ RetarderExhaustEngine1 12;
BA_ "NmStationAddress" BU_ RetarderExhaustEngine1 41;
BA_ "NmJ1939Function" BU_ CabDisplay1 60;
BA_ "NmStationAddress" BU_ CabDisplay1 40;
BA_ "NmJ1939Function" BU_ ManagementComputer 30;
BA_ "NmStationAddress" BU_ ManagementComputer 39;
BA_ "NmJ1939Function" BU_ VirtualTerminal 29;
BA_ "NmStationAddress" BU_ VirtualTerminal 38;
BA_ "NmJ1939Function" BU_ OffVehicleGateway 28;
BA_ "NmStationAddress" BU_ OffVehicleGateway 37;
BA_ "NmJ1939Function" BU_ PowerTakeOffFront 27;
BA_ "NmStationAddress" BU_ PowerTakeOffFront 36;
BA_ "NmStationAddress" BU_ HitchControl 35;
BA_ "NmJ1939Function" BU_ AuxiliaryValveControl 129;
BA_ "NmJ1939System" BU_ AuxiliaryValveControl 1;
BA_ "NmJ1939IndustryGroup" BU_ AuxiliaryValveControl 2;
BA_ "NmStationAddress" BU_ AuxiliaryValveControl 34;
BA_ "NmJ1939Function" BU_ BodyController 26;
BA_ "NmStationAddress" BU_ BodyController 33;
BA_ "NmJ1939Function" BU_ TractorTrailerBridge1 25;
BA_ "NmStationAddress" BU_ TractorTrailerBridge1 32;
BA_ "NmJ1939Function" BU_ StarterSystem 59;
BA_ "NmStationAddress" BU_ StarterSystem 31;
BA_ "NmJ1939Function" BU_ ElectricalSystem 67;
BA_ "NmStationAddress" BU_ ElectricalSystem 30;
BA_ "NmJ1939Function" BU_ VehicleSecurity 24;
BA_ "NmStationAddress" BU_ VehicleSecurity 29;
BA_ "NmJ1939Function" BU_ VehicleNavigation 23;
BA_ "NmStationAddress" BU_ VehicleNavigation 28;
BA_ "NmJ1939Function" BU_ AerodynamicControl 22;
BA_ "NmStationAddress" BU_ AerodynamicControl 27;
BA_ "NmJ1939Function" BU_ ElectricalChargingSystem 53;
BA_ "NmStationAddress" BU_ ElectricalChargingSystem 26;
BA_ "NmJ1939Function" BU_ ClimateControl1 21;
BA_ "NmStationAddress" BU_ ClimateControl1 25;
BA_ "NmJ1939Function" BU_ TripRecorder 20;
BA_ "NmStationAddress" BU_ TripRecorder 24;
BA_ "NmJ1939Function" BU_ InstrumentCluster 19;
BA_ "NmStationAddress" BU_ InstrumentCluster 23;
BA_ "NmJ1939FunctionInstance" BU_ SuspensionDriveAxle2 1;
BA_ "NmJ1939Function" BU_ SuspensionDriveAxle2 18;
BA_ "NmStationAddress" BU_ SuspensionDriveAxle2 22;
BA_ "NmJ1939Function" BU_ SuspensionDriveAxle1 18;
BA_ "NmStationAddress" BU_ SuspensionDriveAxle1 21;
BA_ "NmJ1939Function" BU_ SuspensionSteerAxle 17;
BA_ "NmStationAddress" BU_ SuspensionSteerAxle 20;
BA_ "NmJ1939Function" BU_ SteeringController 16;
BA_ "NmStationAddress" BU_ SteeringController 19;
BA_ "NmJ1939Function" BU_ FuelSystem 15;
BA_ "NmStationAddress" BU_ FuelSystem 18;
BA_ "NmJ1939Function" BU_ CruiseControl 14;
BA_ "NmStationAddress" BU_ CruiseControl 17;
BA_ "NmJ1939Function" BU_ RetarderDriveline 13;
BA_ "NmStationAddress" BU_ RetarderDriveline 16;
BA_ "NmJ1939Function" BU_ RetarderEngine 12;
BA_ "NmStationAddress" BU_ RetarderEngine 15;
BA_ "NmJ1939FunctionInstance" BU_ BrakesDriveAxle2 1;
BA_ "NmJ1939Function" BU_ BrakesDriveAxle2 11;
BA_ "NmStationAddress" BU_ BrakesDriveAxle2 14;
BA_ "NmJ1939Function" BU_ BrakesDriveAxle1 11;
BA_ "NmStationAddress" BU_ BrakesDriveAxle1 13;
BA_ "NmJ1939Function" BU_ BrakesSystemController 9;
BA_ "NmStationAddress" BU_ BrakesSystemController 11;
BA_ "NmJ1939Function" BU_ BrakesSteerAxle 10;
BA_ "NmStationAddress" BU_ BrakesSteerAxle 12;
BA_ "NmJ1939FunctionInstance" BU_ AxleDrive2 1;
BA_ "NmJ1939Function" BU_ AxleDrive2 8;
BA_ "NmStationAddress" BU_ AxleDrive2 10;
BA_ "NmJ1939Function" BU_ AxleDrive1 8;
BA_ "NmStationAddress" BU_ AxleDrive1 9;
BA_ "NmJ1939Function" BU_ AxleSteering 7;
BA_ "NmStationAddress" BU_ AxleSteering 8;
BA_ "NmJ1939Function" BU_ PowerTakeOff 6;
BA_ "NmStationAddress" BU_ PowerTakeOff 7;
BA_ "NmJ1939FunctionInstance" BU_ ShiftConsoleSecondary 1;
BA_ "NmJ1939Function" BU_ ShiftConsoleSecondary 5;
BA_ "NmStationAddress" BU_ ShiftConsoleSecondary 6;
BA_ "NmJ1939Function" BU_ ShiftConsolePrimary 5;
BA_ "NmStationAddress" BU_ ShiftConsolePrimary 5;
BA_ "NmJ1939FunctionInstance" BU_ Transmission2 1;
BA_ "NmJ1939Function" BU_ Transmission2 3;
BA_ "NmStationAddress" BU_ Transmission2 4;
BA_ "NmJ1939Function" BU_ Transmission1 3;
BA_ "NmStationAddress" BU_ Transmission1 3;
BA_ "NmJ1939FunctionInstance" BU_ Engine2 1;
BA_ "NmStationAddress" BU_ Engine2 1;
BA_ "NmStationAddress" BU_ Engine1 0;
BA_ "GenMsgCycleTime" BO_ 2365313534 1000;
BA_ "GenMsgSendType" BO_ 2365313534 0;
BA_ "GenMsgCycleTime" BO_ 2566639870 5000;
BA_ "GenMsgSendType" BO_ 2566639870 0;
BA_ "GenMsgCycleTime" BO_ 2566638590 10000;
BA_ "GenMsgSendType" BO_ 2566638590 0;
BA_ "GenMsgDelayTime" BO_ 2566638590 1000;
BA_ "GenMsgCycleTime" BO_ 2365311486 1000;
BA_ "GenMsgSendType" BO_ 2365311486 0;
BA_ "GenMsgCycleTime" BO_ 2365311230 1000;
BA_ "GenMsgSendType" BO_ 2365311230 0;
BA_ "GenMsgCycleTime" BO_ 2365310974 1000;
BA_ "GenMsgSendType" BO_ 2365310974 0;
BA_ "GenMsgCycleTime" BO_ 2365310718 1000;
BA_ "GenMsgSendType" BO_ 2365310718 0;
BA_ "GenMsgCycleTime" BO_ 2566637054 5000;
BA_ "GenMsgSendType" BO_ 2566637054 0;
BA_ "GenMsgCycleTime" BO_ 2365309950 1000;
BA_ "GenMsgSendType" BO_ 2365309950 0;
BA_ "GenMsgCycleTime" BO_ 2365309694 1000;
BA_ "GenMsgSendType" BO_ 2365309694 0;
BA_ "GenMsgCycleTime" BO_ 2365309438 1000;
BA_ "GenMsgSendType" BO_ 2365309438 0;
BA_ "GenMsgCycleTime" BO_ 2365309182 1000;
BA_ "GenMsgSendType" BO_ 2365309182 0;
BA_ "GenMsgCycleTime" BO_ 2566635518 5000;
BA_ "GenMsgSendType" BO_ 2566635518 0;
BA_ "GenMsgCycleTime" BO_ 2365308414 1000;
BA_ "GenMsgSendType" BO_ 2365308414 0;
BA_ "GenMsgCycleTime" BO_ 2365308158 1000;
BA_ "GenMsgSendType" BO_ 2365308158 0;
BA_ "GenMsgCycleTime" BO_ 2365307902 1000;
BA_ "GenMsgSendType" BO_ 2365307902 0;
BA_ "GenMsgCycleTime" BO_ 2365307646 1000;
BA_ "GenMsgSendType" BO_ 2365307646 0;
BA_ "GenMsgCycleTime" BO_ 2566633982 5000;
BA_ "GenMsgSendType" BO_ 2566633982 0;
BA_ "GenMsgCycleTime" BO_ 2566633470 100;
BA_ "GenMsgSendType" BO_ 2566633470 0;
BA_ "GenMsgCycleTime" BO_ 2566633214 100;
BA_ "GenMsgSendType" BO_ 2566633214 0;
BA_ "TpJ1939VarDlc" BO_ 2566632702 1;
BA_ "GenMsgCycleTime" BO_ 2566631678 5000;
BA_ "GenMsgSendType" BO_ 2566631678 0;
BA_ "GenMsgCycleTime" BO_ 2365304830 1000;
BA_ "GenMsgSendType" BO_ 2365304830 0;
BA_ "GenMsgCycleTime" BO_ 2365304574 1000;
BA_ "GenMsgSendType" BO_ 2365304574 0;
BA_ "GenMsgCycleTime" BO_ 2566630910 1000;
BA_ "GenMsgSendType" BO_ 2566630910 0;
BA_ "GenMsgCycleTime" BO_ 2566630398 5000;
BA_ "GenMsgSendType" BO_ 2566630398 0;
BA_ "GenMsgCycleTime" BO_ 2365303550 1000;
BA_ "GenMsgSendType" BO_ 2365303550 0;
BA_ "GenMsgCycleTime" BO_ 2365303294 1000;
BA_ "GenMsgSendType" BO_ 2365303294 0;
BA_ "GenMsgCycleTime" BO_ 2566629630 1000;
BA_ "GenMsgSendType" BO_ 2566629630 0;
BA_ "GenMsgCycleTime" BO_ 2566629118 5000;
BA_ "GenMsgSendType" BO_ 2566629118 0;
BA_ "GenMsgCycleTime" BO_ 2365302270 1000;
BA_ "GenMsgSendType" BO_ 2365302270 0;
BA_ "GenMsgCycleTime" BO_ 2365302014 1000;
BA_ "GenMsgSendType" BO_ 2365302014 0;
BA_ "GenMsgCycleTime" BO_ 2566628350 1000;
BA_ "GenMsgSendType" BO_ 2566628350 0;
BA_ "GenMsgCycleTime" BO_ 2566627838 5000;
BA_ "GenMsgSendType" BO_ 2566627838 0;
BA_ "GenMsgCycleTime" BO_ 2365300990 1000;
BA_ "GenMsgSendType" BO_ 2365300990 0;
BA_ "GenMsgCycleTime" BO_ 2365300734 1000;
BA_ "GenMsgSendType" BO_ 2365300734 0;
BA_ "GenMsgCycleTime" BO_ 2566627070 1000;
BA_ "GenMsgSendType" BO_ 2566627070 0;
BA_ "GenMsgCycleTime" BO_ 2566626558 5000;
BA_ "GenMsgSendType" BO_ 2566626558 0;
BA_ "GenMsgCycleTime" BO_ 2365299710 1000;
BA_ "GenMsgSendType" BO_ 2365299710 0;
BA_ "GenMsgCycleTime" BO_ 2365299454 1000;
BA_ "GenMsgSendType" BO_ 2365299454 0;
BA_ "GenMsgCycleTime" BO_ 2566625790 1000;
BA_ "GenMsgSendType" BO_ 2566625790 0;
BA_ "GenMsgCycleTime" BO_ 2566625022 100;
BA_ "GenMsgSendType" BO_ 2566625022 0;
BA_ "GenMsgCycleTime" BO_ 2365297662 100;
BA_ "GenMsgSendType" BO_ 2365297662 0;
BA_ "GenMsgCycleTime" BO_ 2365297406 100;
BA_ "GenMsgSendType" BO_ 2365297406 0;
BA_ "GenMsgCycleTime" BO_ 2365297150 100;
BA_ "GenMsgSendType" BO_ 2365297150 0;
BA_ "GenMsgCycleTime" BO_ 2365296894 100;
BA_ "GenMsgSendType" BO_ 2365296894 0;
BA_ "GenMsgCycleTime" BO_ 2566622462 1000;
BA_ "GenMsgSendType" BO_ 2566622462 0;
BA_ "GenMsgCycleTime" BO_ 2365295358 100;
BA_ "GenMsgSendType" BO_ 2365295358 0;
BA_ "GenMsgCycleTime" BO_ 2566621694 500;
BA_ "GenMsgSendType" BO_ 2566621694 0;
BA_ "GenMsgCycleTime" BO_ 2566621438 1000;
BA_ "GenMsgSendType" BO_ 2566621438 0;
BA_ "GenMsgCycleTime" BO_ 2566620670 1000;
BA_ "GenMsgSendType" BO_ 2566620670 0;
BA_ "GenMsgDelayTime" BO_ 2566620670 100;
BA_ "GenMsgCycleTime" BO_ 2364620286 50;
BA_ "GenMsgSendType" BO_ 2364620286 0;
BA_ "GenMsgDelayTime" BO_ 2364620286 10;
BA_ "GenMsgCycleTime" BO_ 2364620030 100;
BA_ "GenMsgSendType" BO_ 2364620030 0;
BA_ "GenMsgCycleTime" BO_ 2364619774 100;
BA_ "GenMsgSendType" BO_ 2364619774 0;
BA_ "GenMsgCycleTime" BO_ 2364619518 100;
BA_ "GenMsgSendType" BO_ 2364619518 0;
BA_ "GenMsgCycleTime" BO_ 2364619262 100;
BA_ "GenMsgSendType" BO_ 2364619262 0;
BA_ "GenMsgCycleTime" BO_ 2364619006 100;
BA_ "GenMsgSendType" BO_ 2364619006 0;
BA_ "GenMsgCycleTime" BO_ 2364618750 100;
BA_ "GenMsgSendType" BO_ 2364618750 0;
BA_ "GenMsgCycleTime" BO_ 2364618494 100;
BA_ "GenMsgSendType" BO_ 2364618494 0;
BA_ "GenMsgCycleTime" BO_ 2364618238 100;
BA_ "GenMsgSendType" BO_ 2364618238 0;
BA_ "GenMsgCycleTime" BO_ 2364617982 100;
BA_ "GenMsgSendType" BO_ 2364617982 0;
BA_ "GenMsgCycleTime" BO_ 2364617726 100;
BA_ "GenMsgSendType" BO_ 2364617726 0;
BA_ "GenMsgCycleTime" BO_ 2565944062 100;
BA_ "GenMsgSendType" BO_ 2565944062 0;
BA_ "GenMsgCycleTime" BO_ 2364617214 100;
BA_ "GenMsgSendType" BO_ 2364617214 0;
BA_ "GenMsgCycleTime" BO_ 2364616958 100;
BA_ "GenMsgSendType" BO_ 2364616958 0;
BA_ "GenMsgCycleTime" BO_ 2565943294 100;
BA_ "GenMsgSendType" BO_ 2565943294 0;
BA_ "GenMsgCycleTime" BO_ 2565943038 100;
BA_ "GenMsgSendType" BO_ 2565943038 0;
BA_ "SPN" SG_ 3221225472 NumberOfMembersInWorkingSet 2409;
BA_ "SigType" SG_ 3221225472 NumberOfMembersInWorkingSet 3;
BA_ "SPN" SG_ 3221225472 SourceAddress 5600;
BA_ "SPN" SG_ 3221225472 NncntnuslyMonitoredSystemsStatus 1223;
BA_ "SPN" SG_ 3221225472 NncntnslyMonitoredSystemsSupport 1222;
BA_ "SPN" SG_ 3221225472 CntnslyMntrdSystmsSupport_Status 1221;
BA_ "SPN" SG_ 3221225472 AETCTorqueValue 3561;
BA_ "SigType" SG_ 3221225472 AETCTorqueValue 1;
BA_ "SPN" SG_ 3221225472 TrailerWeight 180;
BA_ "SigType" SG_ 3221225472 TrailerWeight 1;
BA_ "SPN" SG_ 3221225472 ReferenceTirePressSetting 3193;
BA_ "SPN" SG_ 3221225472 ReferenceTirePress 3191;
BA_ "SPN" SG_ 3221225472 TirePressThresholdDetection 2587;
BA_ "SPN" SG_ 3221225472 TireAirLeakageRate 2586;
BA_ "SigType" SG_ 3221225472 TireAirLeakageRate 1;
BA_ "SPN" SG_ 3221225472 CTIWheelEndElectricalFault 1697;
BA_ "SigType" SG_ 3221225472 CTIWheelEndElectricalFault 4;
BA_ "SPN" SG_ 3221225472 CTITireStatus 1698;
BA_ "SigType" SG_ 3221225472 CTITireStatus 4;
BA_ "SPN" SG_ 3221225472 CTIWheelSensorStatus 1699;
BA_ "SigType" SG_ 3221225472 CTIWheelSensorStatus 4;
BA_ "SPN" SG_ 3221225472 TireTemp 242;
BA_ "SigType" SG_ 3221225472 TireTemp 1;
BA_ "SPN" SG_ 3221225472 TirePress 241;
BA_ "SigType" SG_ 3221225472 TirePress 1;
BA_ "SPN" SG_ 3221225472 EngTurningGearEngaged 1206;
BA_ "SigType" SG_ 3221225472 EngTurningGearEngaged 4;
BA_ "SPN" SG_ 3221225472 AETCSpeedValue 3560;
BA_ "SigType" SG_ 3221225472 AETCSpeedValue 1;
BA_ "SPN" SG_ 2365313534 SLIBatTempMaxLmtReq 8819;
BA_ "SigType" SG_ 2365313534 SLIBatTempMaxLmtReq 1;
BA_ "SPN" SG_ 2365313534 SLIBatTermChargeCurMaxLmtReq 8818;
BA_ "SigType" SG_ 2365313534 SLIBatTermChargeCurMaxLmtReq 1;
BA_ "SPN" SG_ 2365313534 SLIBatTermVMaxLmtReq 8817;
BA_ "SigType" SG_ 2365313534 SLIBatTermVMaxLmtReq 1;
BA_ "SPN" SG_ 2566639870 OneLowSideVBuckDefaultSetting 9519;
BA_ "SigType" SG_ 2566639870 OneLowSideVBuckDefaultSetting 1;
BA_ "SPN" SG_ 2566639870 SLIBatTempMaxLmtSetting 8832;
BA_ "SigType" SG_ 2566639870 SLIBatTempMaxLmtSetting 1;
BA_ "SPN" SG_ 2566639870 SLIBatTermChargeCurMaxLmtSetting 8831;
BA_ "SigType" SG_ 2566639870 SLIBatTermChargeCurMaxLmtSetting 1;
BA_ "SPN" SG_ 2566639870 SLIBatTermVMaxLmtSetting 8830;
BA_ "SigType" SG_ 2566639870 SLIBatTermVMaxLmtSetting 1;
BA_ "SPN" SG_ 2566639870 OneLowSideCurMaxLmtSetting 8829;
BA_ "SigType" SG_ 2566639870 OneLowSideCurMaxLmtSetting 1;
BA_ "SPN" SG_ 2566639870 OneLowSideVMaxLmtSetting 8828;
BA_ "SigType" SG_ 2566639870 OneLowSideVMaxLmtSetting 1;
BA_ "SPN" SG_ 2566639870 OneLowSideVMinLmtSetting 8827;
BA_ "SigType" SG_ 2566639870 OneLowSideVMinLmtSetting 1;
BA_ "SPN" SG_ 2566639870 OneHiSideCurMaxLmtSetting 8826;
BA_ "SigType" SG_ 2566639870 OneHiSideCurMaxLmtSetting 1;
BA_ "SPN" SG_ 2566639870 OneHiSideVMaxLmtSetting 8825;
BA_ "SigType" SG_ 2566639870 OneHiSideVMaxLmtSetting 1;
BA_ "SPN" SG_ 2566639870 OneHiSideVMinLmtSetting 8824;
BA_ "SigType" SG_ 2566639870 OneHiSideVMinLmtSetting 1;
BA_ "SPN" SG_ 2566639614 OneTotalLowSideCharge 8836;
BA_ "SigType" SG_ 2566639614 OneTotalLowSideCharge 1;
BA_ "SPN" SG_ 2566639614 OneTotalHiSideCharge 8835;
BA_ "SigType" SG_ 2566639614 OneTotalHiSideCharge 1;
BA_ "SPN" SG_ 2566639614 OneTotalLowSideEnergy 8834;
BA_ "SigType" SG_ 2566639614 OneTotalLowSideEnergy 1;
BA_ "SPN" SG_ 2566639614 OneTotalHiSideEnergy 8833;
BA_ "SigType" SG_ 2566639614 OneTotalHiSideEnergy 1;
BA_ "SPN" SG_ 2633748222 SPNModifiedStatus 8847;
BA_ "SigType" SG_ 2633748222 SPNModifiedStatus 5;
BA_ "SPN" SG_ 2633748222 SPNSA 8846;
BA_ "SPN" SG_ 2633748222 SPNDetailedStatus 8848;
BA_ "SPN" SG_ 2633748222 SPN 8845;
BA_ "SPN" SG_ 2633748222 PortCmdStatus 8844;
BA_ "SPN" SG_ 2633748222 PortPendingChangesStatus 8843;
BA_ "SPN" SG_ 2633748222 Port 8842;
BA_ "SPN" SG_ 2566639102 PlungerFiringOrderSetting 8881;
BA_ "SPN" SG_ 2566639102 RodLoadHiThreshold 8880;
BA_ "SigType" SG_ 2566639102 RodLoadHiThreshold 1;
BA_ "SPN" SG_ 2566639102 CrankshaftSpdHiThreshold 8879;
BA_ "SigType" SG_ 2566639102 CrankshaftSpdHiThreshold 1;
BA_ "SPN" SG_ 2566639102 CrankshaftSpdLowThreshold 8878;
BA_ "SigType" SG_ 2566639102 CrankshaftSpdLowThreshold 1;
BA_ "SPN" SG_ 2566639102 DisPressHiThreshold 8877;
BA_ "SigType" SG_ 2566639102 DisPressHiThreshold 1;
BA_ "SPN" SG_ 2566639102 SuctionPressHiThreshold 8876;
BA_ "SigType" SG_ 2566639102 SuctionPressHiThreshold 1;
BA_ "SPN" SG_ 2566639102 SuctionPressLowThreshold 8875;
BA_ "SigType" SG_ 2566639102 SuctionPressLowThreshold 1;
BA_ "SPN" SG_ 2566639102 GearBoxOilTempHiThreshold 8874;
BA_ "SigType" SG_ 2566639102 GearBoxOilTempHiThreshold 1;
BA_ "SPN" SG_ 2566639102 GearBoxOilTempLowThreshold 8873;
BA_ "SigType" SG_ 2566639102 GearBoxOilTempLowThreshold 1;
BA_ "SPN" SG_ 2566639102 GearBoxOilPressHiThreshold 8872;
BA_ "SigType" SG_ 2566639102 GearBoxOilPressHiThreshold 1;
BA_ "SPN" SG_ 2566639102 GearBoxOilPressLowThreshold 8871;
BA_ "SigType" SG_ 2566639102 GearBoxOilPressLowThreshold 1;
BA_ "SPN" SG_ 2566638846 VlvSeatOpHours 8885;
BA_ "SigType" SG_ 2566638846 VlvSeatOpHours 1;
BA_ "SPN" SG_ 2566638846 PackingOpHours 8884;
BA_ "SigType" SG_ 2566638846 PackingOpHours 1;
BA_ "SPN" SG_ 2566638846 VlvOpHours 8883;
BA_ "SigType" SG_ 2566638846 VlvOpHours 1;
BA_ "SPN" SG_ 2566638846 MaintenanceIntervalHours 8882;
BA_ "SigType" SG_ 2566638846 MaintenanceIntervalHours 1;
BA_ "SPN" SG_ 2566638590 DiagCount 8888;
BA_ "SigType" SG_ 2566638590 DiagCount 1;
BA_ "SPN" SG_ 2566638590 DiagTime 8887;
BA_ "SigType" SG_ 2566638590 DiagTime 1;
BA_ "SPN" SG_ 2365311486 TwoHiSideCurMaxLmtReq 8946;
BA_ "SigType" SG_ 2365311486 TwoHiSideCurMaxLmtReq 1;
BA_ "SPN" SG_ 2365311486 TwoHiSideVMaxLmtReq 8945;
BA_ "SigType" SG_ 2365311486 TwoHiSideVMaxLmtReq 1;
BA_ "SPN" SG_ 2365311486 TwoHiSideVMinLmtReq 8944;
BA_ "SigType" SG_ 2365311486 TwoHiSideVMinLmtReq 1;
BA_ "SPN" SG_ 2365311230 TwoLowSideCurMaxLmtReq 8943;
BA_ "SigType" SG_ 2365311230 TwoLowSideCurMaxLmtReq 1;
BA_ "SPN" SG_ 2365311230 TwoLowSideVMaxLmtReq 8942;
BA_ "SigType" SG_ 2365311230 TwoLowSideVMaxLmtReq 1;
BA_ "SPN" SG_ 2365311230 TwoLowSideVMinLmtReq 8941;
BA_ "SigType" SG_ 2365311230 TwoLowSideVMinLmtReq 1;
BA_ "SPN" SG_ 2365310974 TwoCoolantOutTemp 8940;
BA_ "SigType" SG_ 2365310974 TwoCoolantOutTemp 1;
BA_ "SPN" SG_ 2365310974 TwoCoolantInTemp 8939;
BA_ "SigType" SG_ 2365310974 TwoCoolantInTemp 1;
BA_ "SPN" SG_ 2365310974 TwoPwrETemp 8938;
BA_ "SigType" SG_ 2365310974 TwoPwrETemp 1;
BA_ "SPN" SG_ 2365310974 TwoConvEFilterTemp 8937;
BA_ "SigType" SG_ 2365310974 TwoConvEFilterTemp 1;
BA_ "SPN" SG_ 2365310974 TwoConvTemp 8936;
BA_ "SigType" SG_ 2365310974 TwoConvTemp 1;
BA_ "SPN" SG_ 2365310718 SLIBatTempMaxLmtReq 8935;
BA_ "SigType" SG_ 2365310718 SLIBatTempMaxLmtReq 1;
BA_ "SPN" SG_ 2365310718 SLIBatTermChargeCurMaxLmtReq 8934;
BA_ "SigType" SG_ 2365310718 SLIBatTermChargeCurMaxLmtReq 1;
BA_ "SPN" SG_ 2365310718 SLIBatTermVMaxLmtReq 8933;
BA_ "SigType" SG_ 2365310718 SLIBatTermVMaxLmtReq 1;
BA_ "SPN" SG_ 2566637054 TwoLowSideVBuckDefaultSetting 9520;
BA_ "SigType" SG_ 2566637054 TwoLowSideVBuckDefaultSetting 1;
BA_ "SPN" SG_ 2566637054 SLIBatTempMaxLmtSetting 8932;
BA_ "SigType" SG_ 2566637054 SLIBatTempMaxLmtSetting 1;
BA_ "SPN" SG_ 2566637054 SLIBatTermChargeCurMaxLmtSetting 8931;
BA_ "SigType" SG_ 2566637054 SLIBatTermChargeCurMaxLmtSetting 1;
BA_ "SPN" SG_ 2566637054 SLIBatTermVMaxLmtSetting 8930;
BA_ "SigType" SG_ 2566637054 SLIBatTermVMaxLmtSetting 1;
BA_ "SPN" SG_ 2566637054 TwoLowSideCurMaxLmtSetting 8929;
BA_ "SigType" SG_ 2566637054 TwoLowSideCurMaxLmtSetting 1;
BA_ "SPN" SG_ 2566637054 TwoLowSideVMaxLmtSetting 8928;
BA_ "SigType" SG_ 2566637054 TwoLowSideVMaxLmtSetting 1;
BA_ "SPN" SG_ 2566637054 TwoLowSideVMinLmtSetting 8927;
BA_ "SigType" SG_ 2566637054 TwoLowSideVMinLmtSetting 1;
BA_ "SPN" SG_ 2566637054 TwoHiSideCurMaxLmtSetting 8926;
BA_ "SigType" SG_ 2566637054 TwoHiSideCurMaxLmtSetting 1;
BA_ "SPN" SG_ 2566637054 TwoHiSideVMaxLmtSetting 8925;
BA_ "SigType" SG_ 2566637054 TwoHiSideVMaxLmtSetting 1;
BA_ "SPN" SG_ 2566637054 TwoHiSideVMinLmtSetting 8924;
BA_ "SigType" SG_ 2566637054 TwoHiSideVMinLmtSetting 1;
BA_ "SPN" SG_ 2566636798 TwoTotalLowSideCharge 8923;
BA_ "SigType" SG_ 2566636798 TwoTotalLowSideCharge 1;
BA_ "SPN" SG_ 2566636798 TwoTotalHiSideCharge 8922;
BA_ "SigType" SG_ 2566636798 TwoTotalHiSideCharge 1;
BA_ "SPN" SG_ 2566636798 TwoTotalLowSideEnergy 8921;
BA_ "SigType" SG_ 2566636798 TwoTotalLowSideEnergy 1;
BA_ "SPN" SG_ 2566636798 TwoTotalHiSideEnergy 8920;
BA_ "SigType" SG_ 2566636798 TwoTotalHiSideEnergy 1;
BA_ "SPN" SG_ 2365309950 ThreeHiSideCurMaxLmtReq 9001;
BA_ "SigType" SG_ 2365309950 ThreeHiSideCurMaxLmtReq 1;
BA_ "SPN" SG_ 2365309950 ThreeHiSideVMaxLmtReq 9000;
BA_ "SigType" SG_ 2365309950 ThreeHiSideVMaxLmtReq 1;
BA_ "SPN" SG_ 2365309950 ThreeHiSideVMinLmtReq 8999;
BA_ "SigType" SG_ 2365309950 ThreeHiSideVMinLmtReq 1;
BA_ "SPN" SG_ 2365309694 ThreeLowSideCurMaxLmtReq 8998;
BA_ "SigType" SG_ 2365309694 ThreeLowSideCurMaxLmtReq 1;
BA_ "SPN" SG_ 2365309694 ThreeLowSideVMaxLmtReq 8997;
BA_ "SigType" SG_ 2365309694 ThreeLowSideVMaxLmtReq 1;
BA_ "SPN" SG_ 2365309694 ThreeLowSideVMinLmtReq 8996;
BA_ "SigType" SG_ 2365309694 ThreeLowSideVMinLmtReq 1;
BA_ "SPN" SG_ 2365309438 ThreeCoolantOutTemp 8995;
BA_ "SigType" SG_ 2365309438 ThreeCoolantOutTemp 1;
BA_ "SPN" SG_ 2365309438 ThreeCoolantInTemp 8994;
BA_ "SigType" SG_ 2365309438 ThreeCoolantInTemp 1;
BA_ "SPN" SG_ 2365309438 ThreePwrETemp 8993;
BA_ "SigType" SG_ 2365309438 ThreePwrETemp 1;
BA_ "SPN" SG_ 2365309438 ThreeConvEFilterTemp 8992;
BA_ "SigType" SG_ 2365309438 ThreeConvEFilterTemp 1;
BA_ "SPN" SG_ 2365309438 ThreeConvTemp 8991;
BA_ "SigType" SG_ 2365309438 ThreeConvTemp 1;
BA_ "SPN" SG_ 2365309182 SLIBatTempMaxLmtReq 8990;
BA_ "SigType" SG_ 2365309182 SLIBatTempMaxLmtReq 1;
BA_ "SPN" SG_ 2365309182 SLIBatTermChargeCurMaxLmtReq 8989;
BA_ "SigType" SG_ 2365309182 SLIBatTermChargeCurMaxLmtReq 1;
BA_ "SPN" SG_ 2365309182 SLIBatTermVMaxLmtReq 8988;
BA_ "SigType" SG_ 2365309182 SLIBatTermVMaxLmtReq 1;
BA_ "SPN" SG_ 2566635518 ThreeLowSideVBuckDefaultSetting 9521;
BA_ "SigType" SG_ 2566635518 ThreeLowSideVBuckDefaultSetting 1;
BA_ "SPN" SG_ 2566635518 SLIBatTempMaxLmtSetting 8987;
BA_ "SigType" SG_ 2566635518 SLIBatTempMaxLmtSetting 1;
BA_ "SPN" SG_ 2566635518 SLIBatTermChargeCurMaxLmtSetting 8986;
BA_ "SigType" SG_ 2566635518 SLIBatTermChargeCurMaxLmtSetting 1;
BA_ "SPN" SG_ 2566635518 SLIBatTermVMaxLmtSetting 8985;
BA_ "SigType" SG_ 2566635518 SLIBatTermVMaxLmtSetting 1;
BA_ "SPN" SG_ 2566635518 ThreeLowSideCurMaxLmtSetting 8984;
BA_ "SigType" SG_ 2566635518 ThreeLowSideCurMaxLmtSetting 1;
BA_ "SPN" SG_ 2566635518 ThreeLowSideVMaxLmtSetting 8983;
BA_ "SigType" SG_ 2566635518 ThreeLowSideVMaxLmtSetting 1;
BA_ "SPN" SG_ 2566635518 ThreeLowSideVMinLmtSetting 8982;
BA_ "SigType" SG_ 2566635518 ThreeLowSideVMinLmtSetting 1;
BA_ "SPN" SG_ 2566635518 ThreeHiSideCurMaxLmtSetting 8981;
BA_ "SigType" SG_ 2566635518 ThreeHiSideCurMaxLmtSetting 1;
BA_ "SPN" SG_ 2566635518 ThreeHiSideVMaxLmtSetting 8980;
BA_ "SigType" SG_ 2566635518 ThreeHiSideVMaxLmtSetting 1;
BA_ "SPN" SG_ 2566635518 ThreeHiSideVMinLmtSetting 8979;
BA_ "SigType" SG_ 2566635518 ThreeHiSideVMinLmtSetting 1;
BA_ "SPN" SG_ 2566635262 ThreeTotalLowSideCharge 8978;
BA_ "SigType" SG_ 2566635262 ThreeTotalLowSideCharge 1;
BA_ "SPN" SG_ 2566635262 ThreeTotalHiSideCharge 8977;
BA_ "SigType" SG_ 2566635262 ThreeTotalHiSideCharge 1;
BA_ "SPN" SG_ 2566635262 ThreeTotalLowSideEnergy 8976;
BA_ "SigType" SG_ 2566635262 ThreeTotalLowSideEnergy 1;
BA_ "SPN" SG_ 2566635262 ThreeTotalHiSideEnergy 8975;
BA_ "SigType" SG_ 2566635262 ThreeTotalHiSideEnergy 1;
BA_ "SPN" SG_ 2365308414 FourHiSideCurMaxLmtReq 9056;
BA_ "SigType" SG_ 2365308414 FourHiSideCurMaxLmtReq 1;
BA_ "SPN" SG_ 2365308414 FourHiSideVMaxLmtReq 9055;
BA_ "SigType" SG_ 2365308414 FourHiSideVMaxLmtReq 1;
BA_ "SPN" SG_ 2365308414 FourHiSideVMinLmtReq 9054;
BA_ "SigType" SG_ 2365308414 FourHiSideVMinLmtReq 1;
BA_ "SPN" SG_ 2365308158 FourLowSideCurMaxLmtReq 9053;
BA_ "SigType" SG_ 2365308158 FourLowSideCurMaxLmtReq 1;
BA_ "SPN" SG_ 2365308158 FourLowSideVMaxLmtReq 9052;
BA_ "SigType" SG_ 2365308158 FourLowSideVMaxLmtReq 1;
BA_ "SPN" SG_ 2365308158 FourLowSideVMinLmtReq 9051;
BA_ "SigType" SG_ 2365308158 FourLowSideVMinLmtReq 1;
BA_ "SPN" SG_ 2365307902 FourCoolantOutTemp 9050;
BA_ "SigType" SG_ 2365307902 FourCoolantOutTemp 1;
BA_ "SPN" SG_ 2365307902 FourCoolantInTemp 9049;
BA_ "SigType" SG_ 2365307902 FourCoolantInTemp 1;
BA_ "SPN" SG_ 2365307902 FourPwrETemp 9048;
BA_ "SigType" SG_ 2365307902 FourPwrETemp 1;
BA_ "SPN" SG_ 2365307902 FourConvEFilterTemp 9047;
BA_ "SigType" SG_ 2365307902 FourConvEFilterTemp 1;
BA_ "SPN" SG_ 2365307902 FourConvTemp 9046;
BA_ "SigType" SG_ 2365307902 FourConvTemp 1;
BA_ "SPN" SG_ 2365307646 SLIBatTempMaxLmtReq 9045;
BA_ "SigType" SG_ 2365307646 SLIBatTempMaxLmtReq 1;
BA_ "SPN" SG_ 2365307646 SLIBatTermChargeCurMaxLmtReq 9044;
BA_ "SigType" SG_ 2365307646 SLIBatTermChargeCurMaxLmtReq 1;
BA_ "SPN" SG_ 2365307646 SLIBatTermVMaxLmtReq 9043;
BA_ "SigType" SG_ 2365307646 SLIBatTermVMaxLmtReq 1;
BA_ "SPN" SG_ 2566633982 FourLowSideVBuckDefaultSetting 9522;
BA_ "SigType" SG_ 2566633982 FourLowSideVBuckDefaultSetting 1;
BA_ "SPN" SG_ 2566633982 SLIBatTempMaxLmtSetting 9042;
BA_ "SigType" SG_ 2566633982 SLIBatTempMaxLmtSetting 1;
BA_ "SPN" SG_ 2566633982 SLIBatTermChargeCurMaxLmtSetting 9041;
BA_ "SigType" SG_ 2566633982 SLIBatTermChargeCurMaxLmtSetting 1;
BA_ "SPN" SG_ 2566633982 SLIBatTermVMaxLmtSetting 9040;
BA_ "SigType" SG_ 2566633982 SLIBatTermVMaxLmtSetting 1;
BA_ "SPN" SG_ 2566633982 FourLowSideCurMaxLmtSetting 9039;
BA_ "SigType" SG_ 2566633982 FourLowSideCurMaxLmtSetting 1;
BA_ "SPN" SG_ 2566633982 FourLowSideVMaxLmtSetting 9038;
BA_ "SigType" SG_ 2566633982 FourLowSideVMaxLmtSetting 1;
BA_ "SPN" SG_ 2566633982 FourLowSideVMinLmtSetting 9037;
BA_ "SigType" SG_ 2566633982 FourLowSideVMinLmtSetting 1;
BA_ "SPN" SG_ 2566633982 FourHiSideCurMaxLmtSetting 9036;
BA_ "SigType" SG_ 2566633982 FourHiSideCurMaxLmtSetting 1;
BA_ "SPN" SG_ 2566633982 FourHiSideVMaxLmtSetting 9035;
BA_ "SigType" SG_ 2566633982 FourHiSideVMaxLmtSetting 1;
BA_ "SPN" SG_ 2566633982 FourHiSideVMinLmtSetting 9034;
BA_ "SigType" SG_ 2566633982 FourHiSideVMinLmtSetting 1;
BA_ "SPN" SG_ 2566633726 FourTotalLowSideCharge 9033;
BA_ "SigType" SG_ 2566633726 FourTotalLowSideCharge 1;
BA_ "SPN" SG_ 2566633726 FourTotalHiSideCharge 9032;
BA_ "SigType" SG_ 2566633726 FourTotalHiSideCharge 1;
BA_ "SPN" SG_ 2566633726 FourTotalLowSideEnergy 9031;
BA_ "SigType" SG_ 2566633726 FourTotalLowSideEnergy 1;
BA_ "SPN" SG_ 2566633726 FourTotalHiSideEnergy 9030;
BA_ "SigType" SG_ 2566633726 FourTotalHiSideEnergy 1;
BA_ "SPN" SG_ 2566633470 O2PumpingCur 9177;
BA_ "SigType" SG_ 2566633470 O2PumpingCur 1;
BA_ "SPN" SG_ 2566633214 O2PumpingCur 9178;
BA_ "SigType" SG_ 2566633214 O2PumpingCur 1;
BA_ "SPN" SG_ 2566632958 PwrEndTripHours 9188;
BA_ "SigType" SG_ 2566632958 PwrEndTripHours 1;
BA_ "SPN" SG_ 2566632958 FluidEndTripHours 9187;
BA_ "SigType" SG_ 2566632958 FluidEndTripHours 1;
BA_ "SPN" SG_ 2566632702 FluidEndSerialNum 9190;
BA_ "SigType" SG_ 2566632702 FluidEndSerialNum 8;
BA_ "SPN" SG_ 2566632702 PwrEndSerialNum 9189;
BA_ "SigType" SG_ 2566632702 PwrEndSerialNum 8;
BA_ "SPN" SG_ 2566632446 TripFluidPumped 9192;
BA_ "SigType" SG_ 2566632446 TripFluidPumped 1;
BA_ "SPN" SG_ 2566632446 TotalFluidPumped 9191;
BA_ "SigType" SG_ 2566632446 TotalFluidPumped 1;
BA_ "SPN" SG_ 2566632190 DisPressCalSetPointStatus 9196;
BA_ "SigType" SG_ 2566632190 DisPressCalSetPointStatus 4;
BA_ "SPN" SG_ 2566632190 DisPressCalSetPoint 9195;
BA_ "SPN" SG_ 2566632190 SuctionPressCalSetPointStatus 9194;
BA_ "SigType" SG_ 2566632190 SuctionPressCalSetPointStatus 4;
BA_ "SPN" SG_ 2566632190 SuctionPressCalSetPoint 9193;
BA_ "SPN" SG_ 2566631934 TotalDCInputEnergy 9366;
BA_ "SigType" SG_ 2566631934 TotalDCInputEnergy 1;
BA_ "SPN" SG_ 2566631934 TotalDCInputCharge 9365;
BA_ "SigType" SG_ 2566631934 TotalDCInputCharge 1;
BA_ "SPN" SG_ 2566631678 ACSideDefaultFreqCmdSetting 9557;
BA_ "SigType" SG_ 2566631678 ACSideDefaultFreqCmdSetting 1;
BA_ "SPN" SG_ 2566631678 DCSideCurMinLmtSetting 9556;
BA_ "SigType" SG_ 2566631678 DCSideCurMinLmtSetting 1;
BA_ "SPN" SG_ 2566631678 DCSideVMaxLmtSetting 9555;
BA_ "SigType" SG_ 2566631678 DCSideVMaxLmtSetting 1;
BA_ "SPN" SG_ 2566631678 ACSideRMSCurMaxLmtSetting 9364;
BA_ "SigType" SG_ 2566631678 ACSideRMSCurMaxLmtSetting 1;
BA_ "SPN" SG_ 2566631678 ACSideRMSVMaxLmtSetting 9363;
BA_ "SigType" SG_ 2566631678 ACSideRMSVMaxLmtSetting 1;
BA_ "SPN" SG_ 2566631678 DCSideCurMaxLmtSetting 9362;
BA_ "SigType" SG_ 2566631678 DCSideCurMaxLmtSetting 1;
BA_ "SPN" SG_ 2566631678 DCSideVMinLmtSetting 9361;
BA_ "SigType" SG_ 2566631678 DCSideVMinLmtSetting 1;
BA_ "SPN" SG_ 2365304830 DefaultFreqReq 9527;
BA_ "SigType" SG_ 2365304830 DefaultFreqReq 1;
BA_ "SPN" SG_ 2365304830 RMSCurMaxLmtReq 9360;
BA_ "SigType" SG_ 2365304830 RMSCurMaxLmtReq 1;
BA_ "SPN" SG_ 2365304830 RMSVMaxLmtReq 9359;
BA_ "SigType" SG_ 2365304830 RMSVMaxLmtReq 1;
BA_ "SPN" SG_ 2365304574 CurMinLmtReq 9554;
BA_ "SigType" SG_ 2365304574 CurMinLmtReq 1;
BA_ "SPN" SG_ 2365304574 VMaxLmtReq 9553;
BA_ "SigType" SG_ 2365304574 VMaxLmtReq 1;
BA_ "SPN" SG_ 2365304574 CurMaxLmtReq 9358;
BA_ "SigType" SG_ 2365304574 CurMaxLmtReq 1;
BA_ "SPN" SG_ 2365304574 VMinLmtReq 9357;
BA_ "SigType" SG_ 2365304574 VMinLmtReq 1;
BA_ "SPN" SG_ 2566630910 CoolantOutTemp 9341;
BA_ "SigType" SG_ 2566630910 CoolantOutTemp 1;
BA_ "SPN" SG_ 2566630910 CoolantInTemp 9340;
BA_ "SigType" SG_ 2566630910 CoolantInTemp 1;
BA_ "SPN" SG_ 2566630910 PwrETemp 9339;
BA_ "SigType" SG_ 2566630910 PwrETemp 1;
BA_ "SPN" SG_ 2566630910 InverterEFilterTemp 9338;
BA_ "SigType" SG_ 2566630910 InverterEFilterTemp 1;
BA_ "SPN" SG_ 2566630910 CtrlTemp 9337;
BA_ "SigType" SG_ 2566630910 CtrlTemp 1;
BA_ "SPN" SG_ 2566630654 TotalDCInputEnergy 9320;
BA_ "SigType" SG_ 2566630654 TotalDCInputEnergy 1;
BA_ "SPN" SG_ 2566630654 TotalDCInputCharge 9319;
BA_ "SigType" SG_ 2566630654 TotalDCInputCharge 1;
BA_ "SPN" SG_ 2566630398 ACSideDefaultFreqCmdSetting 9551;
BA_ "SigType" SG_ 2566630398 ACSideDefaultFreqCmdSetting 1;
BA_ "SPN" SG_ 2566630398 DCSideCurMinLmtSetting 9550;
BA_ "SigType" SG_ 2566630398 DCSideCurMinLmtSetting 1;
BA_ "SPN" SG_ 2566630398 DCSideVMaxLmtSetting 9549;
BA_ "SigType" SG_ 2566630398 DCSideVMaxLmtSetting 1;
BA_ "SPN" SG_ 2566630398 ACSideRMSCurMaxLmtSetting 9318;
BA_ "SigType" SG_ 2566630398 ACSideRMSCurMaxLmtSetting 1;
BA_ "SPN" SG_ 2566630398 ACSideRMSVMaxLmtSetting 9317;
BA_ "SigType" SG_ 2566630398 ACSideRMSVMaxLmtSetting 1;
BA_ "SPN" SG_ 2566630398 DCSideCurMaxLmtSetting 9316;
BA_ "SigType" SG_ 2566630398 DCSideCurMaxLmtSetting 1;
BA_ "SPN" SG_ 2566630398 DCSideVMinLmtSetting 9315;
BA_ "SigType" SG_ 2566630398 DCSideVMinLmtSetting 1;
BA_ "SPN" SG_ 2365303550 DefaultFreqReq 9526;
BA_ "SigType" SG_ 2365303550 DefaultFreqReq 1;
BA_ "SPN" SG_ 2365303550 RMSCurMaxLmtReq 9314;
BA_ "SigType" SG_ 2365303550 RMSCurMaxLmtReq 1;
BA_ "SPN" SG_ 2365303550 RMSVMaxLmtReq 9313;
BA_ "SigType" SG_ 2365303550 RMSVMaxLmtReq 1;
BA_ "SPN" SG_ 2365303294 CurMinLmtReq 9548;
BA_ "SigType" SG_ 2365303294 CurMinLmtReq 1;
BA_ "SPN" SG_ 2365303294 VMaxLmtReq 9547;
BA_ "SigType" SG_ 2365303294 VMaxLmtReq 1;
BA_ "SPN" SG_ 2365303294 CurMaxLmtReq 9312;
BA_ "SigType" SG_ 2365303294 CurMaxLmtReq 1;
BA_ "SPN" SG_ 2365303294 VMinLmtReq 9311;
BA_ "SigType" SG_ 2365303294 VMinLmtReq 1;
BA_ "SPN" SG_ 2566629630 CoolantOutTemp 9295;
BA_ "SigType" SG_ 2566629630 CoolantOutTemp 1;
BA_ "SPN" SG_ 2566629630 CoolantInTemp 9294;
BA_ "SigType" SG_ 2566629630 CoolantInTemp 1;
BA_ "SPN" SG_ 2566629630 PwrETemp 9293;
BA_ "SigType" SG_ 2566629630 PwrETemp 1;
BA_ "SPN" SG_ 2566629630 InverterEFilterTemp 9292;
BA_ "SigType" SG_ 2566629630 InverterEFilterTemp 1;
BA_ "SPN" SG_ 2566629630 CtrlTemp 9291;
BA_ "SigType" SG_ 2566629630 CtrlTemp 1;
BA_ "SPN" SG_ 2566629374 TotalDCInputEnergy 9290;
BA_ "SigType" SG_ 2566629374 TotalDCInputEnergy 1;
BA_ "SPN" SG_ 2566629374 TotalDCInputCharge 9289;
BA_ "SigType" SG_ 2566629374 TotalDCInputCharge 1;
BA_ "SPN" SG_ 2566629118 ACSideDefaultFreqCmdSetting 9545;
BA_ "SigType" SG_ 2566629118 ACSideDefaultFreqCmdSetting 1;
BA_ "SPN" SG_ 2566629118 DCSideCurMinLmtSetting 9544;
BA_ "SigType" SG_ 2566629118 DCSideCurMinLmtSetting 1;
BA_ "SPN" SG_ 2566629118 DCSideVMaxLmtSetting 9543;
BA_ "SigType" SG_ 2566629118 DCSideVMaxLmtSetting 1;
BA_ "SPN" SG_ 2566629118 ACSideRMSCurMaxLmtSetting 9288;
BA_ "SigType" SG_ 2566629118 ACSideRMSCurMaxLmtSetting 1;
BA_ "SPN" SG_ 2566629118 ACSideRMSVMaxLmtSetting 9287;
BA_ "SigType" SG_ 2566629118 ACSideRMSVMaxLmtSetting 1;
BA_ "SPN" SG_ 2566629118 DCSideCurMaxLmtSetting 9286;
BA_ "SigType" SG_ 2566629118 DCSideCurMaxLmtSetting 1;
BA_ "SPN" SG_ 2566629118 DCSideVMinLmtSetting 9285;
BA_ "SigType" SG_ 2566629118 DCSideVMinLmtSetting 1;
BA_ "SPN" SG_ 2365302270 DefaultFreqReq 9525;
BA_ "SigType" SG_ 2365302270 DefaultFreqReq 1;
BA_ "SPN" SG_ 2365302270 RMSCurMaxLmtReq 9284;
BA_ "SigType" SG_ 2365302270 RMSCurMaxLmtReq 1;
BA_ "SPN" SG_ 2365302270 RMSVMaxLmtReq 9283;
BA_ "SigType" SG_ 2365302270 RMSVMaxLmtReq 1;
BA_ "SPN" SG_ 2365302014 CurMinLmtReq 9542;
BA_ "SigType" SG_ 2365302014 CurMinLmtReq 1;
BA_ "SPN" SG_ 2365302014 VMaxLmtReq 9541;
BA_ "SigType" SG_ 2365302014 VMaxLmtReq 1;
BA_ "SPN" SG_ 2365302014 CurMaxLmtReq 9282;
BA_ "SigType" SG_ 2365302014 CurMaxLmtReq 1;
BA_ "SPN" SG_ 2365302014 VMinLmtReq 9281;
BA_ "SigType" SG_ 2365302014 VMinLmtReq 1;
BA_ "SPN" SG_ 2566628350 CoolantOutTemp 9265;
BA_ "SigType" SG_ 2566628350 CoolantOutTemp 1;
BA_ "SPN" SG_ 2566628350 CoolantInTemp 9264;
BA_ "SigType" SG_ 2566628350 CoolantInTemp 1;
BA_ "SPN" SG_ 2566628350 PwrETemp 9263;
BA_ "SigType" SG_ 2566628350 PwrETemp 1;
BA_ "SPN" SG_ 2566628350 InverterEFilterTemp 9262;
BA_ "SigType" SG_ 2566628350 InverterEFilterTemp 1;
BA_ "SPN" SG_ 2566628350 CtrlTemp 9261;
BA_ "SigType" SG_ 2566628350 CtrlTemp 1;
BA_ "SPN" SG_ 2566628094 TotalDCInputEnergy 9260;
BA_ "SigType" SG_ 2566628094 TotalDCInputEnergy 1;
BA_ "SPN" SG_ 2566628094 TotalDCInputCharge 9259;
BA_ "SigType" SG_ 2566628094 TotalDCInputCharge 1;
BA_ "SPN" SG_ 2566627838 ACSideDefaultFreqCmdSetting 9539;
BA_ "SigType" SG_ 2566627838 ACSideDefaultFreqCmdSetting 1;
BA_ "SPN" SG_ 2566627838 DCSideCurMinLmtSetting 9538;
BA_ "SigType" SG_ 2566627838 DCSideCurMinLmtSetting 1;
BA_ "SPN" SG_ 2566627838 DCSideVMaxLmtSetting 9537;
BA_ "SigType" SG_ 2566627838 DCSideVMaxLmtSetting 1;
BA_ "SPN" SG_ 2566627838 ACSideRMSCurMaxLmtSetting 9258;
BA_ "SigType" SG_ 2566627838 ACSideRMSCurMaxLmtSetting 1;
BA_ "SPN" SG_ 2566627838 ACSideRMSVMaxLmtSetting 9257;
BA_ "SigType" SG_ 2566627838 ACSideRMSVMaxLmtSetting 1;
BA_ "SPN" SG_ 2566627838 DCSideCurMaxLmtSetting 9256;
BA_ "SigType" SG_ 2566627838 DCSideCurMaxLmtSetting 1;
BA_ "SPN" SG_ 2566627838 DCSideVMinLmtSetting 9255;
BA_ "SigType" SG_ 2566627838 DCSideVMinLmtSetting 1;
BA_ "SPN" SG_ 2365300990 DefaultFreqReq 9524;
BA_ "SigType" SG_ 2365300990 DefaultFreqReq 1;
BA_ "SPN" SG_ 2365300990 RMSCurMaxLmtReq 9254;
BA_ "SigType" SG_ 2365300990 RMSCurMaxLmtReq 1;
BA_ "SPN" SG_ 2365300990 RMSVMaxLmtReq 9253;
BA_ "SigType" SG_ 2365300990 RMSVMaxLmtReq 1;
BA_ "SPN" SG_ 2365300734 CurMinLmtReq 9536;
BA_ "SigType" SG_ 2365300734 CurMinLmtReq 1;
BA_ "SPN" SG_ 2365300734 VMaxLmtReq 9535;
BA_ "SigType" SG_ 2365300734 VMaxLmtReq 1;
BA_ "SPN" SG_ 2365300734 CurMaxLmtReq 9252;
BA_ "SigType" SG_ 2365300734 CurMaxLmtReq 1;
BA_ "SPN" SG_ 2365300734 VMinLmtReq 9251;
BA_ "SigType" SG_ 2365300734 VMinLmtReq 1;
BA_ "SPN" SG_ 2566627070 CoolantOutTemp 9235;
BA_ "SigType" SG_ 2566627070 CoolantOutTemp 1;
BA_ "SPN" SG_ 2566627070 CoolantInTemp 9234;
BA_ "SigType" SG_ 2566627070 CoolantInTemp 1;
BA_ "SPN" SG_ 2566627070 PwrETemp 9233;
BA_ "SigType" SG_ 2566627070 PwrETemp 1;
BA_ "SPN" SG_ 2566627070 InverterEFilterTemp 9232;
BA_ "SigType" SG_ 2566627070 InverterEFilterTemp 1;
BA_ "SPN" SG_ 2566627070 CtrlTemp 9231;
BA_ "SigType" SG_ 2566627070 CtrlTemp 1;
BA_ "SPN" SG_ 2566626814 TotalDCInputEnergy 9230;
BA_ "SigType" SG_ 2566626814 TotalDCInputEnergy 1;
BA_ "SPN" SG_ 2566626814 TotalDCInputCharge 9229;
BA_ "SigType" SG_ 2566626814 TotalDCInputCharge 1;
BA_ "SPN" SG_ 2566626558 ACSideDefaultFreqCmdSetting 9533;
BA_ "SigType" SG_ 2566626558 ACSideDefaultFreqCmdSetting 1;
BA_ "SPN" SG_ 2566626558 DCSideCurMinLmtSetting 9532;
BA_ "SigType" SG_ 2566626558 DCSideCurMinLmtSetting 1;
BA_ "SPN" SG_ 2566626558 DCSideVMaxLmtSetting 9531;
BA_ "SigType" SG_ 2566626558 DCSideVMaxLmtSetting 1;
BA_ "SPN" SG_ 2566626558 ACSideRMSCurMaxLmtSetting 9228;
BA_ "SigType" SG_ 2566626558 ACSideRMSCurMaxLmtSetting 1;
BA_ "SPN" SG_ 2566626558 ACSideRMSVMaxLmtSetting 9227;
BA_ "SigType" SG_ 2566626558 ACSideRMSVMaxLmtSetting 1;
BA_ "SPN" SG_ 2566626558 DCSideCurMaxLmtSetting 9226;
BA_ "SigType" SG_ 2566626558 DCSideCurMaxLmtSetting 1;
BA_ "SPN" SG_ 2566626558 DCSideVMinLmtSetting 9225;
BA_ "SigType" SG_ 2566626558 DCSideVMinLmtSetting 1;
BA_ "SPN" SG_ 2365299710 DefaultFreqReq 9523;
BA_ "SigType" SG_ 2365299710 DefaultFreqReq 1;
BA_ "SPN" SG_ 2365299710 RMSCurMaxLmtReq 9224;
BA_ "SigType" SG_ 2365299710 RMSCurMaxLmtReq 1;
BA_ "SPN" SG_ 2365299710 RMSVMaxLmtReq 9223;
BA_ "SigType" SG_ 2365299710 RMSVMaxLmtReq 1;
BA_ "SPN" SG_ 2365299454 CurMinLmtReq 9530;
BA_ "SigType" SG_ 2365299454 CurMinLmtReq 1;
BA_ "SPN" SG_ 2365299454 VMaxLmtReq 9529;
BA_ "SigType" SG_ 2365299454 VMaxLmtReq 1;
BA_ "SPN" SG_ 2365299454 CurMaxLmtReq 9222;
BA_ "SigType" SG_ 2365299454 CurMaxLmtReq 1;
BA_ "SPN" SG_ 2365299454 VMinLmtReq 9221;
BA_ "SigType" SG_ 2365299454 VMinLmtReq 1;
BA_ "SPN" SG_ 2566625790 CoolantOutTemp 9208;
BA_ "SigType" SG_ 2566625790 CoolantOutTemp 1;
BA_ "SPN" SG_ 2566625790 CoolantInTemp 9207;
BA_ "SigType" SG_ 2566625790 CoolantInTemp 1;
BA_ "SPN" SG_ 2566625790 PwrETemp 9206;
BA_ "SigType" SG_ 2566625790 PwrETemp 1;
BA_ "SPN" SG_ 2566625790 InverterEFilterTemp 9205;
BA_ "SigType" SG_ 2566625790 InverterEFilterTemp 1;
BA_ "SPN" SG_ 2566625790 CtrlTemp 9204;
BA_ "SigType" SG_ 2566625790 CtrlTemp 1;
BA_ "SPN" SG_ 2633734398 EngActualExh2O2 9367;
BA_ "SigType" SG_ 2633734398 EngActualExh2O2 1;
BA_ "SPN" SG_ 2566625278 SLIBatPack1Bat4CapacitySetting 9371;
BA_ "SigType" SG_ 2566625278 SLIBatPack1Bat4CapacitySetting 1;
BA_ "SPN" SG_ 2566625278 SLIBatPack1Bat3CapacitySetting 9370;
BA_ "SigType" SG_ 2566625278 SLIBatPack1Bat3CapacitySetting 1;
BA_ "SPN" SG_ 2566625278 SLIBatPack1Bat2CapacitySetting 9369;
BA_ "SigType" SG_ 2566625278 SLIBatPack1Bat2CapacitySetting 1;
BA_ "SPN" SG_ 2566625278 SLIBatPack1Bat1CapacitySetting 9368;
BA_ "SigType" SG_ 2566625278 SLIBatPack1Bat1CapacitySetting 1;
BA_ "SPN" SG_ 2566625022 InstantaneousEstEngPwrRateLmt 9375;
BA_ "SigType" SG_ 2566625022 InstantaneousEstEngPwrRateLmt 1;
BA_ "SPN" SG_ 2566624766 IdleMnmgtActiveTotalTime 9377;
BA_ "SigType" SG_ 2566624766 IdleMnmgtActiveTotalTime 1;
BA_ "SPN" SG_ 2566624510 EGR1CoolerInPress 9379;
BA_ "SigType" SG_ 2566624510 EGR1CoolerInPress 1;
BA_ "SPN" SG_ 2365297662 OneCtrlInputSLIV 9559;
BA_ "SigType" SG_ 2365297662 OneCtrlInputSLIV 1;
BA_ "SPN" SG_ 2365297662 OneCtrlInputIgntV 9558;
BA_ "SigType" SG_ 2365297662 OneCtrlInputIgntV 1;
BA_ "SPN" SG_ 2365297406 TwoCtrlInputSLIV 9561;
BA_ "SigType" SG_ 2365297406 TwoCtrlInputSLIV 1;
BA_ "SPN" SG_ 2365297406 TwoCtrlInputIgntV 9560;
BA_ "SigType" SG_ 2365297406 TwoCtrlInputIgntV 1;
BA_ "SPN" SG_ 2365297150 ThreeCtrlInputSLIV 9563;
BA_ "SigType" SG_ 2365297150 ThreeCtrlInputSLIV 1;
BA_ "SPN" SG_ 2365297150 ThreeCtrlInputIgntV 9562;
BA_ "SigType" SG_ 2365297150 ThreeCtrlInputIgntV 1;
BA_ "SPN" SG_ 2365296894 FourCtrlInputSLIV 9565;
BA_ "SigType" SG_ 2365296894 FourCtrlInputSLIV 1;
BA_ "SPN" SG_ 2365296894 FourCtrlInputIgntV 9564;
BA_ "SigType" SG_ 2365296894 FourCtrlInputIgntV 1;
BA_ "SPN" SG_ 2566623230 TripEstFuelSaved 9571;
BA_ "SigType" SG_ 2566623230 TripEstFuelSaved 1;
BA_ "SPN" SG_ 2566623230 TotalEstFuelSaved 9570;
BA_ "SigType" SG_ 2566623230 TotalEstFuelSaved 1;
BA_ "SPN" SG_ 2566622974 TripFuelUsed 9573;
BA_ "SigType" SG_ 2566622974 TripFuelUsed 1;
BA_ "SPN" SG_ 2566622974 TotalFuelUsed 9572;
BA_ "SigType" SG_ 2566622974 TotalFuelUsed 1;
BA_ "SPN" SG_ 2566622718 TripHoursActive 9575;
BA_ "SigType" SG_ 2566622718 TripHoursActive 1;
BA_ "SPN" SG_ 2566622718 TotalHoursActive 9574;
BA_ "SigType" SG_ 2566622718 TotalHoursActive 1;
BA_ "SPN" SG_ 2566622462 Percent 9577;
BA_ "SigType" SG_ 2566622462 Percent 1;
BA_ "SPN" SG_ 2566622462 RateAbsolute 9576;
BA_ "SigType" SG_ 2566622462 RateAbsolute 1;
BA_ "SPN" SG_ 2566622206 TripHoursInactive 9579;
BA_ "SigType" SG_ 2566622206 TripHoursInactive 1;
BA_ "SPN" SG_ 2566622206 TotalHoursInactive 9578;
BA_ "SigType" SG_ 2566622206 TotalHoursInactive 1;
BA_ "SPN" SG_ 2365295358 LvlNegToChassisGroundV 9581;
BA_ "SigType" SG_ 2365295358 LvlNegToChassisGroundV 1;
BA_ "SPN" SG_ 2365295358 BusVNegToChassisGroundV 9580;
BA_ "SigType" SG_ 2365295358 BusVNegToChassisGroundV 1;
BA_ "SPN" SG_ 2566621694 OilPress2 9653;
BA_ "SigType" SG_ 2566621694 OilPress2 1;
BA_ "SPN" SG_ 2566621438 SlowVesselModeLampStatus 9690;
BA_ "SigType" SG_ 2566621438 SlowVesselModeLampStatus 5;
BA_ "SPN" SG_ 2566621438 GearLockoutLampStatus 9675;
BA_ "SigType" SG_ 2566621438 GearLockoutLampStatus 5;
BA_ "SPN" SG_ 2566621438 EngThrotLeverSynchLampStatus 9674;
BA_ "SigType" SG_ 2566621438 EngThrotLeverSynchLampStatus 5;
BA_ "SPN" SG_ 2566621438 TrollingModeLampStatus 9673;
BA_ "SigType" SG_ 2566621438 TrollingModeLampStatus 5;
BA_ "SPN" SG_ 2566621438 OpStationActiveLampStatus 9672;
BA_ "SigType" SG_ 2566621438 OpStationActiveLampStatus 5;
BA_ "SPN" SG_ 2566621438 SlowVesselModeButtonStatus 9671;
BA_ "SigType" SG_ 2566621438 SlowVesselModeButtonStatus 5;
BA_ "SPN" SG_ 2566621438 GearLockoutButtonStatus 9670;
BA_ "SigType" SG_ 2566621438 GearLockoutButtonStatus 5;
BA_ "SPN" SG_ 2566621438 EngThrotLeverSynchButtonStatus 9669;
BA_ "SigType" SG_ 2566621438 EngThrotLeverSynchButtonStatus 5;
BA_ "SPN" SG_ 2566621438 TrollingModeButtonStatus 9668;
BA_ "SigType" SG_ 2566621438 TrollingModeButtonStatus 5;
BA_ "SPN" SG_ 2566621438 OpStationActiveButtonStatus 9667;
BA_ "SigType" SG_ 2566621438 OpStationActiveButtonStatus 5;
BA_ "SPN" SG_ 2566621438 StationGearPosMatch 9666;
BA_ "SigType" SG_ 2566621438 StationGearPosMatch 5;
BA_ "SPN" SG_ 2566621438 StationThrotPosMatch 9665;
BA_ "SigType" SG_ 2566621438 StationThrotPosMatch 5;
BA_ "SPN" SG_ 2566620670 ShutdownReason 9679;
BA_ "SPN" SG_ 2566620670 RestartReason 9678;
BA_ "SPN" SG_ 2566620670 Status 9677;
BA_ "SPN" SG_ 2364620286 LaneCenteringSysStatus 9759;
BA_ "SPN" SG_ 2364620286 LaneCenteringIndEnableSt 9758;
BA_ "SigType" SG_ 2364620286 LaneCenteringIndEnableSt 5;
BA_ "SPN" SG_ 2364620286 DriverPref 9757;
BA_ "SPN" SG_ 2364620286 LaneKeepingAssistSysSt 9756;
BA_ "SPN" SG_ 2364620286 LaneKeepingAssistIndEnableStatus 9755;
BA_ "SigType" SG_ 2364620286 LaneKeepingAssistIndEnableStatus 5;
BA_ "SPN" SG_ 2364620286 LaneKeepingAssistStatusLeftSide 9754;
BA_ "SPN" SG_ 2364620286 LaneKeepingAssistStatusRightSide 9753;
BA_ "SPN" SG_ 2364620030 Two0StartAct 9630;
BA_ "SigType" SG_ 2364620030 Two0StartAct 1;
BA_ "SPN" SG_ 2364620030 One9StartAct 9629;
BA_ "SigType" SG_ 2364620030 One9StartAct 1;
BA_ "SPN" SG_ 2364620030 One8StartAct 9628;
BA_ "SigType" SG_ 2364620030 One8StartAct 1;
BA_ "SPN" SG_ 2364620030 One7StartAct 9627;
BA_ "SigType" SG_ 2364620030 One7StartAct 1;
BA_ "SPN" SG_ 2364619774 One6StartAct 9626;
BA_ "SigType" SG_ 2364619774 One6StartAct 1;
BA_ "SPN" SG_ 2364619774 One5StartAct 9625;
BA_ "SigType" SG_ 2364619774 One5StartAct 1;
BA_ "SPN" SG_ 2364619774 One4StartAct 9624;
BA_ "SigType" SG_ 2364619774 One4StartAct 1;
BA_ "SPN" SG_ 2364619774 One3StartAct 9623;
BA_ "SigType" SG_ 2364619774 One3StartAct 1;
BA_ "SPN" SG_ 2364619518 One2StartAct 9622;
BA_ "SigType" SG_ 2364619518 One2StartAct 1;
BA_ "SPN" SG_ 2364619518 One1StartAct 9621;
BA_ "SigType" SG_ 2364619518 One1StartAct 1;
BA_ "SPN" SG_ 2364619518 One0StartAct 9620;
BA_ "SigType" SG_ 2364619518 One0StartAct 1;
BA_ "SPN" SG_ 2364619518 NineStartAct 9619;
BA_ "SigType" SG_ 2364619518 NineStartAct 1;
BA_ "SPN" SG_ 2364619262 EightStartAct 9618;
BA_ "SigType" SG_ 2364619262 EightStartAct 1;
BA_ "SPN" SG_ 2364619262 SevenStartAct 9617;
BA_ "SigType" SG_ 2364619262 SevenStartAct 1;
BA_ "SPN" SG_ 2364619262 SixStartAct 9616;
BA_ "SigType" SG_ 2364619262 SixStartAct 1;
BA_ "SPN" SG_ 2364619262 FiveStartAct 9615;
BA_ "SigType" SG_ 2364619262 FiveStartAct 1;
BA_ "SPN" SG_ 2364619006 FourStartAct 9614;
BA_ "SigType" SG_ 2364619006 FourStartAct 1;
BA_ "SPN" SG_ 2364619006 ThreeStartAct 9613;
BA_ "SigType" SG_ 2364619006 ThreeStartAct 1;
BA_ "SPN" SG_ 2364619006 TwoStartAct 9612;
BA_ "SigType" SG_ 2364619006 TwoStartAct 1;
BA_ "SPN" SG_ 2364619006 OneStartAct 9611;
BA_ "SigType" SG_ 2364619006 OneStartAct 1;
BA_ "SPN" SG_ 2364618750 Two0Dur 9610;
BA_ "SigType" SG_ 2364618750 Two0Dur 1;
BA_ "SPN" SG_ 2364618750 One9Dur 9609;
BA_ "SigType" SG_ 2364618750 One9Dur 1;
BA_ "SPN" SG_ 2364618750 One8Dur 9608;
BA_ "SigType" SG_ 2364618750 One8Dur 1;
BA_ "SPN" SG_ 2364618750 One7Dur 9607;
BA_ "SigType" SG_ 2364618750 One7Dur 1;
BA_ "SPN" SG_ 2364618494 One6Dur 9606;
BA_ "SigType" SG_ 2364618494 One6Dur 1;
BA_ "SPN" SG_ 2364618494 One5Dur 9605;
BA_ "SigType" SG_ 2364618494 One5Dur 1;
BA_ "SPN" SG_ 2364618494 One4Dur 9604;
BA_ "SigType" SG_ 2364618494 One4Dur 1;
BA_ "SPN" SG_ 2364618494 One3Dur 9603;
BA_ "SigType" SG_ 2364618494 One3Dur 1;
BA_ "SPN" SG_ 2364618238 One2Dur 9602;
BA_ "SigType" SG_ 2364618238 One2Dur 1;
BA_ "SPN" SG_ 2364618238 One1Dur 9601;
BA_ "SigType" SG_ 2364618238 One1Dur 1;
BA_ "SPN" SG_ 2364618238 One0Dur 9600;
BA_ "SigType" SG_ 2364618238 One0Dur 1;
BA_ "SPN" SG_ 2364618238 NineDur 9599;
BA_ "SigType" SG_ 2364618238 NineDur 1;
BA_ "SPN" SG_ 2364617982 EightDur 9598;
BA_ "SigType" SG_ 2364617982 EightDur 1;
BA_ "SPN" SG_ 2364617982 SevenDur 9597;
BA_ "SigType" SG_ 2364617982 SevenDur 1;
BA_ "SPN" SG_ 2364617982 SixDur 9596;
BA_ "SigType" SG_ 2364617982 SixDur 1;
BA_ "SPN" SG_ 2364617982 FiveDur 9595;
BA_ "SigType" SG_ 2364617982 FiveDur 1;
BA_ "SPN" SG_ 2364617726 FourDur 9594;
BA_ "SigType" SG_ 2364617726 FourDur 1;
BA_ "SPN" SG_ 2364617726 ThreeDur 9593;
BA_ "SigType" SG_ 2364617726 ThreeDur 1;
BA_ "SPN" SG_ 2364617726 TwoDur 9592;
BA_ "SigType" SG_ 2364617726 TwoDur 1;
BA_ "SPN" SG_ 2364617726 OneDur 9591;
BA_ "SigType" SG_ 2364617726 OneDur 1;
BA_ "SPN" SG_ 2565944062 PLedDueToUndefinedReason 9356;
BA_ "SigType" SG_ 2565944062 PLedDueToUndefinedReason 5;
BA_ "SPN" SG_ 2565944062 PLedDueToRateOfChangeLmt 9355;
BA_ "SigType" SG_ 2565944062 PLedDueToRateOfChangeLmt 5;
BA_ "SPN" SG_ 2565944062 PLedDueToPwrETemp 9354;
BA_ "SigType" SG_ 2565944062 PLedDueToPwrETemp 5;
BA_ "SPN" SG_ 2565944062 PLedDueToEFilterTemp 9353;
BA_ "SigType" SG_ 2565944062 PLedDueToEFilterTemp 5;
BA_ "SPN" SG_ 2565944062 PLedDueToCtrlTemp 9352;
BA_ "SigType" SG_ 2565944062 PLedDueToCtrlTemp 5;
BA_ "SPN" SG_ 2565944062 FreqCmdExceedsMax 9351;
BA_ "SigType" SG_ 2565944062 FreqCmdExceedsMax 5;
BA_ "SPN" SG_ 2565944062 FreqCmdBelowMin 9350;
BA_ "SigType" SG_ 2565944062 FreqCmdBelowMin 5;
BA_ "SPN" SG_ 2565944062 PLedDueToDCSideVMin 9349;
BA_ "SigType" SG_ 2565944062 PLedDueToDCSideVMin 5;
BA_ "SPN" SG_ 2565944062 PLedDueToACSideRMSCur 9348;
BA_ "SigType" SG_ 2565944062 PLedDueToACSideRMSCur 5;
BA_ "SPN" SG_ 2565944062 PLedDueToDCSideCur 9347;
BA_ "SigType" SG_ 2565944062 PLedDueToDCSideCur 5;
BA_ "SPN" SG_ 2364617214 SLIV 9346;
BA_ "SigType" SG_ 2364617214 SLIV 1;
BA_ "SPN" SG_ 2364617214 IgntV 9345;
BA_ "SigType" SG_ 2364617214 IgntV 1;
BA_ "SPN" SG_ 2364616958 DCSideNegToChassisGroundV 9586;
BA_ "SigType" SG_ 2364616958 DCSideNegToChassisGroundV 1;
BA_ "SPN" SG_ 2364616958 DCSideCur 9344;
BA_ "SigType" SG_ 2364616958 DCSideCur 1;
BA_ "SPN" SG_ 2364616958 DCSideV 9343;
BA_ "SigType" SG_ 2364616958 DCSideV 1;
BA_ "SPN" SG_ 2364616958 DCSidePwr 9342;
BA_ "SigType" SG_ 2364616958 DCSidePwr 1;
BA_ "SPN" SG_ 2565943294 HVILStatus 9336;
BA_ "SigType" SG_ 2565943294 HVILStatus 5;
BA_ "SPN" SG_ 2565943294 LoadshedReq 9335;
BA_ "SigType" SG_ 2565943294 LoadshedReq 5;
BA_ "SPN" SG_ 2565943294 OperationalStatus 9334;
BA_ "SPN" SG_ 2565943294 ACSideRMSCur 9333;
BA_ "SigType" SG_ 2565943294 ACSideRMSCur 1;
BA_ "SPN" SG_ 2565943294 ACSidePwr 9332;
BA_ "SigType" SG_ 2565943294 ACSidePwr 1;
BA_ "SPN" SG_ 2565943294 ACSideRMSV 9331;
BA_ "SigType" SG_ 2565943294 ACSideRMSV 1;
BA_ "SPN" SG_ 2565943294 Freq 9330;
BA_ "SigType" SG_ 2565943294 Freq 1;
BA_ "SPN" SG_ 2565943038 ACSideMotorStartingRMSVReq 9552;
BA_ "SigType" SG_ 2565943038 ACSideMotorStartingRMSVReq 1;
BA_ "SPN" SG_ 2565943038 OperationalCmd 9329;
BA_ "SigType" SG_ 2565943038 OperationalCmd 5;
BA_ "SPN" SG_ 2565943038 Device2Status 9328;
BA_ "SPN" SG_ 2565943038 Device1Status 9327;
BA_ "SPN" SG_ 2565943038 FreqCmd 9326;
BA_ "SigType" SG_ 2565943038 FreqCmd 1;
BA_ "SPN" SG_ 2565943038 DeviceFreqRateOfChangeLmt 9325;
BA_ "SigType" SG_ 2565943038 DeviceFreqRateOfChangeLmt 1;
BA_ "SPN" SG_ 2565943038 DeviceRatedRMSV 9324;
BA_ "SigType" SG_ 2565943038 DeviceRatedRMSV 1;
BA_ "SPN" SG_ 2565943038 DeviceRatedFreq 9323;
BA_ "SigType" SG_ 2565943038 DeviceRatedFreq 1;
BA_ "SPN" SG_ 2565943038 DeviceMinFreq 9322;
BA_ "SigType" SG_ 2565943038 DeviceMinFreq 1;
BA_ "SPN" SG_ 2565943038 DeviceMaxFreq 9321;
BA_ "SigType" SG_ 2565943038 DeviceMaxFreq 1;
VAL_ 3221225472 TirePressThresholdDetection 7 "Not available" 6 "Error indicator" 5 "Not defined" 4 "Extreme under pressure" 3 "Under pressure" 2 "No warning pressure" 1 "Over pressure" 0 "Extreme over pressure" ;
VAL_ 3221225472 CTIWheelEndElectricalFault 3 "Not Supported" 2 "Error" 1 "Not Defined" 0 "Ok  No Fault" ;
VAL_ 3221225472 CTITireStatus 3 "Not Supported" 2 "Error" 1 "Tire leak detected" 0 "Ok no fault" ;
VAL_ 3221225472 CTIWheelSensorStatus 3 "Not Supported" 2 "Not Defined" 1 "On tire is polled" 0 "Off / isolated from CTI Pressure Controller" ;
VAL_ 3221225472 EngTurningGearEngaged 1 "Engaged" 0 "Not engaged" 3 "Not available" 2 "Error" ;
VAL_ 2633748222 SPNModifiedStatus 3 "Not available" 2 "SPN뭩 receive status could be modified as requested." 1 "SPN뭩 receive status was not requested to be modified." 0 "SPN뭩 receive status could not be modified" ;
VAL_ 2633748222 SPNSA 255 "The Configurable ECU will process the Configurable Receive SPN from any source address on the port identified in SPN 8842." 254 "No source address has been configured for this Configurable Receive SPN." ;
VAL_ 2633748222 PortCmdStatus 7 "Not available" 6 "SAE Reserved" 5 "SAE Reserved" 4 "SAE Reserved" 3 "SAE Reserved" 2 "No Configurable SPNs exist for the port identified in SPN 8842." 1 "Negative Acknowledgment" 0 "Positive Acknowledgment" ;
VAL_ 2633748222 PortPendingChangesStatus 1 "Receive changes are pending for one or more supported SPNs on the port identified in SPN 8842." 0 "No pending changes to the receive status for any supported SPNs for the port identified in SPN 8842." ;
VAL_ 2633748222 Port 15 "SAE Reserved" 14 "SAE Reserved" 13 "SAE Reserved" 12 "SAE Reserved" 11 "SAE Reserved" 10 "Port 10" 9 "Port 9" 8 "Port 8" 7 "Port 7" 6 "Port 6" 5 "Port 5" 4 "Port 4" 3 "Port 3" 2 "Port 2" 1 "Port 1" 0 "Current port" ;
VAL_ 2566639102 PlungerFiringOrderSetting 15 "Not available" 14 "Error" 13 "Reserved" 12 "Reserved" 11 "Reserved" 10 "Reserved" 9 "Reserved" 8 "Reserved" 7 "Reserved" 6 "Reserved" 5 "Reserved" 4 "Reserved" 3 "Reserved" 2 "Reserved" 1 "Firing order 1-5-2-3-4" 0 "Firing order 1-2-3" ;
VAL_ 2566632190 DisPressCalSetPointStatus 3 "Not available" 2 "Error" 1 "OK" 0 "Not OK" ;
VAL_ 2566632190 DisPressCalSetPoint 15 "Not Available" 14 "Error" 13 "Reserved" 12 "Reset Calibration" 11 "Correction Point" 10 "End Point" 9 "Calibration Reference Point 9" 8 "Calibration Reference Point 8" 7 "Calibration Reference Point 7" 6 "Calibration Reference Point 6" 5 "Calibration Reference Point 5" 4 "Calibration Reference Point 4" 3 "Calibration Reference Point 3" 2 "Calibration Reference Point 2" 1 "Calibration Reference Point 1" 0 "Zero Point" ;
VAL_ 2566632190 SuctionPressCalSetPointStatus 3 "Not available" 2 "Error" 1 "OK" 0 "Not OK" ;
VAL_ 2566632190 SuctionPressCalSetPoint 15 "Not Available" 14 "Error" 13 "Reserved" 12 "Reset Calibration" 11 "Correction Point" 10 "End Point" 9 "Calibration Reference Point 9" 8 "Calibration Reference Point 8" 7 "Calibration Reference Point 7" 6 "Calibration Reference Point 6" 5 "Calibration Reference Point 5" 4 "Calibration Reference Point 4" 3 "Calibration Reference Point 3" 2 "Calibration Reference Point 2" 1 "Calibration Reference Point 1" 0 "Zero Point" ;
VAL_ 2566621438 SlowVesselModeLampStatus 3 "Not Available" 2 "Error" 1 "On" 0 "Off" ;
VAL_ 2566621438 GearLockoutLampStatus 3 "Not Available" 2 "Error" 1 "On" 0 "Off" ;
VAL_ 2566621438 EngThrotLeverSynchLampStatus 3 "Not Available" 2 "Error" 1 "On" 0 "Off" ;
VAL_ 2566621438 TrollingModeLampStatus 3 "Not Available" 2 "Error" 1 "On" 0 "Off" ;
VAL_ 2566621438 OpStationActiveLampStatus 3 "Not Available" 2 "Error" 1 "On" 0 "Off" ;
VAL_ 2566621438 SlowVesselModeButtonStatus 3 "Not Available" 2 "Error" 1 "Button pressed" 0 "Button not pressed" ;
VAL_ 2566621438 GearLockoutButtonStatus 3 "Not Available" 2 "Error" 1 "Button pressed" 0 "Button not pressed" ;
VAL_ 2566621438 EngThrotLeverSynchButtonStatus 3 "Not Available" 2 "Error" 1 "Button pressed" 0 "Button not pressed" ;
VAL_ 2566621438 TrollingModeButtonStatus 3 "Not Available" 2 "Error" 1 "Button pressed" 0 "Button not pressed" ;
VAL_ 2566621438 OpStationActiveButtonStatus 3 "Not Available" 2 "Error" 1 "Button pressed" 0 "Button not pressed" ;
VAL_ 2566621438 StationGearPosMatch 3 "Not Available or Not Installed" 2 "Error" 1 "Not in neutral" 0 "Neutral" ;
VAL_ 2566621438 StationThrotPosMatch 3 "Not Available or Not Installed" 2 "Error" 1 "Throttle positions match" 0 "Throttle positions do not match" ;
VAL_ 2566620670 ShutdownReason 15 "Not available" 14 "Error" 13 "Reserved" 12 "Reserved" 11 "Reserved" 10 "Reserved" 9 "Reserved" 8 "Reserved" 7 "Reserved" 6 "Battery pack #2 state of charge" 5 "Battery pack #1 state of charge" 4 "Power end lube oil temperature" 3 "Transmission oil temperature" 2 "Battery voltage" 1 "Engine coolant temperature" 0 "Operator input request" ;
VAL_ 2566620670 RestartReason 15 "Not available" 14 "Error" 13 "Reserved" 12 "Reserved" 11 "Reserved" 10 "Reserved" 9 "Reserved" 8 "Reserved" 7 "Reserved" 6 "Low battery pack #2 state of charge" 5 "Low battery pack #1 state of charge" 4 "Low power end lube oil temperature" 3 "Low transmission oil temperature" 2 "Low battery voltage" 1 "Low engine coolant temperature" 0 "Operator input request" ;
VAL_ 2566620670 Status 15 "Not Available" 14 "Error" 13 "Reserved" 12 "Reserved" 11 "Reserved" 10 "Reserved" 9 "Auto start inhibited" 8 "Restart conditions pending" 7 "Restart conditions not met" 6 "Shutdown" 5 "Shutdown conditions pending" 4 "Shutdown conditions not met" 3 "Activation conditions not met" 2 "Disabled" 1 "Locked" 0 "Off" ;
VAL_ 2364620286 LaneCenteringSysStatus 15 "Not Available" 14 "Error" 13 "Reserved" 12 "Reserved" 11 "Reserved" 10 "Reserved" 9 "Reserved" 8 "Reserved" 7 "Reserved" 6 "Reserved" 5 "Lane Centering System is actuating" 4 "Lane Centering suppressed by operator behavior" 3 "System is ready" 2 "System is deactivated by driver" 1 "System is temporarily not available" 0 "System is not ready" ;
VAL_ 2364620286 LaneCenteringIndEnableSt 3 "Not available" 2 "Error" 1 "Lane Centering Indication enabled" 0 "Lane Centering Indication disabled" ;
VAL_ 2364620286 DriverPref 7 "Not available/Not valid" 6 "Error" 5 "Active Steering Mode #6" 4 "Active Steering Mode #5" 3 "Active Steering Mode #4" 2 "Active Steering Mode #3" 1 "Active Steering Mode #2" 0 "Active Steering Mode #1" ;
VAL_ 2364620286 LaneKeepingAssistSysSt 15 "Not Available" 14 "Error" 13 "Reserved" 12 "Reserved" 11 "Reserved" 10 "Reserved" 9 "Reserved" 8 "Reserved" 7 "Reserved" 6 "Reserved" 5 "System is actuating" 4 "Active lane keeping suppressed by operator behavior" 3 "System is ready" 2 "System is deactivated by driver" 1 "System is temporarily not available" 0 "System is not ready" ;
VAL_ 2364620286 LaneKeepingAssistIndEnableStatus 3 "Not available" 2 "Error" 1 "Lane Keeping Assist enabled" 0 "Lane Keeping Assist disabled" ;
VAL_ 2364620286 LaneKeepingAssistStatusLeftSide 7 "Not available" 6 "Error" 5 "Reserved" 4 "BlindSpot Assist Active for Left Side" 3 "Lane Keeping Assist Active for Left Side" 2 "Lane Keeping Assist Suppressed for Left Side" 1 "Lane Keeping Assist Available for Left Side" 0 "Lane Keeping Assist Not Available for Left Side" ;
VAL_ 2364620286 LaneKeepingAssistStatusRightSide 7 "Not available" 6 "Error" 5 "Reserved" 4 "BlindSpot Assist Active for Right Side" 3 "Lane Keeping Assist Active for Right Side" 2 "Lane Keeping Assist Suppressed for Right Side" 1 "Lane Keeping Assist Available for Right Side" 0 "Lane Keeping Assist Not Available for Right Side" ;
VAL_ 2565944062 PLedDueToUndefinedReason 3 "Not Available" 2 "Error" 1 "Power limited for this reason" 0 "No power limit for this reason" ;
VAL_ 2565944062 PLedDueToRateOfChangeLmt 3 "Not Available" 2 "Error" 1 "Frequency limited for this reason" 0 "No frequency limit for this reason" ;
VAL_ 2565944062 PLedDueToPwrETemp 3 "Not Available" 2 "Error" 1 "Frequency limited for this reason" 0 "No frequency limit for this reason" ;
VAL_ 2565944062 PLedDueToEFilterTemp 3 "Not Available" 2 "Error" 1 "Frequency limited for this reason" 0 "No frequency limit for this reason" ;
VAL_ 2565944062 PLedDueToCtrlTemp 3 "Not Available" 2 "Error" 1 "Power limited for this reason" 0 "No power limit for this reason" ;
VAL_ 2565944062 FreqCmdExceedsMax 3 "Not Available" 2 "Error" 1 "Frequency limited for this reason" 0 "No frequency limit for this reason" ;
VAL_ 2565944062 FreqCmdBelowMin 3 "Not Available" 2 "Error" 1 "Frequency limited for this reason" 0 "No frequency limit for this reason" ;
VAL_ 2565944062 PLedDueToDCSideVMin 3 "Not Available" 2 "Error" 1 "Power limited for this reason" 0 "No power limit for this reason" ;
VAL_ 2565944062 PLedDueToACSideRMSCur 3 "Not Available" 2 "Error" 1 "Power limited for this reason" 0 "No power limit for this reason" ;
VAL_ 2565944062 PLedDueToDCSideCur 3 "Not Available" 2 "Error" 1 "Power limited for this reason" 0 "No power limit for this reason" ;
VAL_ 2565943294 HVILStatus 3 "Not Available" 2 "Error" 1 "HVIL Open" 0 "HVIL Closed" ;
VAL_ 2565943294 LoadshedReq 3 "Don't Care/Take No Action" 2 "Loadshed Requested,  Shutdown Imminent" 1 "Loadshed Requested" 0 "No Loadshed Requested" ;
VAL_ 2565943294 OperationalStatus 7 "Not Available" 6 "Error" 5 "Reserved" 4 "Normal Power Down in Process" 3 "Output Faulted Off" 2 "Output Faulted On" 1 "Output Enabled" 0 "Output Disabled" ;
VAL_ 2565943038 OperationalCmd 3 "Not Available" 2 "Power down DC/AC Accessory Inverter Controller" 1 "Enable DC/AC Accessory Inverter Output" 0 "Disable DC/AC Accessory Inverter Output" ;
VAL_ 2565943038 Device2Status 7 "Not Available" 6 "Error" 5 "Reserved for SAE Assignment" 4 "Reserved for SAE Assignment" 3 "Faulted Off" 2 "Faulted On" 1 "Off" 0 "On" ;
VAL_ 2565943038 Device1Status 7 "Not Available" 6 "Error" 5 "Reserved for SAE Assignment" 4 "Reserved for SAE Assignment" 3 "Faulted Off" 2 "Faulted On" 1 "Off" 0 "On" ;
